VERSION "$Format:%h$"

NS_ :

BS_:

BU_: APB APP APS BCCEN BDY DAS DBG EAS EPAS EPAS2 EPAS3S EPB EPBM ESP GTW GTWU IBST IC MCU OCS PARK PARK3 RADAR RCM RT3000 SCCM SDM SEC TAS TAS2 TAS2DBG TOOL TPMS VCSEATD VCSEATP

BO_ 841 DAS_warningMatrix3: 8 DAS
 SG_ DAS_w193_camWindshieldUnclean : 0|1@1+ (1,0) [0|0] "" GTW,MCU
 SG_ DAS_w194_accDriverResumeRqrd : 1|1@1+ (1,0) [0|0] "" GTW,MCU
 SG_ DAS_w195_scwUnavailable : 2|1@1+ (1,0) [0|0] "" GTW,MCU
 SG_ DAS_w196_stopSignWarning : 3|1@1+ (1,0) [0|0] "" GTW,MCU
 SG_ DAS_w197_redLightWarning : 4|1@1+ (1,0) [0|0] "" GTW,MCU
 SG_ DAS_w198_tsrUnavailable : 5|1@1+ (1,0) [0|0] "" GTW,MCU
 SG_ DAS_w199_apcAbort : 6|1@1+ (1,0) [0|0] "" GTW,MCU
 SG_ DAS_w200_lcSlowdown : 7|1@1+ (1,0) [0|0] "" GTW,MCU
 SG_ DAS_w201_lcAborting : 8|1@1+ (1,0) [0|0] "" GTW,MCU
 SG_ DAS_w202_scwNoisyEnvironment : 9|1@1+ (1,0) [0|0] "" GTW,MCU
 SG_ DAS_w203_apcActivation : 10|1@1+ (1,0) [0|0] "" GTW,MCU
 SG_ DAS_w204_apcFinalFront : 11|1@1+ (1,0) [0|0] "" GTW,MCU
 SG_ DAS_w205_apcFinalRear : 12|1@1+ (1,0) [0|0] "" GTW,MCU
 SG_ DAS_w206_autosteerNotEnabled : 13|1@1+ (1,0) [0|0] "" GTW,MCU
 SG_ DAS_w207_autosteerUnavailable : 14|1@1+ (1,0) [0|0] "" GTW,MCU
 SG_ DAS_w208_rackDetected : 15|1@1+ (1,0) [0|0] "" GTW,MCU
 SG_ DAS_w209_autoSummonRequest : 16|1@1+ (1,0) [0|0] "" GTW,MCU
 SG_ DAS_w210_camObstrcted : 17|1@1+ (1,0) [0|0] "" GTW,MCU
 SG_ DAS_w211_accNoSeatBelt : 18|1@1+ (1,0) [0|0] "" GTW,MCU
 SG_ DAS_w212_lcUnavailableStrikeOut : 19|1@1+ (1,0) [0|0] "" GTW,MCU
 SG_ DAS_w213_autosteerStruckOut : 20|1@1+ (1,0) [0|0] "" GTW,MCU
 SG_ DAS_w214_driverNotIntracting : 21|1@1+ (1,0) [0|0] "" GTW,MCU
 SG_ DAS_w215_contDriverNotIntracting : 22|1@1+ (1,0) [0|0] "" GTW,MCU
 SG_ DAS_w216_driverOverriding : 23|1@1+ (1,0) [0|0] "" GTW,MCU
 SG_ DAS_w217_lcUnavailableSpeeding : 24|1@1+ (1,0) [0|0] "" GTW,MCU
 SG_ DAS_w218_lcSpeedExceededLimit : 25|1@1+ (1,0) [0|0] "" GTW,MCU
 SG_ DAS_w219_lcTempUnavailableSpeed : 26|1@1+ (1,0) [0|0] "" GTW,MCU
 SG_ DAS_w220_lcTempUnavailableRoad : 27|1@1+ (1,0) [0|0] "" GTW,MCU
 SG_ DAS_w221_accRadarBlind : 28|1@1+ (1,0) [0|0] "" GTW,MCU
 SG_ DAS_w222_accCameraBlind : 29|1@1+ (1,0) [0|0] "" GTW,MCU
 SG_ DAS_w223_accObjectInPath : 30|1@1+ (1,0) [0|0] "" GTW,MCU
 SG_ DAS_w224_accCameraCalibration : 31|1@1+ (1,0) [0|0] "" GTW,MCU
 SG_ DAS_w225_lcDegradedVisSpeedLmt : 32|1@1+ (1,0) [0|0] "" GTW,MCU
 SG_ DAS_w226_lcCamCalNeededSpeedLmt : 33|1@1+ (1,0) [0|0] "" GTW,MCU
 SG_ DAS_w227_virtualWallBlocked : 34|1@1+ (1,0) [0|0] "" GTW,MCU
 SG_ DAS_w228_DEPRECATED : 35|1@1+ (1,0) [0|0] "" GTW,MCU
 SG_ DAS_w229_alcUltrasoundDamaged : 36|1@1+ (1,0) [0|1] "" GTW,MCU
 SG_ DAS_w230_alcUltrasoundBlocked : 37|1@1+ (1,0) [0|1] "" GTW,MCU
 SG_ DAS_w231_idfEvent : 38|1@1+ (1,0) [0|1] "" GTW,MCU
 SG_ DAS_w232_laneChangeRequested : 39|1@1+ (1,0) [0|1] "" GTW,MCU
 SG_ DAS_w233_laneChangeCancelled : 40|1@1+ (1,0) [0|1] "" GTW,MCU

BO_ 1797 DBG_CH_Test_ID: 1 TOOL
 SG_ DBG_CH_Test_ID : 0|8@1+ (1,0) [0|0] "" Vector__XXX

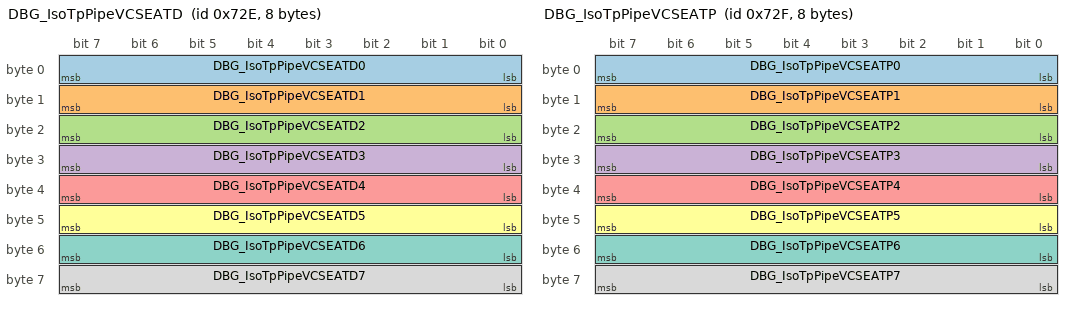
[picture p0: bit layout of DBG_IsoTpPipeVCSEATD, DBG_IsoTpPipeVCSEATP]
BO_ 1838 DBG_IsoTpPipeVCSEATD: 8 DBG
 SG_ DBG_IsoTpPipeVCSEATD0 : 0|8@1+ (1,0) [0|255] "" VCSEATD
 SG_ DBG_IsoTpPipeVCSEATD1 : 8|8@1+ (1,0) [0|255] "" VCSEATD
 SG_ DBG_IsoTpPipeVCSEATD2 : 16|8@1+ (1,0) [0|255] "" VCSEATD
 SG_ DBG_IsoTpPipeVCSEATD3 : 24|8@1+ (1,0) [0|255] "" VCSEATD
 SG_ DBG_IsoTpPipeVCSEATD4 : 32|8@1+ (1,0) [0|255] "" VCSEATD
 SG_ DBG_IsoTpPipeVCSEATD5 : 40|8@1+ (1,0) [0|255] "" VCSEATD
 SG_ DBG_IsoTpPipeVCSEATD6 : 48|8@1+ (1,0) [0|255] "" VCSEATD
 SG_ DBG_IsoTpPipeVCSEATD7 : 56|8@1+ (1,0) [0|255] "" VCSEATD

BO_ 1839 DBG_IsoTpPipeVCSEATP: 8 DBG
 SG_ DBG_IsoTpPipeVCSEATP0 : 0|8@1+ (1,0) [0|255] "" VCSEATP
 SG_ DBG_IsoTpPipeVCSEATP1 : 8|8@1+ (1,0) [0|255] "" VCSEATP
 SG_ DBG_IsoTpPipeVCSEATP2 : 16|8@1+ (1,0) [0|255] "" VCSEATP
 SG_ DBG_IsoTpPipeVCSEATP3 : 24|8@1+ (1,0) [0|255] "" VCSEATP
 SG_ DBG_IsoTpPipeVCSEATP4 : 32|8@1+ (1,0) [0|255] "" VCSEATP
 SG_ DBG_IsoTpPipeVCSEATP5 : 40|8@1+ (1,0) [0|255] "" VCSEATP
 SG_ DBG_IsoTpPipeVCSEATP6 : 48|8@1+ (1,0) [0|255] "" VCSEATP
 SG_ DBG_IsoTpPipeVCSEATP7 : 56|8@1+ (1,0) [0|255] "" VCSEATP

BO_ 1801 DBG_IsotermAP: 8 DBG
 SG_ DBG_IsotermAP : 0|64@1+ (1,0) [0|0] "" DAS

BO_ 1833 DBG_IsotermSMS: 8 DBG
 SG_ DBG_IsotermSMS : 0|64@1+ (1,0) [0|0] "" DAS

BO_ 1089 DG_RQ_GLOBAL_UDS: 8 GTW
 SG_ DG_RQ_GLOBAL_UDS : 7|64@0+ (1,0) [0|0] "" SCCM

BO_ 1803 DIAG_01: 8 GTW
 SG_ D_RQ_LC : 0|64@1+ (1,0) [0|0] "" EAS

BO_ 1820 DIAG_02: 8 GTW
 SG_ D_RQ_SPC : 0|64@1+ (1,0) [0|0] "" EAS

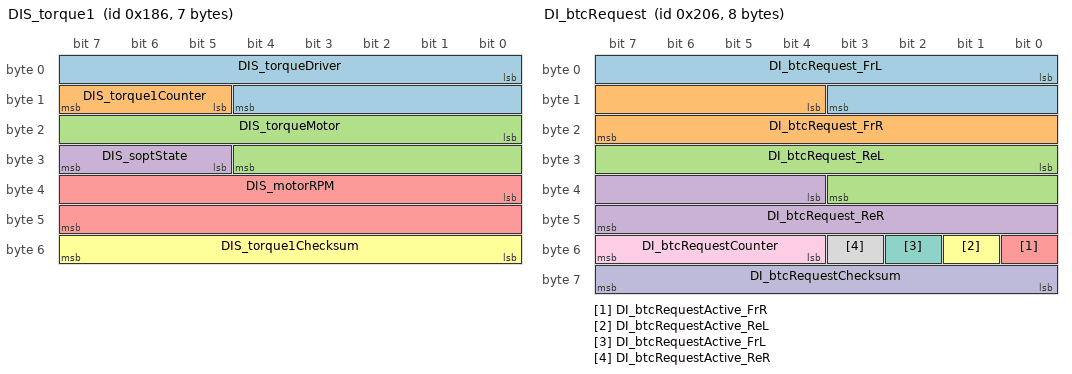
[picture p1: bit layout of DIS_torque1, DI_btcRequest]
BO_ 390 DIS_torque1: 7 GTW
 SG_ DIS_torqueDriver : 0|13@1- (0.25,0) [-750|750] "Nm" ESP
 SG_ DIS_torque1Counter : 13|3@1+ (1,0) [0|0] "" ESP,TAS2
 SG_ DIS_torqueMotor : 16|13@1- (0.25,0) [-750|750] "Nm" ESP,TAS2
 SG_ DIS_soptState : 29|3@1+ (1,0) [0|0] "" DBG
 SG_ DIS_motorRPM : 32|16@1- (1,0) [-17000|17000] "RPM" ESP,TAS2
 SG_ DIS_torque1Checksum : 48|8@1+ (1,0) [0|0] "" ESP,TAS2

BO_ 518 DI_btcRequest: 8 GTW
 SG_ DI_btcRequest_FrL : 0|12@1+ (2,0) [0|8190] "Nm" ESP
 SG_ DI_btcRequest_FrR : 12|12@1+ (2,0) [0|8190] "Nm" ESP
 SG_ DI_btcRequest_ReL : 24|12@1+ (2,0) [0|8190] "Nm" ESP
 SG_ DI_btcRequest_ReR : 36|12@1+ (2,0) [0|8190] "Nm" ESP
 SG_ DI_btcRequestActive_FrR : 48|1@1+ (1,0) [0|1] "" ESP
 SG_ DI_btcRequestActive_ReL : 49|1@1+ (1,0) [0|1] "" ESP
 SG_ DI_btcRequestActive_FrL : 50|1@1+ (1,0) [0|1] "" ESP
 SG_ DI_btcRequestActive_ReR : 51|1@1+ (1,0) [0|1] "" ESP
 SG_ DI_btcRequestCounter : 52|4@1+ (1,0) [0|0] "" ESP
 SG_ DI_btcRequestChecksum : 56|8@1+ (1,0) [0|0] "" ESP

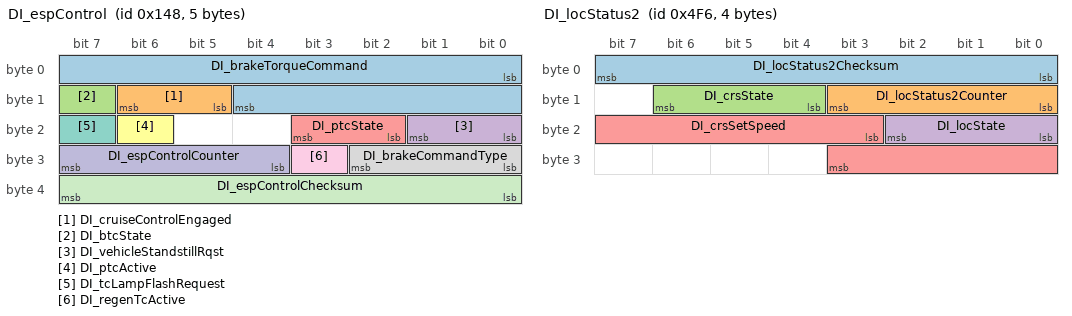
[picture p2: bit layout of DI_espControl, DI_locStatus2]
BO_ 328 DI_espControl: 5 GTW
 SG_ DI_brakeTorqueCommand : 0|13@1+ (2,0) [0|16382] "Nm" ESP,TAS2
 SG_ DI_cruiseControlEngaged : 13|2@1+ (1,0) [0|0] "" Vector__XXX
 SG_ DI_btcState : 15|1@1+ (1,0) [0|0] "" Vector__XXX
 SG_ DI_vehicleStandstillRqst : 16|2@1+ (1,0) [0|0] "" ESP
 SG_ DI_ptcState : 18|2@1+ (1,0) [0|0] "" ESP,TAS2
 SG_ DI_ptcActive : 22|1@1+ (1,0) [0|0] "" ESP,DAS,RADAR,TAS2
 SG_ DI_tcLampFlashRequest : 23|1@1+ (1,0) [0|0] "" ESP
 SG_ DI_brakeCommandType : 24|3@1+ (1,0) [0|0] "" ESP
 SG_ DI_regenTcActive : 27|1@1+ (1,0) [0|0] "" RADAR
 SG_ DI_espControlCounter : 28|4@1+ (1,0) [0|0] "" ESP,TAS2
 SG_ DI_espControlChecksum : 32|8@1+ (1,0) [0|0] "" ESP,TAS2

BO_ 1270 DI_locStatus2: 4 GTW
 SG_ DI_locStatus2Checksum : 0|8@1+ (1,0) [0|255] "" Vector__XXX
 SG_ DI_locStatus2Counter : 8|4@1+ (1,0) [0|15] "" Vector__XXX
 SG_ DI_crsState : 12|3@1+ (1,0) [0|7] "" Vector__XXX
 SG_ DI_locState : 16|3@1+ (1,0) [0|7] "" Vector__XXX
 SG_ DI_crsSetSpeed : 19|9@1+ (0.5,0) [0|255.5] "kph" Vector__XXX

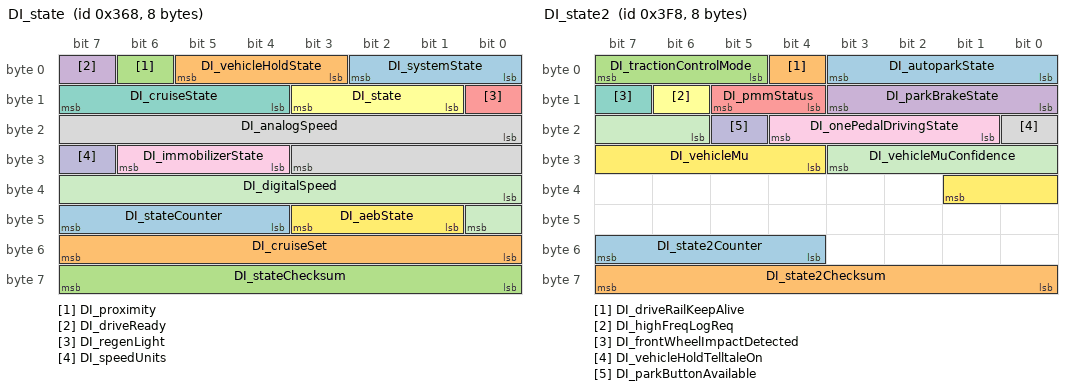
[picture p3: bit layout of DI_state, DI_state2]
BO_ 872 DI_state: 8 GTW
 SG_ DI_systemState : 0|3@1+ (1,0) [0|0] "" RCM
 SG_ DI_vehicleHoldState : 3|3@1+ (1,0) [0|0] "" Vector__XXX
 SG_ DI_proximity : 6|1@1+ (1,0) [0|0] "" Vector__XXX
 SG_ DI_driveReady : 7|1@1+ (1,0) [0|0] "" Vector__XXX
 SG_ DI_regenLight : 8|1@1+ (1,0) [0|0] "" BDY,BCCEN,DAS
 SG_ DI_state : 9|3@1+ (1,0) [0|0] "" RCM
 SG_ DI_cruiseState : 12|4@1+ (1,0) [0|0] "" DAS,EPB,EPBM
 SG_ DI_analogSpeed : 16|12@1+ (0.1,0) [0|409.4] "speed" Vector__XXX
 SG_ DI_immobilizerState : 28|3@1+ (1,0) [0|0] "" Vector__XXX
 SG_ DI_speedUnits : 31|1@1+ (1,0) [0|1] "" DAS,TAS
 SG_ DI_digitalSpeed : 32|9@1+ (1,0) [0|280] "" DAS,RCM,TAS
 SG_ DI_aebState : 41|3@1+ (1,0) [0|0] "" DAS
 SG_ DI_stateCounter : 44|4@1+ (1,0) [0|0] "" RCM,TAS
 SG_ DI_cruiseSet : 48|8@1+ (1,0) [0|250] "speed" DAS
 SG_ DI_stateChecksum : 56|8@1+ (1,0) [0|0] "" RCM,TAS

BO_ 1016 DI_state2: 8 GTW
 SG_ DI_autoparkState : 0|4@1+ (1,0) [0|15] "" DAS,EPB,EPBM
 SG_ DI_driveRailKeepAlive : 4|1@1+ (1,0) [0|1] "" Vector__XXX
 SG_ DI_tractionControlMode : 5|3@1+ (1,0) [0|0] "" APP,RCM,TAS2
 SG_ DI_parkBrakeState : 8|4@1+ (1,0) [0|15] "" DAS
 SG_ DI_pmmStatus : 12|2@1+ (1,0) [0|3] "" DAS
 SG_ DI_highFreqLogReq : 14|1@1+ (1,0) [0|1] "" DAS
 SG_ DI_frontWheelImpactDetected : 15|1@1+ (1,0) [0|1] "" DAS
 SG_ DI_vehicleHoldTelltaleOn : 16|1@1+ (1,0) [0|1] "" Vector__XXX
 SG_ DI_onePedalDrivingState : 17|4@1+ (1,0) [0|8] "" Vector__XXX
 SG_ DI_parkButtonAvailable : 21|1@1+ (1,0) [0|1] "" Vector__XXX
 SG_ DI_vehicleMuConfidence : 22|6@1+ (0.02,0) [0|1.26] "-" APP
 SG_ DI_vehicleMu : 28|6@1+ (0.024,0) [0|1.512] "-" APP
 SG_ DI_state2Counter : 52|4@1+ (1,0) [0|15] "" TAS2
 SG_ DI_state2Checksum : 56|8@1+ (1,0) [0|255] "" TAS2

BO_ 808 DI_statePartial: 1 GTW
 SG_ DI_regenLightCopy : 0|1@1+ (1,0) [0|0] "" Vector__XXX
 SG_ DI_driveReadyCopy : 1|1@1+ (1,0) [0|0] "" EAS

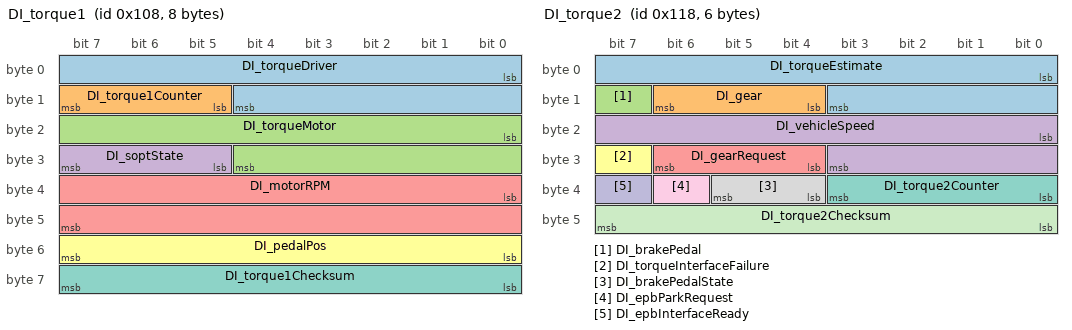
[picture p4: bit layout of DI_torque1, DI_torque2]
BO_ 264 DI_torque1: 8 GTW
 SG_ DI_torqueDriver : 0|13@1- (0.25,0) [-750|750] "Nm" DAS,ESP
 SG_ DI_torque1Counter : 13|3@1+ (1,0) [0|0] "" IBST,SDM,ESP,EPAS,EPAS2,EPAS3S,RCM,TAS2
 SG_ DI_torqueMotor : 16|13@1- (0.25,0) [-750|750] "Nm" APP,APS,ESP,TAS2
 SG_ DI_soptState : 29|3@1+ (1,0) [0|0] "" DBG
 SG_ DI_motorRPM : 32|16@1- (1,0) [-17000|17000] "RPM" IBST,SDM,RCM,ESP,EPAS,EPAS2,EPAS3S,EPB,EPBM,TAS2
 SG_ DI_pedalPos : 48|8@1+ (0.4,0) [0|100] "%" DAS,SDM,ESP,RCM,TAS2
 SG_ DI_torque1Checksum : 56|8@1+ (1,0) [0|0] "" IBST,SDM,ESP,EPAS,EPAS2,EPAS3S,RCM,TAS2

BO_ 280 DI_torque2: 6 GTW
 SG_ DI_torqueEstimate : 0|12@1- (0.5,0) [-750|750] "Nm" APP
 SG_ DI_gear : 12|3@1+ (1,0) [0|0] "" DAS,PARK,SEC,BDY,BCCEN,ESP,EPB,EPBM,TAS,RCM
 SG_ DI_brakePedal : 15|1@1+ (1,0) [0|0] "" DAS,BDY,BCCEN,SDM
 SG_ DI_vehicleSpeed : 16|12@1+ (0.05,-25) [-25|179.75] "MPH" DAS,EPB,EPBM,RCM,TAS
 SG_ DI_gearRequest : 28|3@1+ (1,0) [0|0] "" ESP
 SG_ DI_torqueInterfaceFailure : 31|1@1+ (1,0) [0|0] "" ESP
 SG_ DI_torque2Counter : 32|4@1+ (1,0) [0|0] "" PARK,SDM,RCM,ESP,EPB,EPBM,TAS
 SG_ DI_brakePedalState : 36|2@1+ (1,0) [0|0] "" DAS,SDM,ESP,BCCEN,RCM
 SG_ DI_epbParkRequest : 38|1@1+ (1,0) [0|0] "" EPB,EPBM
 SG_ DI_epbInterfaceReady : 39|1@1+ (1,0) [0|0] "" EPB,EPBM
 SG_ DI_torque2Checksum : 40|8@1+ (1,0) [0|0] "" PARK,SDM,RCM,ESP,EPB,EPBM,TAS

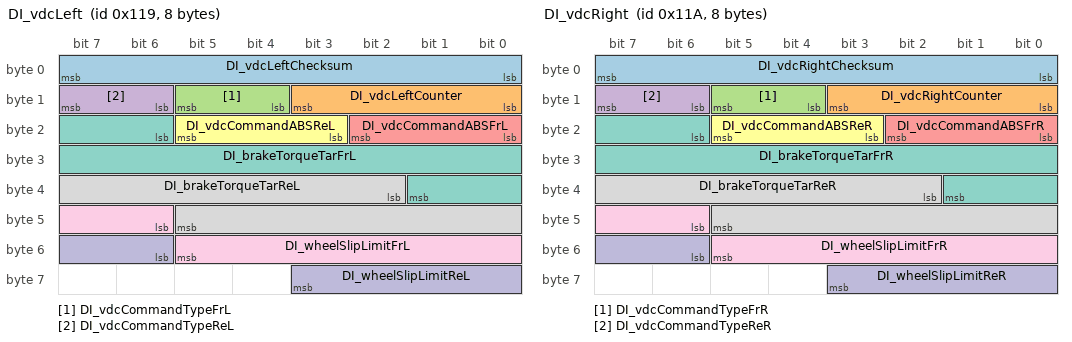
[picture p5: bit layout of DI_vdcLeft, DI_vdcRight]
BO_ 281 DI_vdcLeft: 8 GTW
 SG_ DI_vdcLeftChecksum : 0|8@1+ (1,0) [0|0] "" ESP
 SG_ DI_vdcLeftCounter : 8|4@1+ (1,0) [0|0] "" ESP
 SG_ DI_vdcCommandTypeFrL : 12|2@1+ (1,0) [0|3] "" ESP
 SG_ DI_vdcCommandTypeReL : 14|2@1+ (1,0) [0|3] "" ESP
 SG_ DI_vdcCommandABSFrL : 16|3@1+ (1,0) [0|7] "" ESP
 SG_ DI_vdcCommandABSReL : 19|3@1+ (1,0) [0|7] "" ESP
 SG_ DI_brakeTorqueTarFrL : 22|12@1+ (2,-2) [-2|8188] "Nm" ESP
 SG_ DI_brakeTorqueTarReL : 34|12@1+ (2,-2) [-2|8188] "Nm" ESP
 SG_ DI_wheelSlipLimitFrL : 46|8@1+ (0.004,-0.004) [-0.004|1] "1" ESP
 SG_ DI_wheelSlipLimitReL : 54|6@1+ (0.004,-0.004) [-0.004|0.25] "1" ESP

BO_ 282 DI_vdcRight: 8 GTW
 SG_ DI_vdcRightChecksum : 0|8@1+ (1,0) [0|0] "" ESP
 SG_ DI_vdcRightCounter : 8|4@1+ (1,0) [0|0] "" ESP
 SG_ DI_vdcCommandTypeFrR : 12|2@1+ (1,0) [0|3] "" ESP
 SG_ DI_vdcCommandTypeReR : 14|2@1+ (1,0) [0|3] "" ESP
 SG_ DI_vdcCommandABSFrR : 16|3@1+ (1,0) [0|7] "" ESP
 SG_ DI_vdcCommandABSReR : 19|3@1+ (1,0) [0|7] "" ESP
 SG_ DI_brakeTorqueTarFrR : 22|12@1+ (2,-2) [-2|8188] "Nm" ESP
 SG_ DI_brakeTorqueTarReR : 34|12@1+ (2,-2) [-2|8188] "Nm" ESP
 SG_ DI_wheelSlipLimitFrR : 46|8@1+ (0.004,-0.004) [-0.004|1] "1" ESP
 SG_ DI_wheelSlipLimitReR : 54|6@1+ (0.004,-0.004) [-0.004|0.25] "1" ESP

BO_ 512 DPM_STAT: 1 GTW
 SG_ DPM_MdLmt_Rq : 0|2@1+ (1,0) [0|0] "" SCCM
 SG_ DPM_ExtMd_Enbl_Rq : 2|2@1+ (1,0) [0|0] "" SCCM

BO_ 1570 D_RQ_SCCM: 8 GTW
 SG_ D_RQ_SCCM : 7|64@0+ (1,0) [0|0] "" SCCM

BO_ 1156 D_RS_SCCM: 8 SCCM
 SG_ D_RS_SCCM : 7|64@0+ (1,0) [0|0] "" GTW

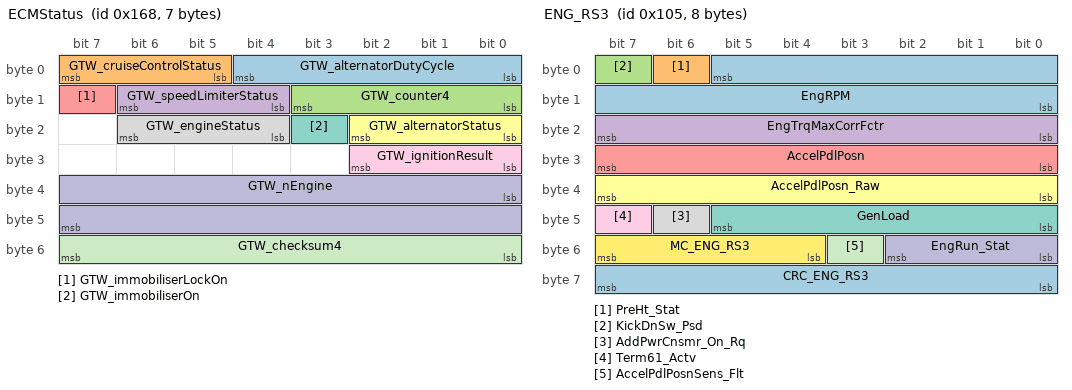
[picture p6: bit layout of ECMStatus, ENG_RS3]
BO_ 360 ECMStatus: 7 GTW
 SG_ GTW_alternatorDutyCycle : 0|5@1+ (3.125,0) [0|96.875] "%" Vector__XXX
 SG_ GTW_cruiseControlStatus : 5|3@1+ (1,0) [0|7] "" Vector__XXX
 SG_ GTW_counter4 : 8|4@1+ (1,0) [0|15] "" BDY,SEC,BCCEN
 SG_ GTW_speedLimiterStatus : 12|3@1+ (1,0) [0|7] "" Vector__XXX
 SG_ GTW_immobiliserLockOn : 15|1@1+ (1,0) [0|1] "" Vector__XXX
 SG_ GTW_alternatorStatus : 16|3@1+ (1,0) [0|7] "" Vector__XXX
 SG_ GTW_immobiliserOn : 19|1@1+ (1,0) [0|1] "" Vector__XXX
 SG_ GTW_engineStatus : 20|3@1+ (1,0) [0|7] "" Vector__XXX
 SG_ GTW_ignitionResult : 24|3@1+ (1,0) [0|7] "" Vector__XXX
 SG_ GTW_nEngine : 32|16@1+ (0.25,0) [0|16383.75] "rpm" BDY,SEC,BCCEN
 SG_ GTW_checksum4 : 48|8@1+ (1,0) [0|255] "" BDY,SEC,BCCEN

BO_ 527 EFUSE_status: 8 GTW
 SG_ EFUSE_state_DCDC : 0|1@1+ (1,0) [0|1] "" Vector__XXX
 SG_ EFUSE_state_iBooster : 1|1@1+ (1,0) [0|1] "" Vector__XXX
 SG_ EFUSE_state_EPAS1 : 2|1@1+ (1,0) [0|1] "" Vector__XXX
 SG_ EFUSE_state_cabinBEC : 3|1@1+ (1,0) [0|1] "" Vector__XXX
 SG_ EFUSE_state_vbatFused : 4|1@1+ (1,0) [0|1] "" Vector__XXX
 SG_ EFUSE_state_HCU_ESP_ABS : 5|1@1+ (1,0) [0|1] "" Vector__XXX
 SG_ EFUSE_state_frunkBEC : 6|1@1+ (1,0) [0|1] "" Vector__XXX
 SG_ EFUSE_state_EPAS2 : 7|1@1+ (1,0) [0|1] "" Vector__XXX
 SG_ EFUSE_state_revBatt : 8|1@1+ (1,0) [0|1] "" Vector__XXX
 SG_ EFUSE_fault_iBooster : 9|1@1+ (1,0) [0|1] "" Vector__XXX
 SG_ EFUSE_fault_EPAS1 : 10|1@1+ (1,0) [0|1] "" Vector__XXX
 SG_ EFUSE_fault_cabinBEC : 11|1@1+ (1,0) [0|1] "" Vector__XXX
 SG_ EFUSE_fault_vbatFused : 12|1@1+ (1,0) [0|1] "" Vector__XXX
 SG_ EFUSE_fault_HCU_ESP_ABS : 13|1@1+ (1,0) [0|1] "" Vector__XXX
 SG_ EFUSE_fault_EPAS2 : 14|1@1+ (1,0) [0|1] "" Vector__XXX
 SG_ EFUSE_fault_frunkBEC : 15|1@1+ (1,0) [0|1] "" Vector__XXX
 SG_ EFUSE_fault_DCDC : 16|1@1+ (1,0) [0|1] "" Vector__XXX
 SG_ EFUSE_fault_revBatt : 17|1@1+ (1,0) [0|1] "" Vector__XXX
 SG_ EFUSE_fault_condenserFan : 18|1@1+ (1,0) [0|1] "" Vector__XXX
 SG_ EFUSE_state_condenserFan : 19|1@1+ (1,0) [0|1] "" Vector__XXX
 SG_ EFUSE_efuseFaulted : 20|1@1+ (1,0) [0|1] "" Vector__XXX
 SG_ EFUSE_airCompressorStatus : 38|3@1+ (1,0) [0|7] "" TAS
 SG_ EFUSE_5VARailStable : 41|1@1+ (1,0) [0|1] "" Vector__XXX
 SG_ EFUSE_5VBRailStable : 42|1@1+ (1,0) [0|1] "" Vector__XXX
 SG_ EFUSE_12VARailStable : 43|1@1+ (1,0) [0|1] "" Vector__XXX
 SG_ EFUSE_12VBRailStable : 44|1@1+ (1,0) [0|1] "" Vector__XXX
 SG_ EFUSE_ChargePumpVoltageStable : 45|1@1+ (1,0) [0|1] "" Vector__XXX
 SG_ EFUSE_loadshedStatus : 46|2@1+ (1,0) [0|3] "" Vector__XXX
 SG_ EFUSE_lockout : 48|1@1+ (1,0) [0|1] "" Vector__XXX
 SG_ EFUSE_toDCDCEnable : 49|1@1+ (1,0) [0|1] "" Vector__XXX
 SG_ EFUSE_statusCounter : 52|4@1+ (1,0) [0|15] "" TAS
 SG_ EFUSE_statusChecksum : 56|8@1+ (1,0) [0|255] "" TAS

BO_ 1 EIS_A1: 8 GTW
 SG_ ISw_Stat : 0|3@1+ (1,0) [0|0] "" SCCM
 SG_ Ign_On_StProc_Inact : 3|1@1+ (1,0) [0|0] "" Vector__XXX
 SG_ TxPkPosn_Rq : 4|1@1+ (1,0) [0|0] "" Vector__XXX
 SG_ TxPkPosn_Emg_Rq : 5|1@1+ (1,0) [0|0] "" Vector__XXX
 SG_ TxPkPosnAuto_Enbl : 6|1@1+ (1,0) [0|0] "" Vector__XXX
 SG_ TxPkPosn_Rq_SBC_Enbl : 7|1@1+ (1,0) [0|0] "" Vector__XXX
 SG_ KG_IgnCtrl_Actv : 8|1@1+ (1,0) [0|0] "" Vector__XXX
 SG_ EngSt_Enbl_Rq_KG : 9|1@1+ (1,0) [0|0] "" Vector__XXX
 SG_ KG_StSw_Psd : 10|1@1+ (1,0) [0|0] "" Vector__XXX
 SG_ AutoDrLk_Rq_Src : 14|2@1+ (1,0) [0|0] "" Vector__XXX
 SG_ AutoDrLk_Stat : 20|2@1+ (1,0) [0|0] "" Vector__XXX
 SG_ SPCR_Conf_EIS : 24|2@1+ (1,0) [0|0] "" Vector__XXX
 SG_ CLkS_DL_Stat : 28|2@1+ (1,0) [0|0] "" Vector__XXX
 SG_ CLkS_Gas_Dr_Stat : 30|2@1+ (1,0) [0|0] "" Vector__XXX
 SG_ CLkS_Dr_FL_Stat : 32|2@1+ (1,0) [0|0] "" Vector__XXX
 SG_ CLkS_Dr_FR_Stat : 34|2@1+ (1,0) [0|0] "" Vector__XXX
 SG_ CLkS_Dr_RL_Stat : 36|2@1+ (1,0) [0|0] "" Vector__XXX
 SG_ CLkS_Dr_RR_Stat : 38|2@1+ (1,0) [0|0] "" Vector__XXX
 SG_ KeyLine1_Appr : 40|1@1+ (1,0) [0|0] "" Vector__XXX
 SG_ KeyLine2_Appr : 41|1@1+ (1,0) [0|0] "" Vector__XXX
 SG_ KeyLine3_Appr : 42|1@1+ (1,0) [0|0] "" Vector__XXX
 SG_ KeyLine4_Appr : 43|1@1+ (1,0) [0|0] "" Vector__XXX
 SG_ KeyLine5_Appr : 44|1@1+ (1,0) [0|0] "" Vector__XXX
 SG_ KeyLine6_Appr : 45|1@1+ (1,0) [0|0] "" Vector__XXX
 SG_ KeyLine7_Appr : 46|1@1+ (1,0) [0|0] "" Vector__XXX
 SG_ KeyLine8_Appr : 47|1@1+ (1,0) [0|0] "" Vector__XXX
 SG_ CLkS_Lk_Stat3 : 48|3@1+ (1,0) [0|0] "" Vector__XXX
 SG_ SPCR_AcustWarn_Rq_EIS : 51|1@1+ (1,0) [0|0] "" Vector__XXX
 SG_ MC_EIS_A1 : 52|4@1+ (1,0) [0|15] "" Vector__XXX
 SG_ CRC_EIS_A1 : 56|8@1+ (1,0) [0|0] "" Vector__XXX

BO_ 261 ENG_RS3: 8 GTW
 SG_ EngRPM : 5|14@0+ (1,0) [0|16382] "rpm" Vector__XXX
 SG_ PreHt_Stat : 6|1@0+ (1,0) [0|0] "" Vector__XXX
 SG_ KickDnSw_Psd : 7|1@0+ (1,0) [0|0] "" Vector__XXX
 SG_ EngTrqMaxCorrFctr : 23|8@0+ (0.0078,0) [0|1.98] "" Vector__XXX
 SG_ AccelPdlPosn : 31|8@0+ (0.4,0) [0|100] "%" Vector__XXX
 SG_ AccelPdlPosn_Raw : 39|8@0+ (0.4,0) [0|100] "%" Vector__XXX
 SG_ GenLoad : 45|6@0+ (3.22581,0) [0|100] "%" Vector__XXX
 SG_ AddPwrCnsmr_On_Rq : 46|1@0+ (1,0) [0|0] "" Vector__XXX
 SG_ Term61_Actv : 47|1@0+ (1,0) [0|0] "" Vector__XXX
 SG_ EngRun_Stat : 50|3@0+ (1,0) [0|0] "" SCCM
 SG_ AccelPdlPosnSens_Flt : 51|1@0+ (1,0) [0|0] "" Vector__XXX
 SG_ MC_ENG_RS3 : 55|4@0+ (1,0) [0|15] "" Vector__XXX
 SG_ CRC_ENG_RS3 : 63|8@0+ (1,0) [0|0] "" Vector__XXX

BO_ 1472 EPAS2_alertLog: 8 EPAS2
 SG_ EPAS2_alertID M : 0|15@1+ (1,0) [0|0] "" GTW
 SG_ EPAS2_alertType : 15|1@1+ (1,0) [0|0] "" GTW
 SG_ EPAS2_d074_eacCancelMtrq m16458 : 16|10@1+ (0.01,0) [0|10.23] "Nm" GTW
 SG_ EPAS2_d074_eacCancelTtrq m16458 : 26|10@1+ (0.05,-25) [-25|26.15] "Nm" GTW
 SG_ EPAS2_d074_eacCancelAngleGrad m16458 : 36|12@1+ (1,-2048) [-2048|2047] "deg/s" GTW
 SG_ EPAS2_d074_eacCancelAngle m16458 : 48|12@1+ (1,-2048) [-2048|2047] "deg" GTW
 SG_ EPAS2_d074_eacCancelCode m16458 : 60|4@1+ (1,0) [0|0] "" GTW

BO_ 912 EPAS2_dtcMatrix: 8 EPAS2
 SG_ EPAS2_matrixIndex M : 0|8@1+ (1,0) [0|255] "" GTW
 SG_ EPAS2_d001_csuFail m0 : 8|2@1+ (1,0) [0|0] "" GTW
 SG_ EPAS2_d002_csvFail m0 : 10|2@1+ (1,0) [0|0] "" GTW
 SG_ EPAS2_d003_runningReset m0 : 12|2@1+ (1,0) [0|0] "" GTW
 SG_ EPAS2_d004_gateDriverEn m0 : 14|2@1+ (1,0) [0|0] "" GTW
 SG_ EPAS2_d005_subTx m0 : 16|2@1+ (1,0) [0|0] "" GTW
 SG_ EPAS2_d006_rlyOpen m0 : 18|2@1+ (1,0) [0|0] "" GTW
 SG_ EPAS2_d007_rlyShort m0 : 20|2@1+ (1,0) [0|0] "" GTW
 SG_ EPAS2_d008_programFlow m0 : 22|2@1+ (1,0) [0|0] "" GTW
 SG_ EPAS2_d009_sentCrcError2 m0 : 24|2@1+ (1,0) [0|0] "" GTW
 SG_ EPAS2_d010_sentCrcError1 m0 : 26|2@1+ (1,0) [0|0] "" GTW
 SG_ EPAS2_d011_sentTimeOut2 m0 : 28|2@1+ (1,0) [0|0] "" GTW
 SG_ EPAS2_d012_sentTimeOut1 m0 : 30|2@1+ (1,0) [0|0] "" GTW
 SG_ EPAS2_d013_sentDiff m0 : 32|2@1+ (1,0) [0|0] "" GTW
 SG_ EPAS2_d014_sent2 m0 : 34|2@1+ (1,0) [0|0] "" GTW
 SG_ EPAS2_d015_sent1 m0 : 36|2@1+ (1,0) [0|0] "" GTW
 SG_ EPAS2_d016_sentSyncTime2 m0 : 38|2@1+ (1,0) [0|0] "" GTW
 SG_ EPAS2_d017_sentSyncTime1 m0 : 40|2@1+ (1,0) [0|0] "" GTW
 SG_ EPAS2_d018_compatibleId m0 : 42|2@1+ (1,0) [0|0] "" GTW
 SG_ EPAS2_d019_mainInterlock m0 : 44|2@1+ (1,0) [0|0] "" GTW
 SG_ EPAS2_d020_posAbs m0 : 46|2@1+ (1,0) [0|0] "" GTW
 SG_ EPAS2_d021_strokeOv m0 : 48|2@1+ (1,0) [0|0] "" GTW
 SG_ EPAS2_d022_motIdiff m0 : 50|2@1+ (1,0) [0|0] "" GTW
 SG_ EPAS2_d023_motOvc m0 : 52|2@1+ (1,0) [0|0] "" GTW
 SG_ EPAS2_d024_gndFault m0 : 54|2@1+ (1,0) [0|0] "" GTW
 SG_ EPAS2_d025_motShort m0 : 56|2@1+ (1,0) [0|0] "" GTW
 SG_ EPAS2_d026_motOpen m0 : 58|2@1+ (1,0) [0|0] "" GTW
 SG_ EPAS2_d027_svcc5 m0 : 60|2@1+ (1,0) [0|0] "" GTW
 SG_ EPAS2_d028_svcc52 m0 : 62|2@1+ (1,0) [0|0] "" GTW
 SG_ EPAS2_d029_variantCheck m1 : 8|2@1+ (1,0) [0|0] "" GTW
 SG_ EPAS2_d030_batSigOpen m1 : 10|2@1+ (1,0) [0|0] "" GTW
 SG_ EPAS2_d031_offsetOver m1 : 12|2@1+ (1,0) [0|0] "" GTW
 SG_ EPAS2_d032_subSpiTime m1 : 14|2@1+ (1,0) [0|0] "" GTW
 SG_ EPAS2_d033_subWatchdog m1 : 16|2@1+ (1,0) [0|0] "" GTW
 SG_ EPAS2_d034_batUv m1 : 18|2@1+ (1,0) [0|0] "" GTW
 SG_ EPAS2_d035_batOv m1 : 20|2@1+ (1,0) [0|0] "" GTW
 SG_ EPAS2_d036_posInc m1 : 22|2@1+ (1,0) [0|0] "" GTW
 SG_ EPAS2_d037_precharge m1 : 24|2@1+ (1,0) [0|0] "" GTW
 SG_ EPAS2_d038_ceOpen m1 : 26|2@1+ (1,0) [0|0] "" GTW
 SG_ EPAS2_d039_prechargeWl m1 : 28|2@1+ (1,0) [0|0] "" GTW
 SG_ EPAS2_d040_offsetDiff m1 : 30|2@1+ (1,0) [0|0] "" GTW
 SG_ EPAS2_d041_tempSensError m1 : 32|2@1+ (1,0) [0|0] "" GTW
 SG_ EPAS2_d042_overHeatProtect m1 : 34|2@1+ (1,0) [0|0] "" GTW
 SG_ EPAS2_d043_eepromError m1 : 36|2@1+ (1,0) [0|0] "" GTW
 SG_ EPAS2_d044_trqSensCal m1 : 38|2@1+ (1,0) [0|0] "" GTW
 SG_ EPAS2_d045_currentSensCal m1 : 40|2@1+ (1,0) [0|0] "" GTW
 SG_ EPAS2_d046_canBusOff m1 : 42|2@1+ (1,0) [0|0] "" GTW
 SG_ EPAS2_d047_dasMia m1 : 44|2@1+ (1,0) [0|0] "" GTW
 SG_ EPAS2_d048_dasCntError m1 : 46|2@1+ (1,0) [0|0] "" GTW
 SG_ EPAS2_d049_dasCsError m1 : 48|2@1+ (1,0) [0|0] "" GTW
 SG_ EPAS2_d050_espWsMia m1 : 50|2@1+ (1,0) [0|0] "" GTW
 SG_ EPAS2_d051_espWsCntError m1 : 52|2@1+ (1,0) [0|0] "" GTW
 SG_ EPAS2_d052_espWsCsError m1 : 54|2@1+ (1,0) [0|0] "" GTW
 SG_ EPAS2_d053_espbMia m1 : 56|2@1+ (1,0) [0|0] "" GTW
 SG_ EPAS2_d054_espbCntError m1 : 58|2@1+ (1,0) [0|0] "" GTW
 SG_ EPAS2_d055_espbCsError m1 : 60|2@1+ (1,0) [0|0] "" GTW
 SG_ EPAS2_d056_espbQf m1 : 62|2@1+ (1,0) [0|0] "" GTW
 SG_ EPAS2_d057_espcMia m2 : 8|2@1+ (1,0) [0|0] "" GTW
 SG_ EPAS2_d058_espcCntError m2 : 10|2@1+ (1,0) [0|0] "" GTW
 SG_ EPAS2_d059_espcCsError m2 : 12|2@1+ (1,0) [0|0] "" GTW
 SG_ EPAS2_d060_espcQf m2 : 14|2@1+ (1,0) [0|0] "" GTW
 SG_ EPAS2_d061_gtwMia m2 : 16|2@1+ (1,0) [0|0] "" GTW
 SG_ EPAS2_d062_gtwCntError m2 : 18|2@1+ (1,0) [0|0] "" GTW
 SG_ EPAS2_d063_gtwCsError m2 : 20|2@1+ (1,0) [0|0] "" GTW
 SG_ EPAS2_d064_epbMia m2 : 22|2@1+ (1,0) [0|0] "" GTW
 SG_ EPAS2_d065_epbCntError m2 : 24|2@1+ (1,0) [0|0] "" GTW
 SG_ EPAS2_d066_epbCsError m2 : 26|2@1+ (1,0) [0|0] "" GTW
 SG_ EPAS2_d067_diMia m2 : 28|2@1+ (1,0) [0|0] "" GTW
 SG_ EPAS2_d068_diCntError m2 : 30|2@1+ (1,0) [0|0] "" GTW
 SG_ EPAS2_d069_diCsError m2 : 32|2@1+ (1,0) [0|0] "" GTW
 SG_ EPAS2_d070_sasMia m2 : 34|2@1+ (1,0) [0|0] "" GTW
 SG_ EPAS2_d071_sasCntError m2 : 36|2@1+ (1,0) [0|0] "" GTW
 SG_ EPAS2_d072_sasCsError m2 : 38|2@1+ (1,0) [0|0] "" GTW
 SG_ EPAS2_d073_sasStat m2 : 40|2@1+ (1,0) [0|0] "" GTW
 SG_ EPAS2_d074_eacCancelled m2 : 42|2@1+ (1,0) [0|0] "" GTW
 SG_ EPAS2_d075_espWsQf m2 : 44|2@1+ (1,0) [0|0] "" GTW
 SG_ EPAS2_d076_gtwOdoMia m2 : 46|2@1+ (1,0) [0|0] "" GTW
 SG_ EPAS2_d077_pinionVelDiff m2 : 48|2@1+ (1,0) [0|0] "" GTW
 SG_ EPAS2_d078_can2BusOff m2 : 50|2@1+ (1,0) [0|0] "" GTW
 SG_ EPAS2_d079_espPrivate1Mia m2 : 52|2@1+ (1,0) [0|0] "" GTW
 SG_ EPAS2_d080_abnormalShutdown m2 : 54|2@1+ (1,0) [0|0] "" GTW

BO_ 1426 EPAS3P_alertLog: 8 APS
 SG_ EPAS3P_alertID M : 0|15@1+ (1,0) [0|0] "" GTW
 SG_ EPAS3P_alertType : 15|1@1+ (1,0) [0|0] "" GTW
 SG_ EPAS3P_d081_eacCancelMtrq m16468 : 16|10@1+ (0.01,0) [0|10.23] "Nm" GTW
 SG_ EPAS3P_d081_eacCancelTtrq m16468 : 26|10@1+ (0.05,-25) [-25|26.15] "Nm" GTW
 SG_ EPAS3P_d081_eacCancelAngleGrad m16468 : 36|12@1+ (1,-2048) [-2048|2047] "deg/s" GTW
 SG_ EPAS3P_d081_eacCancelAngle m16468 : 48|12@1+ (1,-2048) [-2048|2047] "deg" GTW
 SG_ EPAS3P_d081_eacCancelCode m16468 : 60|4@1+ (1,0) [0|0] "" GTW

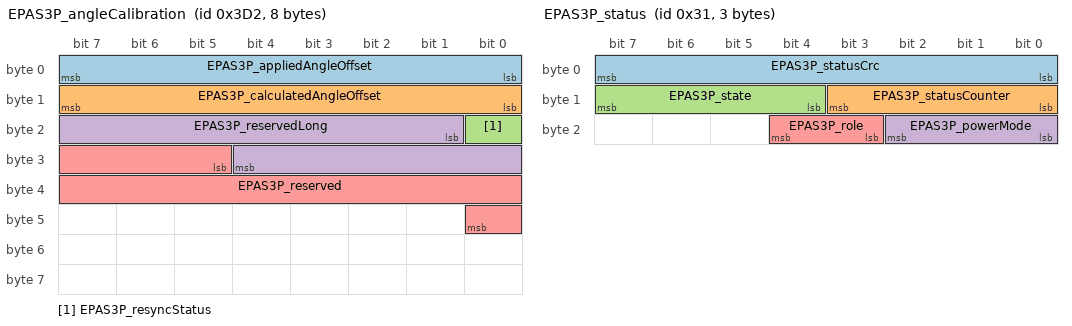
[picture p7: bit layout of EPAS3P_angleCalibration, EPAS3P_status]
BO_ 978 EPAS3P_angleCalibration: 8 APS
 SG_ EPAS3P_appliedAngleOffset : 0|8@1+ (0.1,-12.8) [-12.8|12.7] "deg" GTW
 SG_ EPAS3P_calculatedAngleOffset : 8|8@1+ (0.1,-12.8) [-12.8|12.7] "deg" GTW
 SG_ EPAS3P_resyncStatus : 16|1@1+ (1,0) [0|1] "" GTW
 SG_ EPAS3P_reservedLong : 17|12@1+ (0.01,-10) [-10|10] "Nm" GTW
 SG_ EPAS3P_reserved : 29|12@1+ (0.01,-10) [-10|10] "Nm" GTW

BO_ 914 EPAS3P_dtcMatrix: 8 APS
 SG_ EPAS3P_matrixIndex M : 0|8@1+ (1,0) [0|255] "" GTW
 SG_ EPAS3P_d001_sent1Mia m0 : 8|2@1+ (1,0) [0|0] "" GTW
 SG_ EPAS3P_d002_sent1Error m0 : 10|2@1+ (1,0) [0|0] "" GTW
 SG_ EPAS3P_d003_trqSens1Supply m0 : 12|2@1+ (1,0) [0|0] "" GTW
 SG_ EPAS3P_d004_trqSens1Eeprom m0 : 14|2@1+ (1,0) [0|0] "" GTW
 SG_ EPAS3P_d005_sent2Mia m0 : 16|2@1+ (1,0) [0|0] "" GTW
 SG_ EPAS3P_d006_sent2Error m0 : 18|2@1+ (1,0) [0|0] "" GTW
 SG_ EPAS3P_d007_trqSens2Supply m0 : 20|2@1+ (1,0) [0|0] "" GTW
 SG_ EPAS3P_d008_trqSens2Eeprom m0 : 22|2@1+ (1,0) [0|0] "" GTW
 SG_ EPAS3P_d009_sentDiff m0 : 24|2@1+ (1,0) [0|0] "" GTW
 SG_ EPAS3P_d010_trqSensCalError m0 : 26|2@1+ (1,0) [0|0] "" GTW
 SG_ EPAS3P_d011_currentSensError m0 : 28|2@1+ (1,0) [0|0] "" GTW
 SG_ EPAS3P_d012_currentSensCalError m0 : 30|2@1+ (1,0) [0|0] "" GTW
 SG_ EPAS3P_d013_gateDriveError m0 : 32|2@1+ (1,0) [0|0] "" GTW
 SG_ EPAS3P_d014_gateDriveTxError m0 : 34|2@1+ (1,0) [0|0] "" GTW
 SG_ EPAS3P_d015_gateDriveEeprom m0 : 36|2@1+ (1,0) [0|0] "" GTW
 SG_ EPAS3P_d016_phaseUhighUv m0 : 38|2@1+ (1,0) [0|0] "" GTW
 SG_ EPAS3P_d017_phaseUlowUv m0 : 40|2@1+ (1,0) [0|0] "" GTW
 SG_ EPAS3P_d018_phaseVhighUv m0 : 42|2@1+ (1,0) [0|0] "" GTW
 SG_ EPAS3P_d019_phaseVlowUv m0 : 44|2@1+ (1,0) [0|0] "" GTW
 SG_ EPAS3P_d020_phaseWhighUv m0 : 46|2@1+ (1,0) [0|0] "" GTW
 SG_ EPAS3P_d021_phaseWlowUv m0 : 48|2@1+ (1,0) [0|0] "" GTW
 SG_ EPAS3P_d022_phaseUhighOv m0 : 50|2@1+ (1,0) [0|0] "" GTW
 SG_ EPAS3P_d023_phaseUlowOv m0 : 52|2@1+ (1,0) [0|0] "" GTW
 SG_ EPAS3P_d024_phaseVhighOv m0 : 54|2@1+ (1,0) [0|0] "" GTW
 SG_ EPAS3P_d025_phaseVlowOv m0 : 56|2@1+ (1,0) [0|0] "" GTW
 SG_ EPAS3P_d026_phaseWhighOv m0 : 58|2@1+ (1,0) [0|0] "" GTW
 SG_ EPAS3P_d027_phaseWlowOv m0 : 60|2@1+ (1,0) [0|0] "" GTW
 SG_ EPAS3P_d028_phaseUbootUv m0 : 62|2@1+ (1,0) [0|0] "" GTW
 SG_ EPAS3P_d029_phaseVbootUv m1 : 8|2@1+ (1,0) [0|0] "" GTW
 SG_ EPAS3P_d030_phaseWbootUv m1 : 10|2@1+ (1,0) [0|0] "" GTW
 SG_ EPAS3P_d031_abnormalShutdown m1 : 12|2@1+ (1,0) [0|0] "" GTW
 SG_ EPAS3P_d032_vRegOutputUv m1 : 14|2@1+ (1,0) [0|0] "" GTW
 SG_ EPAS3P_d033_vRegOutputOv m1 : 16|2@1+ (1,0) [0|0] "" GTW
 SG_ EPAS3P_d034_vRegError m1 : 18|2@1+ (1,0) [0|0] "" GTW
 SG_ EPAS3P_d035_vbbSupplyUv m1 : 20|2@1+ (1,0) [0|0] "" GTW
 SG_ EPAS3P_d036_vbbSupplyOv m1 : 22|2@1+ (1,0) [0|0] "" GTW
 SG_ EPAS3P_d037_motPos1ParityError m1 : 24|2@1+ (1,0) [0|0] "" GTW
 SG_ EPAS3P_d038_motPos1Uv m1 : 26|2@1+ (1,0) [0|0] "" GTW
 SG_ EPAS3P_d039_motPos1MagnetMia m1 : 28|2@1+ (1,0) [0|0] "" GTW
 SG_ EPAS3P_d040_motPos1LogicError m1 : 30|2@1+ (1,0) [0|0] "" GTW
 SG_ EPAS3P_d041_motPos1tempError m1 : 32|2@1+ (1,0) [0|0] "" GTW
 SG_ EPAS3P_d042_motPos2ParityError m1 : 34|2@1+ (1,0) [0|0] "" GTW
 SG_ EPAS3P_d043_motPos2Uv m1 : 36|2@1+ (1,0) [0|0] "" GTW
 SG_ EPAS3P_d044_motPos2MagnetMia m1 : 38|2@1+ (1,0) [0|0] "" GTW
 SG_ EPAS3P_d045_motPos2LogicError m1 : 40|2@1+ (1,0) [0|0] "" GTW
 SG_ EPAS3P_d046_motPos2tempError m1 : 42|2@1+ (1,0) [0|0] "" GTW
 SG_ EPAS3P_d047_motPosCorrError m1 : 44|2@1+ (1,0) [0|0] "" GTW
 SG_ EPAS3P_d048_motPosCalError m1 : 46|2@1+ (1,0) [0|0] "" GTW
 SG_ EPAS3P_d049_piCtrlError m1 : 48|2@1+ (1,0) [0|0] "" GTW
 SG_ EPAS3P_d050_mcuSmuError m1 : 50|2@1+ (1,0) [0|0] "" GTW
 SG_ EPAS3P_d051_mcuSupError m1 : 52|2@1+ (1,0) [0|0] "" GTW
 SG_ EPAS3P_d052_intWatchdogError m1 : 54|2@1+ (1,0) [0|0] "" GTW
 SG_ EPAS3P_d053_extWatchdogError m1 : 56|2@1+ (1,0) [0|0] "" GTW
 SG_ EPAS3P_d054_memoryProtectError m1 : 58|2@1+ (1,0) [0|0] "" GTW
 SG_ EPAS3P_d055_floatPointError m1 : 60|2@1+ (1,0) [0|0] "" GTW
 SG_ EPAS3P_d056_battUv m1 : 62|2@1+ (1,0) [0|0] "" GTW
 SG_ EPAS3P_d057_battUvReduced m2 : 8|2@1+ (1,0) [0|0] "" GTW
 SG_ EPAS3P_d058_battOv m2 : 10|2@1+ (1,0) [0|0] "" GTW
 SG_ EPAS3P_d059_battOvReduced m2 : 12|2@1+ (1,0) [0|0] "" GTW
 SG_ EPAS3P_d060_battBridgeDiff m2 : 14|2@1+ (1,0) [0|0] "" GTW
 SG_ EPAS3P_d061_bridgeUv m2 : 16|2@1+ (1,0) [0|0] "" GTW
 SG_ EPAS3P_d062_assistCorrError m2 : 18|2@1+ (1,0) [0|0] "" GTW
 SG_ EPAS3P_d063_dampCorrError m2 : 20|2@1+ (1,0) [0|0] "" GTW
 SG_ EPAS3P_d064_phaseCompCorrError m2 : 22|2@1+ (1,0) [0|0] "" GTW
 SG_ EPAS3P_d065_trqTarCorrError m2 : 24|2@1+ (1,0) [0|0] "" GTW
 SG_ EPAS3P_d066_returnCorrError m2 : 26|2@1+ (1,0) [0|0] "" GTW
 SG_ EPAS3P_d067_yawDampCorrError m2 : 28|2@1+ (1,0) [0|0] "" GTW
 SG_ EPAS3P_d068_hystCorrError m2 : 30|2@1+ (1,0) [0|0] "" GTW
 SG_ EPAS3P_d069_eacCorrError m2 : 32|2@1+ (1,0) [0|0] "" GTW
 SG_ EPAS3P_d070_hodCorrError m2 : 34|2@1+ (1,0) [0|0] "" GTW
 SG_ EPAS3P_d071_vehSpdCorrError m2 : 36|2@1+ (1,0) [0|0] "" GTW
 SG_ EPAS3P_d072_motFeedFwdError m2 : 38|2@1+ (1,0) [0|0] "" GTW
 SG_ EPAS3P_d073_motParEstError m2 : 40|2@1+ (1,0) [0|0] "" GTW
 SG_ EPAS3P_d074_overHeatProtect m2 : 42|2@1+ (1,0) [0|0] "" GTW
 SG_ EPAS3P_d075_fspPwrCut m2 : 44|2@1+ (1,0) [0|0] "" GTW
 SG_ EPAS3P_d076_tempSensOutofRange m2 : 46|2@1+ (1,0) [0|0] "" GTW
 SG_ EPAS3P_d077_highSideFetError m2 : 48|2@1+ (1,0) [0|0] "" GTW
 SG_ EPAS3P_d078_phaseDisconnectError m2 : 50|2@1+ (1,0) [0|0] "" GTW
 SG_ EPAS3P_d079_backupCurrentPlaus m2 : 52|2@1+ (1,0) [0|0] "" GTW
 SG_ EPAS3P_d080_ecuInitArbError m2 : 54|2@1+ (1,0) [0|0] "" GTW
 SG_ EPAS3P_d081_coggCompError m2 : 56|2@1+ (1,0) [0|0] "" GTW
 SG_ EPAS3P_d082_polarityCalError m2 : 58|2@1+ (1,0) [0|0] "" GTW
 SG_ EPAS3P_d083_crcMismatch m2 : 60|2@1+ (1,0) [0|0] "" GTW
 SG_ EPAS3P_d084_eacCancelled m2 : 62|2@1+ (1,0) [0|0] "" GTW
 SG_ EPAS3P_d085_canBusOff m3 : 8|2@1+ (1,0) [0|0] "" GTW
 SG_ EPAS3P_d086_dasMia m3 : 10|2@1+ (1,0) [0|0] "" GTW
 SG_ EPAS3P_d087_dasCntError m3 : 12|2@1+ (1,0) [0|0] "" GTW
 SG_ EPAS3P_d088_dasCsError m3 : 14|2@1+ (1,0) [0|0] "" GTW
 SG_ EPAS3P_d089_espWsMia m3 : 16|2@1+ (1,0) [0|0] "" GTW
 SG_ EPAS3P_d090_espWsCntError m3 : 18|2@1+ (1,0) [0|0] "" GTW
 SG_ EPAS3P_d091_espWsCsError m3 : 20|2@1+ (1,0) [0|0] "" GTW
 SG_ EPAS3P_d092_espbMia m3 : 22|2@1+ (1,0) [0|0] "" GTW
 SG_ EPAS3P_d093_espbCntError m3 : 24|2@1+ (1,0) [0|0] "" GTW
 SG_ EPAS3P_d094_espbCsError m3 : 26|2@1+ (1,0) [0|0] "" GTW
 SG_ EPAS3P_d095_espbQf m3 : 28|2@1+ (1,0) [0|0] "" GTW
 SG_ EPAS3P_d096_espcMia m3 : 30|2@1+ (1,0) [0|0] "" GTW
 SG_ EPAS3P_d097_espcCntError m3 : 32|2@1+ (1,0) [0|0] "" GTW
 SG_ EPAS3P_d098_espcCsError m3 : 34|2@1+ (1,0) [0|0] "" GTW
 SG_ EPAS3P_d099_espcQf m3 : 36|2@1+ (1,0) [0|0] "" GTW
 SG_ EPAS3P_d100_gtwMia m3 : 38|2@1+ (1,0) [0|0] "" GTW
 SG_ EPAS3P_d101_gtwCntError m3 : 40|2@1+ (1,0) [0|0] "" GTW
 SG_ EPAS3P_d102_gtwCsError m3 : 42|2@1+ (1,0) [0|0] "" GTW
 SG_ EPAS3P_d103_apsMia m3 : 44|2@1+ (1,0) [0|0] "" GTW
 SG_ EPAS3P_d104_apsCntError m3 : 46|2@1+ (1,0) [0|0] "" GTW
 SG_ EPAS3P_d105_apsCsError m3 : 48|2@1+ (1,0) [0|0] "" GTW
 SG_ EPAS3P_d106_diMia m3 : 50|2@1+ (1,0) [0|0] "" GTW
 SG_ EPAS3P_d107_diCntError m3 : 52|2@1+ (1,0) [0|0] "" GTW
 SG_ EPAS3P_d108_diCsError m3 : 54|2@1+ (1,0) [0|0] "" GTW
 SG_ EPAS3P_d109_sasMia m3 : 56|2@1+ (1,0) [0|0] "" GTW
 SG_ EPAS3P_d110_sasCntError m3 : 58|2@1+ (1,0) [0|0] "" GTW
 SG_ EPAS3P_d111_sasCsError m3 : 60|2@1+ (1,0) [0|0] "" GTW
 SG_ EPAS3P_d112_sasStatError m3 : 62|2@1+ (1,0) [0|0] "" GTW
 SG_ EPAS3P_d113_espWsQf m4 : 8|2@1+ (1,0) [0|0] "" GTW
 SG_ EPAS3P_d114_gtwOdoMia m4 : 10|2@1+ (1,0) [0|0] "" GTW
 SG_ EPAS3P_d115_ecuStatMia m4 : 12|2@1+ (1,0) [0|0] "" GTW
 SG_ EPAS3P_d116_ecuStatCntError m4 : 14|2@1+ (1,0) [0|0] "" GTW
 SG_ EPAS3P_d117_ecuStatCrcError m4 : 16|2@1+ (1,0) [0|0] "" GTW
 SG_ EPAS3P_d118_espPriv1Mia m4 : 18|2@1+ (1,0) [0|0] "" GTW
 SG_ EPAS3P_d119_espPriv1CntError m4 : 20|2@1+ (1,0) [0|0] "" GTW
 SG_ EPAS3P_d120_espPriv1CsError m4 : 22|2@1+ (1,0) [0|0] "" GTW
 SG_ EPAS3P_d121_espPriv1Qf m4 : 24|2@1+ (1,0) [0|0] "" GTW
 SG_ EPAS3P_d122_privateBusOff m4 : 26|2@1+ (1,0) [0|0] "" GTW
 SG_ EPAS3P_d123_pvtEcuStatMia m4 : 28|2@1+ (1,0) [0|0] "" GTW
 SG_ EPAS3P_d124_pvtEcuStatCntError m4 : 30|2@1+ (1,0) [0|0] "" GTW
 SG_ EPAS3P_d125_pvtEcuStatCrcError m4 : 32|2@1+ (1,0) [0|0] "" GTW
 SG_ EPAS3P_d126_olpActive m4 : 34|2@1+ (1,0) [0|0] "" GTW
 SG_ EPAS3P_d127_combEcu2StatFail m4 : 36|2@1+ (1,0) [0|0] "" GTW
 SG_ EPAS3P_d128_tempSensStuckInRange m4 : 38|2@1+ (1,0) [0|0] "" GTW
 SG_ EPAS3P_d129_trqSensTrimOutRange m4 : 40|2@1+ (1,0) [0|0] "" GTW
 SG_ EPAS3P_d130_combEcu1StatFail m4 : 42|2@1+ (1,0) [0|0] "" GTW
 SG_ EPAS3P_d131_sasOffsetNotCal m4 : 44|2@1+ (1,0) [0|0] "" GTW
 SG_ EPAS3P_d132_phaseFeedbackError m4 : 46|2@1+ (1,0) [0|0] "" GTW

BO_ 817 EPAS3P_info: 8 APS
 SG_ EPAS3P_infoIndex M : 0|8@1+ (1,0) [0|0] "" GTW
 SG_ EPAS3P_infoBuildType m10 : 8|8@1+ (1,0) [0|0] "" GTW
 SG_ EPAS3P_infoComponentID m10 : 48|16@1+ (1,0) [0|0] "" GTW
 SG_ EPAS3P_infoPcbaID m11 : 16|8@1+ (1,0) [0|0] "" GTW
 SG_ EPAS3P_infoAssemblyID m11 : 24|8@1+ (1,0) [0|255] "" GTW
 SG_ EPAS3P_infoUsageID m11 : 32|16@1+ (1,0) [0|65535] "" GTW
 SG_ EPAS3P_infoApplicationCRC m13 : 32|32@1+ (1,0) [0|0] "" GTW
 SG_ EPAS3P_infoBootUdsProtoVersion m20 : 8|8@1+ (1,0) [0|0] "" GTW
 SG_ EPAS3P_infoBootloaderCRC m20 : 32|32@1+ (1,0) [0|0] "" GTW

BO_ 49 EPAS3P_status: 3 APS
 SG_ EPAS3P_statusCrc : 0|8@1+ (1,0) [0|255] "" EPAS3S
 SG_ EPAS3P_statusCounter : 8|4@1+ (1,0) [0|15] "" EPAS3S
 SG_ EPAS3P_state : 12|4@1+ (1,0) [0|15] "" EPAS3S,GTW
 SG_ EPAS3P_powerMode : 16|3@1+ (1,0) [0|7] "" EPAS3S,GTW
 SG_ EPAS3P_role : 19|2@1+ (1,0) [0|2] "" EPAS3S,GTW

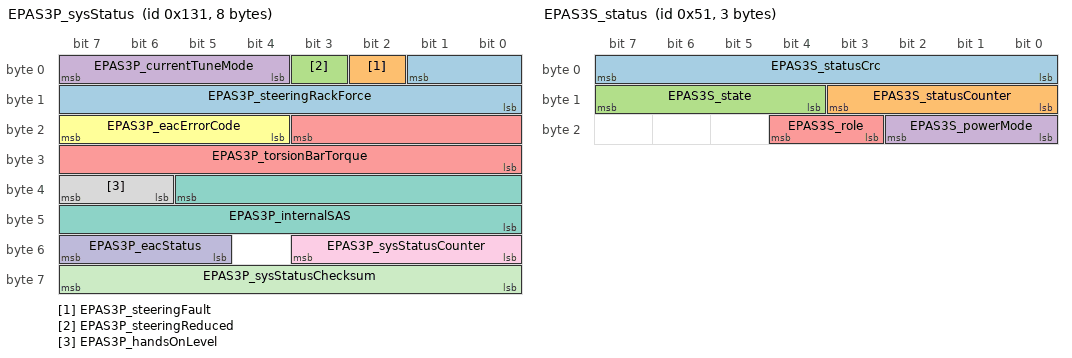
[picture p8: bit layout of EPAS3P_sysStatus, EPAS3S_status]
BO_ 305 EPAS3P_sysStatus: 8 APS
 SG_ EPAS3P_steeringRackForce : 1|10@0+ (50,-25575) [-25575|25575] "N" GTW
 SG_ EPAS3P_steeringFault : 2|1@0+ (1,0) [0|1] "" GTW
 SG_ EPAS3P_steeringReduced : 3|1@0+ (1,0) [0|1] "" GTW
 SG_ EPAS3P_currentTuneMode : 7|4@0+ (1,0) [0|0] "" GTW
 SG_ EPAS3P_torsionBarTorque : 19|12@0+ (0.01,-20.5) [-20.5|20.45] "Nm" GTW
 SG_ EPAS3P_eacErrorCode : 23|4@0+ (1,0) [0|15] "" GTW
 SG_ EPAS3P_internalSAS : 37|14@0+ (0.1,-819.2) [-819.2|819] "deg" GTW
 SG_ EPAS3P_handsOnLevel : 39|2@0+ (1,0) [0|3] "" GTW
 SG_ EPAS3P_sysStatusCounter : 51|4@0+ (1,0) [0|15] "" GTW
 SG_ EPAS3P_eacStatus : 55|3@0+ (1,0) [0|7] "" GTW
 SG_ EPAS3P_sysStatusChecksum : 63|8@0+ (1,0) [0|255] "" GTW

BO_ 1592 EPAS3P_udsResponseCH: 8 DAS
 SG_ EPAS3P_udsResponseDataCH : 7|64@0+ (1,0) [0|1.84467440737095E+19] "" GTW

BO_ 1425 EPAS3S_alertLog: 8 EPAS3S
 SG_ EPAS3S_alertID M : 0|15@1+ (1,0) [0|0] "" GTW
 SG_ EPAS3S_alertType : 15|1@1+ (1,0) [0|0] "" GTW
 SG_ EPAS3S_d081_eacCancelMtrq m16468 : 16|10@1+ (0.01,0) [0|10.23] "Nm" GTW
 SG_ EPAS3S_d081_eacCancelTtrq m16468 : 26|10@1+ (0.05,-25) [-25|26.15] "Nm" GTW
 SG_ EPAS3S_d081_eacCancelAngleGrad m16468 : 36|12@1+ (1,-2048) [-2048|2047] "deg/s" GTW
 SG_ EPAS3S_d081_eacCancelAngle m16468 : 48|12@1+ (1,-2048) [-2048|2047] "deg" GTW
 SG_ EPAS3S_d081_eacCancelCode m16468 : 60|4@1+ (1,0) [0|0] "" GTW

BO_ 1361 EPAS3S_bootID: 8 EPAS3S
 SG_ EPAS3S_bootIdData00 : 0|32@1+ (1,0) [0|4294967295] "" GTW
 SG_ EPAS3S_bootIdData01 : 32|32@1+ (1,0) [0|4294967295] "" GTW

BO_ 913 EPAS3S_dtcMatrix: 8 EPAS3S
 SG_ EPAS3S_matrixIndex M : 0|8@1+ (1,0) [0|255] "" GTW
 SG_ EPAS3S_d001_sent1Mia m0 : 8|2@1+ (1,0) [0|0] "" GTW
 SG_ EPAS3S_d002_sent1Error m0 : 10|2@1+ (1,0) [0|0] "" GTW
 SG_ EPAS3S_d003_trqSens1Supply m0 : 12|2@1+ (1,0) [0|0] "" GTW
 SG_ EPAS3S_d004_trqSens1Eeprom m0 : 14|2@1+ (1,0) [0|0] "" GTW
 SG_ EPAS3S_d005_sent2Mia m0 : 16|2@1+ (1,0) [0|0] "" GTW
 SG_ EPAS3S_d006_sent2Error m0 : 18|2@1+ (1,0) [0|0] "" GTW
 SG_ EPAS3S_d007_trqSens2Supply m0 : 20|2@1+ (1,0) [0|0] "" GTW
 SG_ EPAS3S_d008_trqSens2Eeprom m0 : 22|2@1+ (1,0) [0|0] "" GTW
 SG_ EPAS3S_d009_sentDiff m0 : 24|2@1+ (1,0) [0|0] "" GTW
 SG_ EPAS3S_d010_trqSensCalError m0 : 26|2@1+ (1,0) [0|0] "" GTW
 SG_ EPAS3S_d011_currentSensError m0 : 28|2@1+ (1,0) [0|0] "" GTW
 SG_ EPAS3S_d012_currentSensCalError m0 : 30|2@1+ (1,0) [0|0] "" GTW
 SG_ EPAS3S_d013_gateDriveError m0 : 32|2@1+ (1,0) [0|0] "" GTW
 SG_ EPAS3S_d014_gateDriveTxError m0 : 34|2@1+ (1,0) [0|0] "" GTW
 SG_ EPAS3S_d015_gateDriveEeprom m0 : 36|2@1+ (1,0) [0|0] "" GTW
 SG_ EPAS3S_d016_phaseUhighUv m0 : 38|2@1+ (1,0) [0|0] "" GTW
 SG_ EPAS3S_d017_phaseUlowUv m0 : 40|2@1+ (1,0) [0|0] "" GTW
 SG_ EPAS3S_d018_phaseVhighUv m0 : 42|2@1+ (1,0) [0|0] "" GTW
 SG_ EPAS3S_d019_phaseVlowUv m0 : 44|2@1+ (1,0) [0|0] "" GTW
 SG_ EPAS3S_d020_phaseWhighUv m0 : 46|2@1+ (1,0) [0|0] "" GTW
 SG_ EPAS3S_d021_phaseWlowUv m0 : 48|2@1+ (1,0) [0|0] "" GTW
 SG_ EPAS3S_d022_phaseUhighOv m0 : 50|2@1+ (1,0) [0|0] "" GTW
 SG_ EPAS3S_d023_phaseUlowOv m0 : 52|2@1+ (1,0) [0|0] "" GTW
 SG_ EPAS3S_d024_phaseVhighOv m0 : 54|2@1+ (1,0) [0|0] "" GTW
 SG_ EPAS3S_d025_phaseVlowOv m0 : 56|2@1+ (1,0) [0|0] "" GTW
 SG_ EPAS3S_d026_phaseWhighOv m0 : 58|2@1+ (1,0) [0|0] "" GTW
 SG_ EPAS3S_d027_phaseWlowOv m0 : 60|2@1+ (1,0) [0|0] "" GTW
 SG_ EPAS3S_d028_phaseUbootUv m0 : 62|2@1+ (1,0) [0|0] "" GTW
 SG_ EPAS3S_d029_phaseVbootUv m1 : 8|2@1+ (1,0) [0|0] "" GTW
 SG_ EPAS3S_d030_phaseWbootUv m1 : 10|2@1+ (1,0) [0|0] "" GTW
 SG_ EPAS3S_d031_abnormalShutdown m1 : 12|2@1+ (1,0) [0|0] "" GTW
 SG_ EPAS3S_d032_vRegOutputUv m1 : 14|2@1+ (1,0) [0|0] "" GTW
 SG_ EPAS3S_d033_vRegOutputOv m1 : 16|2@1+ (1,0) [0|0] "" GTW
 SG_ EPAS3S_d034_vRegError m1 : 18|2@1+ (1,0) [0|0] "" GTW
 SG_ EPAS3S_d035_vbbSupplyUv m1 : 20|2@1+ (1,0) [0|0] "" GTW
 SG_ EPAS3S_d036_vbbSupplyOv m1 : 22|2@1+ (1,0) [0|0] "" GTW
 SG_ EPAS3S_d037_motPos1ParityError m1 : 24|2@1+ (1,0) [0|0] "" GTW
 SG_ EPAS3S_d038_motPos1Uv m1 : 26|2@1+ (1,0) [0|0] "" GTW
 SG_ EPAS3S_d039_motPos1MagnetMia m1 : 28|2@1+ (1,0) [0|0] "" GTW
 SG_ EPAS3S_d040_motPos1LogicError m1 : 30|2@1+ (1,0) [0|0] "" GTW
 SG_ EPAS3S_d041_motPos1tempError m1 : 32|2@1+ (1,0) [0|0] "" GTW
 SG_ EPAS3S_d042_motPos2ParityError m1 : 34|2@1+ (1,0) [0|0] "" GTW
 SG_ EPAS3S_d043_motPos2Uv m1 : 36|2@1+ (1,0) [0|0] "" GTW
 SG_ EPAS3S_d044_motPos2MagnetMia m1 : 38|2@1+ (1,0) [0|0] "" GTW
 SG_ EPAS3S_d045_motPos2LogicError m1 : 40|2@1+ (1,0) [0|0] "" GTW
 SG_ EPAS3S_d046_motPos2tempError m1 : 42|2@1+ (1,0) [0|0] "" GTW
 SG_ EPAS3S_d047_motPosCorrError m1 : 44|2@1+ (1,0) [0|0] "" GTW
 SG_ EPAS3S_d048_motPosCalError m1 : 46|2@1+ (1,0) [0|0] "" GTW
 SG_ EPAS3S_d049_piCtrlError m1 : 48|2@1+ (1,0) [0|0] "" GTW
 SG_ EPAS3S_d050_mcuSmuError m1 : 50|2@1+ (1,0) [0|0] "" GTW
 SG_ EPAS3S_d051_mcuSupError m1 : 52|2@1+ (1,0) [0|0] "" GTW
 SG_ EPAS3S_d052_intWatchdogError m1 : 54|2@1+ (1,0) [0|0] "" GTW
 SG_ EPAS3S_d053_extWatchdogError m1 : 56|2@1+ (1,0) [0|0] "" GTW
 SG_ EPAS3S_d054_memoryProtectError m1 : 58|2@1+ (1,0) [0|0] "" GTW
 SG_ EPAS3S_d055_floatPointError m1 : 60|2@1+ (1,0) [0|0] "" GTW
 SG_ EPAS3S_d056_battUv m1 : 62|2@1+ (1,0) [0|0] "" GTW
 SG_ EPAS3S_d057_battUvReduced m2 : 8|2@1+ (1,0) [0|0] "" GTW
 SG_ EPAS3S_d058_battOv m2 : 10|2@1+ (1,0) [0|0] "" GTW
 SG_ EPAS3S_d059_battOvReduced m2 : 12|2@1+ (1,0) [0|0] "" GTW
 SG_ EPAS3S_d060_battBridgeDiff m2 : 14|2@1+ (1,0) [0|0] "" GTW
 SG_ EPAS3S_d061_bridgeUv m2 : 16|2@1+ (1,0) [0|0] "" GTW
 SG_ EPAS3S_d062_assistCorrError m2 : 18|2@1+ (1,0) [0|0] "" GTW
 SG_ EPAS3S_d063_dampCorrError m2 : 20|2@1+ (1,0) [0|0] "" GTW
 SG_ EPAS3S_d064_phaseCompCorrError m2 : 22|2@1+ (1,0) [0|0] "" GTW
 SG_ EPAS3S_d065_trqTarCorrError m2 : 24|2@1+ (1,0) [0|0] "" GTW
 SG_ EPAS3S_d066_returnCorrError m2 : 26|2@1+ (1,0) [0|0] "" GTW
 SG_ EPAS3S_d067_yawDampCorrError m2 : 28|2@1+ (1,0) [0|0] "" GTW
 SG_ EPAS3S_d068_hystCorrError m2 : 30|2@1+ (1,0) [0|0] "" GTW
 SG_ EPAS3S_d069_eacCorrError m2 : 32|2@1+ (1,0) [0|0] "" GTW
 SG_ EPAS3S_d070_hodCorrError m2 : 34|2@1+ (1,0) [0|0] "" GTW
 SG_ EPAS3S_d071_vehSpdCorrError m2 : 36|2@1+ (1,0) [0|0] "" GTW
 SG_ EPAS3S_d072_motFeedFwdError m2 : 38|2@1+ (1,0) [0|0] "" GTW
 SG_ EPAS3S_d073_motParEstError m2 : 40|2@1+ (1,0) [0|0] "" GTW
 SG_ EPAS3S_d074_overHeatProtect m2 : 42|2@1+ (1,0) [0|0] "" GTW
 SG_ EPAS3S_d075_fspPwrCut m2 : 44|2@1+ (1,0) [0|0] "" GTW
 SG_ EPAS3S_d076_tempSensOutofRange m2 : 46|2@1+ (1,0) [0|0] "" GTW
 SG_ EPAS3S_d077_highSideFetError m2 : 48|2@1+ (1,0) [0|0] "" GTW
 SG_ EPAS3S_d078_phaseDisconnectError m2 : 50|2@1+ (1,0) [0|0] "" GTW
 SG_ EPAS3S_d079_backupCurrentPlaus m2 : 52|2@1+ (1,0) [0|0] "" GTW
 SG_ EPAS3S_d080_ecuInitArbError m2 : 54|2@1+ (1,0) [0|0] "" GTW
 SG_ EPAS3S_d081_coggCompError m2 : 56|2@1+ (1,0) [0|0] "" GTW
 SG_ EPAS3S_d082_polarityCalError m2 : 58|2@1+ (1,0) [0|0] "" GTW
 SG_ EPAS3S_d083_crcMismatch m2 : 60|2@1+ (1,0) [0|0] "" GTW
 SG_ EPAS3S_d084_eacCancelled m2 : 62|2@1+ (1,0) [0|0] "" GTW
 SG_ EPAS3S_d085_canBusOff m3 : 8|2@1+ (1,0) [0|0] "" GTW
 SG_ EPAS3S_d086_dasMia m3 : 10|2@1+ (1,0) [0|0] "" GTW
 SG_ EPAS3S_d087_dasCntError m3 : 12|2@1+ (1,0) [0|0] "" GTW
 SG_ EPAS3S_d088_dasCsError m3 : 14|2@1+ (1,0) [0|0] "" GTW
 SG_ EPAS3S_d089_espWsMia m3 : 16|2@1+ (1,0) [0|0] "" GTW
 SG_ EPAS3S_d090_espWsCntError m3 : 18|2@1+ (1,0) [0|0] "" GTW
 SG_ EPAS3S_d091_espWsCsError m3 : 20|2@1+ (1,0) [0|0] "" GTW
 SG_ EPAS3S_d092_espbMia m3 : 22|2@1+ (1,0) [0|0] "" GTW
 SG_ EPAS3S_d093_espbCntError m3 : 24|2@1+ (1,0) [0|0] "" GTW
 SG_ EPAS3S_d094_espbCsError m3 : 26|2@1+ (1,0) [0|0] "" GTW
 SG_ EPAS3S_d095_espbQf m3 : 28|2@1+ (1,0) [0|0] "" GTW
 SG_ EPAS3S_d096_espcMia m3 : 30|2@1+ (1,0) [0|0] "" GTW
 SG_ EPAS3S_d097_espcCntError m3 : 32|2@1+ (1,0) [0|0] "" GTW
 SG_ EPAS3S_d098_espcCsError m3 : 34|2@1+ (1,0) [0|0] "" GTW
 SG_ EPAS3S_d099_espcQf m3 : 36|2@1+ (1,0) [0|0] "" GTW
 SG_ EPAS3S_d100_gtwMia m3 : 38|2@1+ (1,0) [0|0] "" GTW
 SG_ EPAS3S_d101_gtwCntError m3 : 40|2@1+ (1,0) [0|0] "" GTW
 SG_ EPAS3S_d102_gtwCsError m3 : 42|2@1+ (1,0) [0|0] "" GTW
 SG_ EPAS3S_d103_apsMia m3 : 44|2@1+ (1,0) [0|0] "" GTW
 SG_ EPAS3S_d104_apsCntError m3 : 46|2@1+ (1,0) [0|0] "" GTW
 SG_ EPAS3S_d105_apsCsError m3 : 48|2@1+ (1,0) [0|0] "" GTW
 SG_ EPAS3S_d106_diMia m3 : 50|2@1+ (1,0) [0|0] "" GTW
 SG_ EPAS3S_d107_diCntError m3 : 52|2@1+ (1,0) [0|0] "" GTW
 SG_ EPAS3S_d108_diCsError m3 : 54|2@1+ (1,0) [0|0] "" GTW
 SG_ EPAS3S_d109_sasMia m3 : 56|2@1+ (1,0) [0|0] "" GTW
 SG_ EPAS3S_d110_sasCntError m3 : 58|2@1+ (1,0) [0|0] "" GTW
 SG_ EPAS3S_d111_sasCsError m3 : 60|2@1+ (1,0) [0|0] "" GTW
 SG_ EPAS3S_d112_sasStatError m3 : 62|2@1+ (1,0) [0|0] "" GTW
 SG_ EPAS3S_d113_espWsQf m4 : 8|2@1+ (1,0) [0|0] "" GTW
 SG_ EPAS3S_d114_gtwOdoMia m4 : 10|2@1+ (1,0) [0|0] "" GTW
 SG_ EPAS3S_d115_ecuStatMia m4 : 12|2@1+ (1,0) [0|0] "" GTW
 SG_ EPAS3S_d116_ecuStatCntError m4 : 14|2@1+ (1,0) [0|0] "" GTW
 SG_ EPAS3S_d117_ecuStatCrcError m4 : 16|2@1+ (1,0) [0|0] "" GTW
 SG_ EPAS3S_d118_espPriv1Mia m4 : 18|2@1+ (1,0) [0|0] "" GTW
 SG_ EPAS3S_d119_espPriv1CntError m4 : 20|2@1+ (1,0) [0|0] "" GTW
 SG_ EPAS3S_d120_espPriv1CsError m4 : 22|2@1+ (1,0) [0|0] "" GTW
 SG_ EPAS3S_d121_espPriv1Qf m4 : 24|2@1+ (1,0) [0|0] "" GTW
 SG_ EPAS3S_d122_privateBusOff m4 : 26|2@1+ (1,0) [0|0] "" GTW
 SG_ EPAS3S_d123_pvtEcuStatMia m4 : 28|2@1+ (1,0) [0|0] "" GTW
 SG_ EPAS3S_d124_pvtEcuStatCntError m4 : 30|2@1+ (1,0) [0|0] "" GTW
 SG_ EPAS3S_d125_pvtEcuStatCrcError m4 : 32|2@1+ (1,0) [0|0] "" GTW
 SG_ EPAS3S_d126_olpActive m4 : 34|2@1+ (1,0) [0|0] "" GTW
 SG_ EPAS3S_d127_combEcu2StatFail m4 : 36|2@1+ (1,0) [0|0] "" GTW
 SG_ EPAS3S_d128_tempSensStuckInRange m4 : 38|2@1+ (1,0) [0|0] "" GTW
 SG_ EPAS3S_d129_trqSensTrimOutRange m4 : 40|2@1+ (1,0) [0|0] "" GTW
 SG_ EPAS3S_d130_combEcu1StatFail m4 : 42|2@1+ (1,0) [0|0] "" GTW
 SG_ EPAS3S_d131_sasOffsetNotCal m4 : 44|2@1+ (1,0) [0|0] "" GTW
 SG_ EPAS3S_d132_phaseFeedbackError m4 : 46|2@1+ (1,0) [0|0] "" GTW

BO_ 81 EPAS3S_status: 3 EPAS3S
 SG_ EPAS3S_statusCrc : 0|8@1+ (1,0) [0|255] "" APS,APP
 SG_ EPAS3S_statusCounter : 8|4@1+ (1,0) [0|15] "" APS,APP
 SG_ EPAS3S_state : 12|4@1+ (1,0) [0|15] "" APS,APP
 SG_ EPAS3S_powerMode : 16|3@1+ (1,0) [0|7] "" APS,APP
 SG_ EPAS3S_role : 19|2@1+ (1,0) [0|2] "" APS,APP

BO_ 1456 EPAS_alertLog: 8 EPAS
 SG_ EPAS_alertID M : 0|15@1+ (1,0) [0|0] "" GTW
 SG_ EPAS_alertType : 15|1@1+ (1,0) [0|0] "" GTW
 SG_ EPAS_d049_ESRACancelMTorque m16433 : 16|10@1+ (0.01,-5.11) [-5.11|5.12] "Nm" GTW
 SG_ EPAS_d049_ESRACancelTTorque m16433 : 26|10@1+ (0.05,-25) [-25|26.15] "Nm" GTW
 SG_ EPAS_d049_ESRACancelSASGrad m16433 : 36|12@1+ (1,-2048) [-2048|2047] "deg/s" GTW
 SG_ EPAS_d049_ESRACancelSAS m16433 : 48|12@1+ (1,-2048) [-2048|2047] "deg" GTW
 SG_ EPAS_d049_ESRACancelCode m16433 : 60|4@1+ (1,0) [0|0] "" GTW

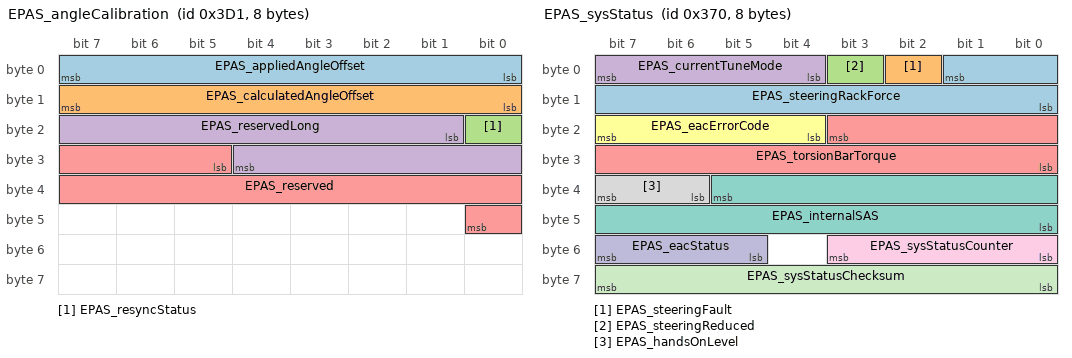
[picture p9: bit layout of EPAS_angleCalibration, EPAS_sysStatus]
BO_ 977 EPAS_angleCalibration: 8 EPAS
 SG_ EPAS_appliedAngleOffset : 0|8@1+ (0.1,-12.8) [-12.8|12.7] "deg" GTW
 SG_ EPAS_calculatedAngleOffset : 8|8@1+ (0.1,-12.8) [-12.8|12.7] "deg" GTW
 SG_ EPAS_resyncStatus : 16|1@1+ (1,0) [0|1] "" GTW
 SG_ EPAS_reservedLong : 17|12@1+ (0.01,-10) [-10|10] "Nm" GTW
 SG_ EPAS_reserved : 29|12@1+ (0.01,-10) [-10|10] "Nm" GTW

BO_ 896 EPAS_dtcMatrix: 8 EPAS
 SG_ EPAS_matrixIndex M : 0|8@1+ (1,0) [0|255] "" GTW
 SG_ EPAS_d001_KFC_STORQUE_0 m0 : 8|2@1+ (1,0) [0|0] "" GTW
 SG_ EPAS_d002_KFC_NVRAM_MNG_READ m0 : 10|2@1+ (1,0) [0|0] "" GTW
 SG_ EPAS_d003_KFC_NVRAM_MNG_WRITE m0 : 12|2@1+ (1,0) [0|0] "" GTW
 SG_ EPAS_d004_KFC_NVRAM_MNG_VERIFY m0 : 14|2@1+ (1,0) [0|0] "" GTW
 SG_ EPAS_d005_KFC_ASIC m0 : 16|2@1+ (1,0) [0|0] "" GTW
 SG_ EPAS_d006_KFC_CLOCKMON m0 : 18|2@1+ (1,0) [0|0] "" GTW
 SG_ EPAS_d007_KFC_OUTPUT_STAGE_DRV m0 : 20|2@1+ (1,0) [0|0] "" GTW
 SG_ EPAS_d008_KFC_SHUT_DOWN m0 : 22|2@1+ (1,0) [0|0] "" GTW
 SG_ EPAS_d009_KFC_WD_CHECK m0 : 24|2@1+ (1,0) [0|0] "" GTW
 SG_ EPAS_d010_KFC_COMP_L1 m0 : 26|2@1+ (1,0) [0|0] "" GTW
 SG_ EPAS_d011_KFC_COMP_L2 m0 : 28|2@1+ (1,0) [0|0] "" GTW
 SG_ EPAS_d012_KFC_ADC m0 : 30|2@1+ (1,0) [0|0] "" GTW
 SG_ EPAS_d013_KFC_UKL30_2H m0 : 32|2@1+ (1,0) [0|0] "" GTW
 SG_ EPAS_d014_KFC_UKL30_2L m0 : 34|2@1+ (1,0) [0|0] "" GTW
 SG_ EPAS_d015_KFC_UCU_RED m0 : 36|2@1+ (1,0) [0|0] "" GTW
 SG_ EPAS_d016_KFC_CCU_RED m0 : 38|2@1+ (1,0) [0|0] "" GTW
 SG_ EPAS_d017_KFC_UUT_RED m0 : 40|2@1+ (1,0) [0|0] "" GTW
 SG_ EPAS_d018_KFC_UKL30_2H_OFF m0 : 42|2@1+ (1,0) [0|0] "" GTW
 SG_ EPAS_d019_KFC_UKL30_2L_OFF m0 : 44|2@1+ (1,0) [0|0] "" GTW
 SG_ EPAS_d020_KFC_RAM m0 : 46|2@1+ (1,0) [0|0] "" GTW
 SG_ EPAS_d021_KFC_SPI_COM_TIMO m0 : 48|2@1+ (1,0) [0|0] "" GTW
 SG_ EPAS_d022_KFC_SPI_SYNC_REG m0 : 50|2@1+ (1,0) [0|0] "" GTW
 SG_ EPAS_d023_KFC_PWD m0 : 52|2@1+ (1,0) [0|0] "" GTW
 SG_ EPAS_d024_KFC_PROGFLOW m0 : 54|2@1+ (1,0) [0|0] "" GTW
 SG_ EPAS_d025_KFC_STORQUE_OC m0 : 56|2@1+ (1,0) [0|0] "" GTW
 SG_ EPAS_d026_KFC_STORQUE_RAD m0 : 58|2@1+ (1,0) [0|0] "" GTW
 SG_ EPAS_d027_KFC_FOR_TIMO m0 : 60|2@1+ (1,0) [0|0] "" GTW
 SG_ EPAS_d028_KFC_PROG_WD m0 : 62|2@1+ (1,0) [0|0] "" GTW
 SG_ EPAS_d029_KFC_CST m1 : 8|2@1+ (1,0) [0|0] "" GTW
 SG_ EPAS_d030_KFC_REG_CHECK m1 : 10|2@1+ (1,0) [0|0] "" GTW
 SG_ EPAS_d031_KFC_CR_RED m1 : 12|2@1+ (1,0) [0|0] "" GTW
 SG_ EPAS_d032_KFC_ROM m1 : 14|2@1+ (1,0) [0|0] "" GTW
 SG_ EPAS_d033_KFC_SWGEN m1 : 16|2@1+ (1,0) [0|0] "" GTW
 SG_ EPAS_d034_KFC_FOR_OC m1 : 18|2@1+ (1,0) [0|0] "" GTW
 SG_ EPAS_d035_KFC_FOR_WREL m1 : 20|2@1+ (1,0) [0|0] "" GTW
 SG_ EPAS_d036_KFC_FOR_ANGLE m1 : 22|2@1+ (1,0) [0|0] "" GTW
 SG_ EPAS_d037_KFC_FOR_LENGTH m1 : 24|2@1+ (1,0) [0|0] "" GTW
 SG_ EPAS_d038_KFC_BUS_OFF m1 : 26|2@1+ (1,0) [0|0] "" GTW
 SG_ EPAS_d039_KFC_RESET m1 : 28|2@1+ (1,0) [0|0] "" GTW
 SG_ EPAS_d040_KFC_RSRADIUS m1 : 30|2@1+ (1,0) [0|0] "" GTW
 SG_ EPAS_d041_KFC_U_REDUNDANT m1 : 32|2@1+ (1,0) [0|0] "" GTW
 SG_ EPAS_d042_KFC_RSDIFF m1 : 34|2@1+ (1,0) [0|0] "" GTW
 SG_ EPAS_d043_KFC_ESP_TIMO m1 : 36|2@1+ (1,0) [0|0] "" GTW
 SG_ EPAS_d044_KFC_GTW_TIMO m1 : 38|2@1+ (1,0) [0|0] "" GTW
 SG_ EPAS_d045_KFC_DI_Torque1_TIMO m1 : 40|2@1+ (1,0) [0|0] "" GTW
 SG_ EPAS_d046_KFC_SAS_TIMO m1 : 42|2@1+ (1,0) [0|0] "" GTW
 SG_ EPAS_d047_KFC_EACALLOW m1 : 44|2@1+ (1,0) [0|0] "" GTW
 SG_ EPAS_d048_KFC_EPB_TIMO m1 : 46|2@1+ (1,0) [0|0] "" GTW
 SG_ EPAS_d049_KFC_ESRA_CANCELLED m1 : 48|2@1+ (1,0) [0|0] "" GTW
 SG_ EPAS_d050_KFC_STEERING_ANGLE m1 : 50|2@1+ (1,0) [0|0] "" GTW
 SG_ EPAS_d051_KFC_VEHICLE_SPEED m1 : 52|2@1+ (1,0) [0|0] "" GTW
 SG_ EPAS_d052_KFC_UNUSED_52 m1 : 54|2@1+ (1,0) [0|0] "" GTW
 SG_ EPAS_d053_KFC_UNUSED_53 m1 : 56|2@1+ (1,0) [0|0] "" GTW
 SG_ EPAS_d054_KFC_CCF_NOT_CONFIGURED m1 : 58|2@1+ (1,0) [0|0] "" GTW
 SG_ EPAS_d055_KFC_CCF_INVALID m1 : 60|2@1+ (1,0) [0|0] "" GTW
 SG_ EPAS_d056_KFC_UNUSED_56 m1 : 62|2@1+ (1,0) [0|0] "" GTW
 SG_ EPAS_d057_KFC_FRICTION m2 : 8|2@1+ (1,0) [0|0] "" GTW
 SG_ EPAS_d058_KFC_EXPULSION_MODE m2 : 10|2@1+ (1,0) [0|0] "" GTW
 SG_ EPAS_d059_KFC_TEMP_DIAG_DEV m2 : 12|2@1+ (1,0) [0|0] "" GTW
 SG_ EPAS_d060_KFC_POWER_MODE m2 : 14|2@1+ (1,0) [0|0] "" GTW
 SG_ EPAS_d061_KFC_UNUSED_61 m2 : 16|2@1+ (1,0) [0|0] "" GTW
 SG_ EPAS_d062_KFC_WHEEL_SPEEDS m2 : 18|2@1+ (1,0) [0|0] "" GTW
 SG_ EPAS_d063_KFC_UNUSED_63 m2 : 20|2@1+ (1,0) [0|0] "" GTW
 SG_ EPAS_d064_KFC_DI_MOTORRPM m2 : 22|2@1+ (1,0) [0|0] "" GTW
 SG_ EPAS_d065_KFC_YAW_RATE m2 : 24|2@1+ (1,0) [0|0] "" GTW
 SG_ EPAS_d066_KFC_UCU_RED_INFO m2 : 26|2@1+ (1,0) [0|0] "" GTW
 SG_ EPAS_d067_KFC_CCU_RED_INFO m2 : 28|2@1+ (1,0) [0|0] "" GTW
 SG_ EPAS_d068_KFC_UCO_RED_INFO m2 : 30|2@1+ (1,0) [0|0] "" GTW
 SG_ EPAS_d069_KFC_CR_RED_INFO m2 : 32|2@1+ (1,0) [0|0] "" GTW
 SG_ EPAS_d070_KFC_ROTANG m2 : 34|2@1+ (1,0) [0|0] "" GTW
 SG_ EPAS_d071_KFC_PD_RED m2 : 36|2@1+ (1,0) [0|0] "" GTW
 SG_ EPAS_d072_KFC_OS_MON m2 : 38|2@1+ (1,0) [0|0] "" GTW
 SG_ EPAS_d073_KFC_UCO_RED m2 : 40|2@1+ (1,0) [0|0] "" GTW
 SG_ EPAS_d074_KFC_SSW m2 : 42|2@1+ (1,0) [0|0] "" GTW
 SG_ EPAS_d075_KFC_BLOCKED_STEERING m2 : 44|2@1+ (1,0) [0|0] "" GTW
 SG_ EPAS_d076_KFC_DAS_TIMO m2 : 46|2@1+ (1,0) [0|0] "" GTW
 SG_ EPAS_d077_KFC_STEERING_CONTROL m2 : 48|2@1+ (1,0) [0|0] "" GTW

BO_ 1328 EPAS_info: 8 EPAS
 SG_ EPAS_infoIndex M : 0|8@1+ (1,0) [0|0] "" GTW,GTWU
 SG_ EPAS_infoBuildType m10 : 8|8@1+ (1,0) [0|0] "" GTW
 SG_ EPAS_infoComponentID m10 : 48|16@1+ (1,0) [0|0] "" GTW
 SG_ EPAS_infoPcbaID m11 : 16|8@1+ (1,0) [0|0] "" GTW,GTWU
 SG_ EPAS_infoAssemblyID m11 : 24|8@1+ (1,0) [0|255] "" GTW,GTWU
 SG_ EPAS_infoUsageID m11 : 32|16@1+ (1,0) [0|65535] "" GTW,GTWU
 SG_ EPAS_infoApplicationCRC m13 : 32|32@1+ (1,0) [0|0] "" GTW,GTWU
 SG_ EPAS_infoBootUdsProtoVersion m20 : 8|8@1+ (1,0) [0|0] "" GTW,GTWU
 SG_ EPAS_infoBootloaderCRC m20 : 32|32@1+ (1,0) [0|0] "" GTW

BO_ 1792 EPAS_reservedRx700: 8 DBG

BO_ 1793 EPAS_reservedRx701: 8 DBG

BO_ 1794 EPAS_reservedRx702: 8 DBG

BO_ 1795 EPAS_reservedRx703: 8 DBG

BO_ 1796 EPAS_reservedRx704: 8 DBG

BO_ 1634 EPAS_reservedRxAZG: 8 DBG

BO_ 1636 EPAS_reservedRxCANTERM: 8 DBG

BO_ 1856 EPAS_reservedRxCANape: 8 DBG

BO_ 1632 EPAS_reservedRxCCP: 8 DBG

BO_ 1857 EPAS_reservedRxTuning: 8 DBG

BO_ 1807 EPAS_reservedTx70F: 8 EPAS

BO_ 1808 EPAS_reservedTx710: 8 EPAS

BO_ 1809 EPAS_reservedTx711: 8 EPAS

BO_ 1810 EPAS_reservedTx712: 8 EPAS

BO_ 1811 EPAS_reservedTx713: 8 EPAS

BO_ 1635 EPAS_reservedTxAZG: 8 EPAS

BO_ 1637 EPAS_reservedTxCANTERM: 8 EPAS

BO_ 1858 EPAS_reservedTxCANape: 8 EPAS

BO_ 1633 EPAS_reservedTxCCP: 8 EPAS

BO_ 1638 EPAS_reservedTxSVM1: 8 EPAS

BO_ 1639 EPAS_reservedTxSVM2: 8 EPAS

BO_ 1859 EPAS_reservedTxTuning: 8 EPAS

BO_ 880 EPAS_sysStatus: 8 EPAS
 SG_ EPAS_steeringRackForce : 1|10@0+ (50,-25575) [-25575|25575] "N" PARK,GTW
 SG_ EPAS_steeringFault : 2|1@0+ (1,0) [0|1] "" PARK,GTW,DAS
 SG_ EPAS_steeringReduced : 3|1@0+ (1,0) [0|1] "" PARK,GTW,DAS
 SG_ EPAS_currentTuneMode : 7|4@0+ (1,0) [0|0] "" PARK,GTW,DAS
 SG_ EPAS_torsionBarTorque : 19|12@0+ (0.01,-20.5) [-20.5|20.45] "Nm" PARK,GTW,DAS
 SG_ EPAS_eacErrorCode : 23|4@0+ (1,0) [0|15] "" PARK,GTW,DAS
 SG_ EPAS_internalSAS : 37|14@0+ (0.1,-819.2) [-819.2|819] "deg" PARK,GTW,DAS
 SG_ EPAS_handsOnLevel : 39|2@0+ (1,0) [0|3] "" PARK,GTW,DAS
 SG_ EPAS_sysStatusCounter : 51|4@0+ (1,0) [0|15] "" PARK,GTW
 SG_ EPAS_eacStatus : 55|3@0+ (1,0) [0|7] "" PARK,GTW,DAS,EPB
 SG_ EPAS_sysStatusChecksum : 63|8@0+ (1,0) [0|255] "" PARK,GTW

BO_ 1848 EPAS_udsResponse: 8 EPAS
 SG_ EPAS_udsResponseData : 7|64@0+ (1,0) [0|0] "" GTW,GTWU

CM_ BO_ 1838 "ISOTP debug serial port for VCSEATD";
CM_ BO_ 1839 "ISOTP debug serial port for VCSEATP";
CM_ BO_ 518 "DI-requested brake torque per corner.";
CM_ BO_ 1270 "Reports the status of different drive inverter longitudinal control indicators";
CM_ BO_ 872 "Drive Inverter status through GTW from the PT bus. Message is cyclic on the CH bus triggered by GTW receiving a cyclic message from the Drive Inverter.";
CM_ BO_ 1016 "Drive Inverter state indicators 2.";
CM_ BO_ 280 "This message is temporarily sent by the gateway with special code";
CM_ BO_ 281 "VDC commands for left wheels.";
CM_ BO_ 282 "VDC commands for right wheels.";
CM_ BO_ 527 "General Status Message";
CM_ SG_ 1089 DG_RQ_GLOBAL_UDS "Functional Diagnostic Request (UDS)";
CM_ SG_ 1803 D_RQ_LC "UDS Diagnostic-Request";
CM_ SG_ 390 DIS_torqueDriver "Driver requested torque command.";
CM_ SG_ 390 DIS_torque1Counter "Message counter for DIS_torque1 message: increments in each message.";
CM_ SG_ 390 DIS_torqueMotor "Applied motor torque command.";
CM_ SG_ 390 DIS_motorRPM "Drive Inverter measured motor shaft speed. SNA is 0x8000";
CM_ SG_ 390 DIS_torque1Checksum "Message checksum for DIS_torque1 message: sum of all bytes in message + 0x16.";
CM_ SG_ 518 DI_btcRequest_FrL "DI-requested front left brake torque";
CM_ SG_ 518 DI_btcRequest_FrR "DI-requested front right brake torque";
CM_ SG_ 518 DI_btcRequest_ReL "DI-requested rear left brake torque";
CM_ SG_ 518 DI_btcRequest_ReR "DI-requested rear right brake torque";
CM_ SG_ 518 DI_btcRequestActive_FrR "Flag indicating DI request for BTC in front right";
CM_ SG_ 518 DI_btcRequestActive_ReL "Flag indicating DI request for BTC in rear left";
CM_ SG_ 518 DI_btcRequestActive_FrL "Flag indicating DI request for BTC in front left";
CM_ SG_ 518 DI_btcRequestActive_ReR "Flag indicating DI request for BTC in rear right";
CM_ SG_ 518 DI_btcRequestCounter "Message counter for DI_btcRequest message: increments in each message.";
CM_ SG_ 518 DI_btcRequestChecksum "Message checksum for DI_btcRequest message: sum of all bytes in message + 0x08).";
CM_ SG_ 328 DI_brakeTorqueCommand "Brake torque command to ESP";
CM_ SG_ 328 DI_cruiseControlEngaged "Indicates if cruise is engaged. (normal or ACC)";
CM_ SG_ 328 DI_btcState "Indicates state of Tesla brake traction control system";
CM_ SG_ 328 DI_vehicleStandstillRqst "EBR standstill request.";
CM_ SG_ 328 DI_ptcState "Indicates state of Tesla traction control system";
CM_ SG_ 328 DI_ptcActive "TRUE when Tesla traction control is active";
CM_ SG_ 328 DI_tcLampFlashRequest "Tesla Traction control request to flash the traction control lamp.";
CM_ SG_ 328 DI_brakeCommandType "Brake request type to ESP";
CM_ SG_ 328 DI_regenTcActive "TRUE when Tesla regen traction control is active.";
CM_ SG_ 328 DI_espControlCounter "Message counter for DI_espContol message, increments in each message.";
CM_ SG_ 328 DI_espControlChecksum "Message checksum for DI_espControl: sum of all bytes in message + 0x38.";
CM_ SG_ 1270 DI_crsState "Cruise control state";
CM_ SG_ 1270 DI_locState "Longitudinal control state";
CM_ SG_ 1270 DI_crsSetSpeed "Cruise control set point";
CM_ SG_ 872 DI_systemState "DI system state machine state.";
CM_ SG_ 872 DI_proximity "TRUE if the proximity hardware input signal is active.";
CM_ SG_ 872 DI_driveReady "TRUE when Drive Inverter is ready to drive";
CM_ SG_ 872 DI_regenLight "TRUE to request lighting regen brake lights.";
CM_ SG_ 872 DI_state "Inverter state machine state.";
CM_ SG_ 872 DI_cruiseState "Cruise control state.";
CM_ SG_ 872 DI_cruiseSet "Cruise control set point.";
CM_ SG_ 1016 DI_autoparkState "Autopark control state.";
CM_ SG_ 1016 DI_parkBrakeState "DI Park Brake control and EPB interface state.";
CM_ SG_ 1016 DI_vehicleHoldTelltaleOn "Request to turn telltale ON in UI when Vehicle Hold is engaged";
CM_ SG_ 1016 DI_onePedalDrivingState "One Pedal Driving state machine state";
CM_ SG_ 264 DI_torqueDriver "Driver requested torque command. SNA is 0xF000";
CM_ SG_ 264 DI_torque1Counter "Message counter for DI_torque1 message: increments in each message.";
CM_ SG_ 264 DI_torqueMotor "Applied motor torque command. SNA is 0xF000";
CM_ SG_ 264 DI_motorRPM "Drive Inverter measured motor shaft speed. SNA is 0x8000";
CM_ SG_ 264 DI_pedalPos "Drive Inverter measured pedal position.";
CM_ SG_ 264 DI_torque1Checksum "Message checksum for DI_torque1 message: sum of all bytes in message + 0x07";
CM_ SG_ 280 DI_torqueEstimate "Motor torque estimate calculated by the Drive Inverter.";
CM_ SG_ 280 DI_gear "Current operating gear.";
CM_ SG_ 280 DI_brakePedal "TRUE if brake pedal input signal is active.";
CM_ SG_ 280 DI_gearRequest "Drive Inverter gear request.";
CM_ SG_ 280 DI_torque2Counter "Message counter for DI_torque2 message: increments in each message.";
CM_ SG_ 280 DI_epbParkRequest "TRUE if DI requests Park from ACC standstill.";
CM_ SG_ 280 DI_torque2Checksum "Message checksum for DI_torque2 message: sum of all bytes in message + 0x17";
CM_ SG_ 281 DI_vdcLeftChecksum "Message checksum for DI_vdcLeft message: sum of all bytes in message + 1A).";
CM_ SG_ 281 DI_vdcLeftCounter "Message counter for DI_vdcLeft message: increments in each message.";
CM_ SG_ 281 DI_vdcCommandTypeFrL "DI-requested VDC command type for front left wheel";
CM_ SG_ 281 DI_vdcCommandTypeReL "DI-requested VDC command type for rear left wheel";
CM_ SG_ 281 DI_vdcCommandABSFrL "DI-requested ABS arbitration mode for front left wheel";
CM_ SG_ 281 DI_vdcCommandABSReL "DI-requested ABS arbitration mode for rear left wheel";
CM_ SG_ 281 DI_brakeTorqueTarFrL "DI-requested front left brake torque";
CM_ SG_ 281 DI_brakeTorqueTarReL "DI-requested rear left brake torque";
CM_ SG_ 281 DI_wheelSlipLimitFrL "DI-requested slip limit and target for front left wheel, arbitrated by DI_vdcCommandTypeFrL";
CM_ SG_ 281 DI_wheelSlipLimitReL "DI-requested slip limit and target for rear left wheel, arbitrated by DI_vdcCommandTypeReL";
CM_ SG_ 282 DI_vdcRightChecksum "Message checksum for DI_vdcRight message: sum of all bytes in message + 0x1B).";
CM_ SG_ 282 DI_vdcRightCounter "Message counter for DI_vdcRight message: increments in each message.";
CM_ SG_ 282 DI_vdcCommandTypeFrR "DI-requested VDC command type for front right wheel";
CM_ SG_ 282 DI_vdcCommandTypeReR "DI-requested VDC command type for rear right wheel";
CM_ SG_ 282 DI_vdcCommandABSFrR "DI-requested ABS arbitration mode for front right wheel";
CM_ SG_ 282 DI_vdcCommandABSReR "DI-requested ABS arbitration mode for rear right wheel";
CM_ SG_ 282 DI_brakeTorqueTarFrR "DI-requested front right brake torque";
CM_ SG_ 282 DI_brakeTorqueTarReR "DI-requested rear right brake torque";
CM_ SG_ 282 DI_wheelSlipLimitFrR "DI-requested slip limit and target for front right wheel, arbitrated by DI_vdcCommandTypeFrR";
CM_ SG_ 282 DI_wheelSlipLimitReR "DI-requested slip limit and target for rear right wheel, arbitrated by DI_vdcCommandTypeReR";
CM_ SG_ 512 DPM_MdLmt_Rq "Decentral power management mode limit request";
CM_ SG_ 512 DPM_ExtMd_Enbl_Rq "Decentral power management external mode enable request";
CM_ SG_ 1570 D_RQ_SCCM "Diagnostic Request";
CM_ SG_ 1156 D_RS_SCCM "Diagnostic Response";
CM_ SG_ 360 GTW_alternatorDutyCycle "Alternator : Excitation Duty Cycle";
CM_ SG_ 360 GTW_cruiseControlStatus "Cruise control status";
CM_ SG_ 360 GTW_counter4 "message counter";
CM_ SG_ 360 GTW_speedLimiterStatus "Speed limiter status";
CM_ SG_ 360 GTW_immobiliserLockOn "IM_AUTEHN: ECM  immobilizer (1 indicates cannot be mobilised that key cycle)";
CM_ SG_ 360 GTW_alternatorStatus "Alternator status from ECM to IBS. Bit 0 = high temp, bit 1 = mechanical fault, bit 2 = electrical fault";
CM_ SG_ 360 GTW_immobiliserOn "IM_STAT ECM immobilizer status";
CM_ SG_ 360 GTW_engineStatus "Engine status";
CM_ SG_ 360 GTW_ignitionResult "Security - TBD";
CM_ SG_ 360 GTW_nEngine "N _ENG Engine speed";
CM_ SG_ 360 GTW_checksum4 "Message Checksum according to SAE J1850";
CM_ SG_ 1 ISw_Stat "Ignition switch state";
CM_ SG_ 1 Ign_On_StProc_Inact "Ignition is on and starting procedure is inactive (15x)";
CM_ SG_ 1 TxPkPosn_Rq "Transmission parking position request";
CM_ SG_ 1 TxPkPosn_Emg_Rq "Transmission parking position emergency request";
CM_ SG_ 1 TxPkPosnAuto_Enbl "Transmission parking position auto enable";
CM_ SG_ 1 TxPkPosn_Rq_SBC_Enbl "Transmission parking position request enable";
CM_ SG_ 1 KG_IgnCtrl_Actv "Keyless Go ignition control active";
CM_ SG_ 1 EngSt_Enbl_Rq_KG "Enable engine start request";
CM_ SG_ 1 KG_StSw_Psd "Keyless Go start switch pressed";
CM_ SG_ 1 AutoDrLk_Rq_Src "Automatic door lock request source";
CM_ SG_ 1 AutoDrLk_Stat "Automatic door lock state";
CM_ SG_ 1 SPCR_Conf_EIS "Stop coordinator configuration";
CM_ SG_ 1 CLkS_DL_Stat "Central locking system deck lid state";
CM_ SG_ 1 CLkS_Gas_Dr_Stat "Central locking system gas door state";
CM_ SG_ 1 CLkS_Dr_FL_Stat "Central locking system door front left state";
CM_ SG_ 1 CLkS_Dr_FR_Stat "Central locking system door front right state";
CM_ SG_ 1 CLkS_Dr_RL_Stat "Central locking system door rear left state";
CM_ SG_ 1 CLkS_Dr_RR_Stat "Central locking system door rear right state";
CM_ SG_ 1 KeyLine1_Appr "Keyline 1 approved for Keyless Go";
CM_ SG_ 1 KeyLine2_Appr "Keyline 2 approved for Keyless Go";
CM_ SG_ 1 KeyLine3_Appr "Keyline 3 approved for Keyless Go";
CM_ SG_ 1 KeyLine4_Appr "Keyline 4 approved for Keyless Go";
CM_ SG_ 1 KeyLine5_Appr "Keyline 5 approved for Keyless Go";
CM_ SG_ 1 KeyLine6_Appr "Keyline 6 approved for Keyless Go";
CM_ SG_ 1 KeyLine7_Appr "Keyline 7 approved for Keyless Go";
CM_ SG_ 1 KeyLine8_Appr "Keyline 8 approved for Keyless Go";
CM_ SG_ 1 CLkS_Lk_Stat3 "Central locking system lock state";
CM_ SG_ 1 SPCR_AcustWarn_Rq_EIS "SPCR acoustical warning request";
CM_ SG_ 1 MC_EIS_A1 "Message counter";
CM_ SG_ 1 CRC_EIS_A1 "CRC-checksum byte 1 to 7 according to SAE J1850";
CM_ SG_ 261 EngRPM "Actual engine rpm";
CM_ SG_ 261 PreHt_Stat "Preheating state";
CM_ SG_ 261 KickDnSw_Psd "Kickdown switch pressed";
CM_ SG_ 261 EngTrqMaxCorrFctr "Correction factor of maximum engine torque depending on falling atmospheric pressure";
CM_ SG_ 261 AccelPdlPosn "Accelerator pedal position";
CM_ SG_ 261 AccelPdlPosn_Raw "Accelerator pedal position raw value";
CM_ SG_ 261 GenLoad "Actual generator load";
CM_ SG_ 261 AddPwrCnsmr_On_Rq "Additional power consumers on request";
CM_ SG_ 261 Term61_Actv "Terminal 61 active";
CM_ SG_ 261 EngRun_Stat "Engine running state";
CM_ SG_ 261 AccelPdlPosnSens_Flt "Accelerator pedal position sensor fault";
CM_ SG_ 261 MC_ENG_RS3 "Message counter";
CM_ SG_ 261 CRC_ENG_RS3 "CRC-checksum byte 1 to 7 according to SAE J1850";
CM_ SG_ 977 EPAS_appliedAngleOffset "Steering angle offset currently applied to EPAS_internalSAS";
CM_ SG_ 977 EPAS_calculatedAngleOffset "Real-time calculated steering angle offset which is stored in EEPROM during power-off and applied in following drive cycle";
CM_ SG_ 977 EPAS_resyncStatus "Status of EPAS_internalSAS resynchronization to SCCM steering angle sensor during power-up";
CM_ SG_ 880 EPAS_steeringRackForce "Realtime estimated force on steering rack";
CM_ SG_ 880 EPAS_steeringFault "Power steering is not-available";
CM_ SG_ 880 EPAS_steeringReduced "Power steering is functional, but reduced";
CM_ SG_ 880 EPAS_currentTuneMode "Feedback of selected tuning mode";
CM_ SG_ 880 EPAS_torsionBarTorque "Measured steering wheel torque, Clockwise Positive";
CM_ SG_ 880 EPAS_internalSAS "Steering wheel angle measured by EPAS, Clockwise Positive";
CM_ SG_ 880 EPAS_handsOnLevel "Hands on detection level defined by configurable thresholds";
CM_ SG_ 880 EPAS_sysStatusCounter "Counter, 0->0xF to prevent stale data";
CM_ SG_ 880 EPAS_eacStatus "Status of the EAC system, to indicate what mode is active";
CM_ SG_ 880 EPAS_sysStatusChecksum "Checksum for the EPAS_sysStatus message. Sum of all data bytes + originating ID (0x03 + 0x70)";
BA_DEF_ BO_ "AlertLogSubSystemId" INT 0 0;
BA_DEF_ BO_ "AlertType" INT 0 4;
BA_DEF_ BO_ "AppBotschaft" ENUM "nein","ja";
BA_DEF_ BO_ "DiagRequest" ENUM "No","Yes";
BA_DEF_ BO_ "DiagResponse" ENUM "No","Yes";
BA_DEF_ BO_ "ETHGatewayMessageSendType" ENUM "UseGenMsgSendType","onWrite","noAutoCode";
BA_DEF_ BO_ "ETHId" STRING ;
BA_DEF_ BO_ "GatewayHandlerEnum" ENUM "noHandler","uds","alertLog","messageLogOnReception","udsClient";
BA_DEF_ BO_ "GatewayMessageAtomic" ENUM "No","Yes";
BA_DEF_ BO_ "GatewayMessageSendType" ENUM "UseGenMsgSendType","onWrite","noAutoCode";
BA_DEF_ BO_ "GenMsgCycleTime" INT 0 0;
BA_DEF_ BO_ "GenMsgCycleTimeFast" INT 0 0;
BA_DEF_ BO_ "GenMsgDelayTime" INT 0 0;
BA_DEF_ BO_ "GenMsgForceMiaCheck" ENUM "No","Yes";
BA_DEF_ BO_ "GenMsgGatewayNotification" STRING ;
BA_DEF_ BO_ "GenMsgILSupport" ENUM "No","Yes";
BA_DEF_ BO_ "GenMsgSaltingFunction" ENUM "No","Yes";
BA_DEF_ BO_ "GenMsgSendType" ENUM "Cyclic","NotUsed","NotUsed","NotUsed","NotUsed","NotUsed","NotUsed","IfActive","NoMsgSendType","Sporadic";
BA_DEF_ BO_ "GenMsgStartValue" STRING ;
BA_DEF_ BO_ "GenMsgTimeOut" INT 0 0;
BA_DEF_ BO_ "MessageIdType" ENUM "normal","udsRequest","udsResponse","udsReserved","udsFunctionalRequest","networkManagement","bootloader","xcp","dtc","diagnostic","vendorExempt";
BA_DEF_ BO_ "NWMBotschaft" ENUM "nein","ja";
BA_DEF_ BO_ "NmMessage" ENUM "No","Yes";
BA_DEF_ BO_ "SubSystemId" INT 0 256;
BA_DEF_ BO_ "UsesChecksum" ENUM "No","Yes";
BA_DEF_ SG_ "FieldType" STRING ;
BA_DEF_ SG_ "FlexKomComment" STRING ;
BA_DEF_ SG_ "FlexKomIsMotorola" ENUM "nein","ja";
BA_DEF_ SG_ "FlexKomSID" INT 0 2147483647;
BA_DEF_ SG_ "FlexKomSigLaenge" INT 0 64;
BA_DEF_ SG_ "FlexKomSigName" STRING ;
BA_DEF_ SG_ "FlexKomSigStartPos" INT 0 63;
BA_DEF_ SG_ "FlexKomSigStartValue" STRING ;
BA_DEF_ SG_ "Gatewaysignal" INT 0 1;
BA_DEF_ SG_ "GenSigCycleTime" INT 0 0;
BA_DEF_ SG_ "GenSigCycleTimeActive" INT 0 0;
BA_DEF_ SG_ "GenSigPersistent" ENUM "No","Yes";
BA_DEF_ SG_ "GenSigSNA" STRING ;
BA_DEF_ SG_ "GenSigSendType" ENUM "Cyclic","OnWrite","OnWriteWithRepetition","OnChange","OnChangeWithRepetition","IfActive","IfActiveWithRepetition","NoSigSendType","NotUsed","NotUsed","NotUsed","NotUsed","NotUsed";
BA_DEF_ SG_ "GenSigStartValue" INT 0 0;
BA_DEF_ SG_ "GenSigTimeout_CGW" INT 0 65535;
BA_DEF_ SG_ "GenSigTimeout_DRVU" INT 0 65535;
BA_DEF_ SG_ "GenSigTimeout_ECM" INT 0 65535;
BA_DEF_ SG_ "GenSigTimeout_EIS" INT 0 65535;
BA_DEF_ SG_ "GenSigTimeout_EPS" INT 0 65535;
BA_DEF_ SG_ "GenSigTimeout_ESP_ABR" INT 0 65535;
BA_DEF_ SG_ "GenSigTimeout_IC" INT 0 65535;
BA_DEF_ SG_ "GenSigTimeout_MPC" INT 0 65535;
BA_DEF_ SG_ "GenSigTimeout_NV" INT 0 65535;
BA_DEF_ SG_ "GenSigTimeout_ORC" INT 0 65535;
BA_DEF_ SG_ "GenSigTimeout_PTS" INT 0 65535;
BA_DEF_ SG_ "GenSigTimeout_RBTM_FL" INT 0 65535;
BA_DEF_ SG_ "GenSigTimeout_RBTM_FR" INT 0 65535;
BA_DEF_ SG_ "GenSigTimeout_RDU" INT 0 65535;
BA_DEF_ SG_ "GenSigTimeout_SCCM" INT 0 65535;
BA_DEF_ SG_ "GenSigTimeout_SPC" INT 0 65535;
BA_DEF_ SG_ "GenSigTimeout_TPM" INT 0 65535;
BA_DEF_ SG_ "LogSignal" STRING ;
BA_DEF_ SG_ "PektronUpdateBitType" ENUM "Not used","Has update bit","Is update bit";
BA_DEF_REL_ BU_SG_REL_ "GenSigTimeoutTime" INT 0 0;

BA_DEF_DEF_ "AlertLogSubSystemId" 0;
BA_DEF_DEF_ "AlertType" 4;
BA_DEF_DEF_ "AppBotschaft" "nein";
BA_DEF_DEF_ "DiagRequest" "No";
BA_DEF_DEF_ "DiagResponse" "No";
BA_DEF_DEF_ "ETHGatewayMessageSendType" "UseGenMsgSendType";
BA_DEF_DEF_ "ETHId" "";
BA_DEF_DEF_ "FieldType" "";
BA_DEF_DEF_ "FlexKomComment" "";
BA_DEF_DEF_ "FlexKomIsMotorola" "";
BA_DEF_DEF_ "FlexKomSID" 0;
BA_DEF_DEF_ "FlexKomSigLaenge" 0;
BA_DEF_DEF_ "FlexKomSigName" "";
BA_DEF_DEF_ "FlexKomSigStartPos" 0;
BA_DEF_DEF_ "FlexKomSigStartValue" "";
BA_DEF_DEF_ "GatewayHandlerEnum" "noHandler";
BA_DEF_DEF_ "GatewayMessageAtomic" "No";
BA_DEF_DEF_ "GatewayMessageSendType" "UseGenMsgSendType";
BA_DEF_DEF_ "Gatewaysignal" 0;
BA_DEF_DEF_ "GenMsgCycleTime" 0;
BA_DEF_DEF_ "GenMsgCycleTimeFast" 0;
BA_DEF_DEF_ "GenMsgDelayTime" 0;
BA_DEF_DEF_ "GenMsgForceMiaCheck" "No";
BA_DEF_DEF_ "GenMsgGatewayNotification" "";
BA_DEF_DEF_ "GenMsgILSupport" "Yes";
BA_DEF_DEF_ "GenMsgSaltingFunction" "No";
BA_DEF_DEF_ "GenMsgSendType" "Cyclic";
BA_DEF_DEF_ "GenMsgStartValue" "";
BA_DEF_DEF_ "GenMsgTimeOut" 0;
BA_DEF_DEF_ "GenSigCycleTime" 0;
BA_DEF_DEF_ "GenSigCycleTimeActive" 0;
BA_DEF_DEF_ "GenSigPersistent" "No";
BA_DEF_DEF_ "GenSigSNA" "";
BA_DEF_DEF_ "GenSigSendType" "Cyclic";
BA_DEF_DEF_ "GenSigStartValue" 0;
BA_DEF_DEF_ "GenSigTimeout_CGW" 0;
BA_DEF_DEF_ "GenSigTimeout_DRVU" 0;
BA_DEF_DEF_ "GenSigTimeout_ECM" 0;
BA_DEF_DEF_ "GenSigTimeout_EIS" 0;
BA_DEF_DEF_ "GenSigTimeout_EPS" 0;
BA_DEF_DEF_ "GenSigTimeout_ESP_ABR" 0;
BA_DEF_DEF_ "GenSigTimeout_IC" 0;
BA_DEF_DEF_ "GenSigTimeout_MPC" 0;
BA_DEF_DEF_ "GenSigTimeout_NV" 0;
BA_DEF_DEF_ "GenSigTimeout_ORC" 0;
BA_DEF_DEF_ "GenSigTimeout_PTS" 0;
BA_DEF_DEF_ "GenSigTimeout_RBTM_FL" 0;
BA_DEF_DEF_ "GenSigTimeout_RBTM_FR" 0;
BA_DEF_DEF_ "GenSigTimeout_RDU" 0;
BA_DEF_DEF_ "GenSigTimeout_SCCM" 0;
BA_DEF_DEF_ "GenSigTimeout_SPC" 0;
BA_DEF_DEF_ "GenSigTimeout_TPM" 0;
BA_DEF_DEF_ "LogSignal" "";
BA_DEF_DEF_ "MessageIdType" "normal";
BA_DEF_DEF_ "NWMBotschaft" "nein";
BA_DEF_DEF_ "NmMessage" "No";
BA_DEF_DEF_ "PektronUpdateBitType" "Not used";
BA_DEF_DEF_ "SubSystemId" 0;
BA_DEF_DEF_ "UsesChecksum" "No";
BA_DEF_DEF_REL_ "GenSigTimeoutTime" 0;
BA_ "AlertType" BO_ 841 1;
BA_ "ETHId" BO_ 841 "RETAIN_ID";
BA_ "GatewayMessageSendType" BO_ 841 1;
BA_ "GenMsgCycleTime" BO_ 841 1000;
BA_ "GenMsgSendType" BO_ 1838 7;
BA_ "GenMsgSendType" BO_ 1839 7;
BA_ "GenMsgSendType" BO_ 1801 8;
BA_ "MessageIdType" BO_ 1801 9;
BA_ "GenMsgSendType" BO_ 1833 8;
BA_ "MessageIdType" BO_ 1833 9;
BA_ "GenMsgSendType" BO_ 1089 8;
BA_ "GenMsgStartValue" BO_ 1089 "0000000000000000h";
BA_ "MessageIdType" BO_ 1089 4;
BA_ "GenMsgCycleTime" BO_ 1803 100;
BA_ "GenMsgSendType" BO_ 1803 8;
BA_ "GenMsgSendType" BO_ 1820 8;
BA_ "MessageIdType" BO_ 1820 10;
BA_ "GatewayMessageSendType" BO_ 390 2;
BA_ "GenMsgCycleTime" BO_ 390 10;
BA_ "GatewayMessageSendType" BO_ 518 2;
BA_ "GenMsgCycleTime" BO_ 518 20;
BA_ "GatewayMessageSendType" BO_ 328 2;
BA_ "GenMsgCycleTime" BO_ 328 20;
BA_ "GatewayMessageSendType" BO_ 1270 1;
BA_ "GenMsgCycleTime" BO_ 1270 100;
BA_ "GatewayMessageSendType" BO_ 872 1;
BA_ "GenMsgCycleTime" BO_ 872 100;
BA_ "GatewayMessageSendType" BO_ 1016 1;
BA_ "GenMsgCycleTime" BO_ 1016 100;
BA_ "GatewayMessageSendType" BO_ 808 1;
BA_ "GenMsgCycleTime" BO_ 808 100;
BA_ "GatewayMessageSendType" BO_ 264 2;
BA_ "GenMsgCycleTime" BO_ 264 10;
BA_ "GatewayMessageSendType" BO_ 280 2;
BA_ "GenMsgCycleTime" BO_ 280 10;
BA_ "GenMsgTimeOut" BO_ 280 500;
BA_ "GatewayMessageSendType" BO_ 281 1;
BA_ "GenMsgCycleTime" BO_ 281 20;
BA_ "GatewayMessageSendType" BO_ 282 1;
BA_ "GenMsgCycleTime" BO_ 282 20;
BA_ "GenMsgSendType" BO_ 512 8;
BA_ "GenMsgStartValue" BO_ 512 "0Ah";
BA_ "MessageIdType" BO_ 512 10;
BA_ "GenMsgSendType" BO_ 1570 8;
BA_ "GenMsgStartValue" BO_ 1570 "0000000000000000h";
BA_ "MessageIdType" BO_ 1570 1;
BA_ "GatewayHandlerEnum" BO_ 1156 4;
BA_ "GenMsgCycleTime" BO_ 1156 100;
BA_ "GenMsgSendType" BO_ 1156 7;
BA_ "GenMsgStartValue" BO_ 1156 "0000000000000000h";
BA_ "MessageIdType" BO_ 1156 2;
BA_ "GenMsgCycleTime" BO_ 360 100;
BA_ "GatewayMessageSendType" BO_ 527 1;
BA_ "GenMsgCycleTime" BO_ 527 100;
BA_ "GenMsgCycleTime" BO_ 1 100;
BA_ "GenMsgStartValue" BO_ 1 "07C0FFFCFF0007FFh";
BA_ "MessageIdType" BO_ 1 10;
BA_ "GenMsgSendType" BO_ 261 8;
BA_ "GenMsgStartValue" BO_ 261 "3FFFFFFFFF3F07FFh";
BA_ "MessageIdType" BO_ 261 10;
BA_ "AlertLogSubSystemId" BO_ 1472 232;
BA_ "GatewayHandlerEnum" BO_ 1472 2;
BA_ "AlertLogSubSystemId" BO_ 1426 265;
BA_ "GatewayHandlerEnum" BO_ 1426 2;
BA_ "GenMsgSendType" BO_ 1426 1;
BA_ "GenMsgCycleTime" BO_ 978 1000;
BA_ "GenMsgCycleTime" BO_ 914 1000;
BA_ "GenMsgCycleTime" BO_ 817 10000;
BA_ "GenMsgCycleTime" BO_ 49 10;
BA_ "GenMsgCycleTime" BO_ 305 10;
BA_ "DiagResponse" BO_ 1592 1;
BA_ "GatewayHandlerEnum" BO_ 1592 4;
BA_ "GenMsgSendType" BO_ 1592 1;
BA_ "MessageIdType" BO_ 1592 2;
BA_ "AlertLogSubSystemId" BO_ 1425 257;
BA_ "GatewayHandlerEnum" BO_ 1425 2;
BA_ "GenMsgCycleTime" BO_ 81 10;
BA_ "AlertLogSubSystemId" BO_ 1456 11;
BA_ "GatewayHandlerEnum" BO_ 1456 2;
BA_ "GenMsgCycleTime" BO_ 977 1000;
BA_ "GenMsgCycleTime" BO_ 896 1000;
BA_ "GenMsgCycleTime" BO_ 1328 10000;
BA_ "GenMsgTimeOut" BO_ 1328 1000;
BA_ "GenMsgSendType" BO_ 1792 8;
BA_ "GenMsgSendType" BO_ 1793 8;
BA_ "GenMsgSendType" BO_ 1794 8;
BA_ "GenMsgSendType" BO_ 1795 8;
BA_ "GenMsgSendType" BO_ 1796 8;
BA_ "GenMsgCycleTime" BO_ 1634 100;
BA_ "GenMsgSendType" BO_ 1634 8;
BA_ "MessageIdType" BO_ 1634 1;
BA_ "GenMsgCycleTime" BO_ 1636 100;
BA_ "GenMsgSendType" BO_ 1636 8;
BA_ "MessageIdType" BO_ 1636 1;
BA_ "GenMsgSendType" BO_ 1856 8;
BA_ "GenMsgCycleTime" BO_ 1632 100;
BA_ "GenMsgSendType" BO_ 1632 8;
BA_ "MessageIdType" BO_ 1632 1;
BA_ "GenMsgSendType" BO_ 1857 8;
BA_ "GenMsgSendType" BO_ 1807 8;
BA_ "MessageIdType" BO_ 1807 10;
BA_ "GenMsgSendType" BO_ 1808 8;
BA_ "MessageIdType" BO_ 1808 10;
BA_ "GenMsgSendType" BO_ 1809 8;
BA_ "MessageIdType" BO_ 1809 10;
BA_ "GenMsgSendType" BO_ 1810 8;
BA_ "MessageIdType" BO_ 1810 10;
BA_ "GenMsgSendType" BO_ 1811 8;
BA_ "MessageIdType" BO_ 1811 10;
BA_ "GenMsgSendType" BO_ 1635 8;
BA_ "MessageIdType" BO_ 1635 10;
BA_ "GenMsgSendType" BO_ 1637 8;
BA_ "MessageIdType" BO_ 1637 10;
BA_ "GenMsgSendType" BO_ 1858 8;
BA_ "MessageIdType" BO_ 1858 10;
BA_ "GenMsgSendType" BO_ 1633 8;
BA_ "MessageIdType" BO_ 1633 10;
BA_ "GenMsgSendType" BO_ 1638 8;
BA_ "MessageIdType" BO_ 1638 10;
BA_ "GenMsgSendType" BO_ 1639 8;
BA_ "MessageIdType" BO_ 1639 10;
BA_ "GenMsgSendType" BO_ 1859 8;
BA_ "GenMsgCycleTime" BO_ 880 40;
BA_ "DiagResponse" BO_ 1848 1;
BA_ "GatewayHandlerEnum" BO_ 1848 4;
BA_ "GenMsgSendType" BO_ 1848 8;
BA_ "MessageIdType" BO_ 1848 2;
BA_ "FlexKomComment" SG_ 1089 DG_RQ_GLOBAL_UDS "Functional Diagnostic Request (UDS)";
BA_ "FlexKomIsMotorola" SG_ 1089 DG_RQ_GLOBAL_UDS 1;
BA_ "FlexKomSID" SG_ 1089 DG_RQ_GLOBAL_UDS 117443135;
BA_ "FlexKomSigLaenge" SG_ 1089 DG_RQ_GLOBAL_UDS 64;
BA_ "FlexKomSigName" SG_ 1089 DG_RQ_GLOBAL_UDS "DG_RQ_GLOBAL_UDS";
BA_ "FlexKomSigStartPos" SG_ 1089 DG_RQ_GLOBAL_UDS 7;
BA_ "FlexKomSigStartValue" SG_ 1089 DG_RQ_GLOBAL_UDS "0000000000000000h";
BA_ "GenSigSendType" SG_ 1089 DG_RQ_GLOBAL_UDS 7;
BA_ "GenSigCycleTime" SG_ 1803 D_RQ_LC 100;
BA_ "GenSigCycleTimeActive" SG_ 1803 D_RQ_LC 100;
BA_ "GenSigSendType" SG_ 1803 D_RQ_LC 1;
BA_ "GenSigCycleTime" SG_ 1820 D_RQ_SPC 100;
BA_ "GenSigCycleTimeActive" SG_ 1820 D_RQ_SPC 100;
BA_ "GenSigSendType" SG_ 1820 D_RQ_SPC 1;
BA_ "GenSigCycleTime" SG_ 390 DIS_torqueDriver 10;
BA_ "GenSigSendType" SG_ 390 DIS_torqueDriver 7;
BA_ "GenSigCycleTime" SG_ 390 DIS_torque1Counter 10;
BA_ "GenSigSendType" SG_ 390 DIS_torque1Counter 7;
BA_ "GenSigCycleTime" SG_ 390 DIS_torqueMotor 10;
BA_ "GenSigSendType" SG_ 390 DIS_torqueMotor 7;
BA_ "GenSigSNA" SG_ 390 DIS_soptState "7";
BA_ "GenSigStartValue" SG_ 390 DIS_soptState 7;
BA_ "GenSigCycleTime" SG_ 390 DIS_motorRPM 10;
BA_ "GenSigSNA" SG_ 390 DIS_motorRPM "-32768";
BA_ "GenSigSendType" SG_ 390 DIS_motorRPM 7;
BA_ "GenSigStartValue" SG_ 390 DIS_motorRPM -32768;
BA_ "GenSigCycleTime" SG_ 390 DIS_torque1Checksum 10;
BA_ "GenSigSendType" SG_ 390 DIS_torque1Checksum 7;
BA_ "FlexKomComment" SG_ 518 DI_btcRequest_FrL "Momentenanforderung ESP";
BA_ "FlexKomIsMotorola" SG_ 518 DI_btcRequest_FrL 1;
BA_ "FlexKomSID" SG_ 518 DI_btcRequest_FrL 33554835;
BA_ "FlexKomSigLaenge" SG_ 518 DI_btcRequest_FrL 40;
BA_ "FlexKomSigStartPos" SG_ 518 DI_btcRequest_FrL 15;
BA_ "FlexKomSigStartValue" SG_ 518 DI_btcRequest_FrL "8000001FFFh";
BA_ "GenSigCycleTime" SG_ 518 DI_btcRequest_FrL 10;
BA_ "FlexKomComment" SG_ 518 DI_btcRequest_FrR "Momentenanforderung ESP";
BA_ "FlexKomIsMotorola" SG_ 518 DI_btcRequest_FrR 1;
BA_ "FlexKomSID" SG_ 518 DI_btcRequest_FrR 33554835;
BA_ "FlexKomSigLaenge" SG_ 518 DI_btcRequest_FrR 40;
BA_ "FlexKomSigStartPos" SG_ 518 DI_btcRequest_FrR 15;
BA_ "FlexKomSigStartValue" SG_ 518 DI_btcRequest_FrR "8000001FFFh";
BA_ "GenSigCycleTime" SG_ 518 DI_btcRequest_FrR 10;
BA_ "FlexKomComment" SG_ 518 DI_btcRequest_ReL "Momentenanforderung ESP";
BA_ "FlexKomIsMotorola" SG_ 518 DI_btcRequest_ReL 1;
BA_ "FlexKomSID" SG_ 518 DI_btcRequest_ReL 33554835;
BA_ "FlexKomSigLaenge" SG_ 518 DI_btcRequest_ReL 40;
BA_ "FlexKomSigStartPos" SG_ 518 DI_btcRequest_ReL 15;
BA_ "FlexKomSigStartValue" SG_ 518 DI_btcRequest_ReL "8000001FFFh";
BA_ "GenSigCycleTime" SG_ 518 DI_btcRequest_ReL 10;
BA_ "FlexKomComment" SG_ 518 DI_btcRequest_ReR "Momentenanforderung ESP";
BA_ "FlexKomIsMotorola" SG_ 518 DI_btcRequest_ReR 1;
BA_ "FlexKomSID" SG_ 518 DI_btcRequest_ReR 33554835;
BA_ "FlexKomSigLaenge" SG_ 518 DI_btcRequest_ReR 40;
BA_ "FlexKomSigStartPos" SG_ 518 DI_btcRequest_ReR 15;
BA_ "FlexKomSigStartValue" SG_ 518 DI_btcRequest_ReR "8000001FFFh";
BA_ "GenSigCycleTime" SG_ 518 DI_btcRequest_ReR 10;
BA_ "FlexKomComment" SG_ 518 DI_btcRequestActive_FrR "Momentenanforderung ESP";
BA_ "FlexKomIsMotorola" SG_ 518 DI_btcRequestActive_FrR 1;
BA_ "FlexKomSID" SG_ 518 DI_btcRequestActive_FrR 33554835;
BA_ "FlexKomSigLaenge" SG_ 518 DI_btcRequestActive_FrR 40;
BA_ "FlexKomSigStartPos" SG_ 518 DI_btcRequestActive_FrR 15;
BA_ "FlexKomSigStartValue" SG_ 518 DI_btcRequestActive_FrR "8000001FFFh";
BA_ "GenSigCycleTime" SG_ 518 DI_btcRequestActive_FrR 10;
BA_ "FlexKomComment" SG_ 518 DI_btcRequestActive_ReL "Momentenanforderung ESP";
BA_ "FlexKomIsMotorola" SG_ 518 DI_btcRequestActive_ReL 1;
BA_ "FlexKomSID" SG_ 518 DI_btcRequestActive_ReL 33554835;
BA_ "FlexKomSigLaenge" SG_ 518 DI_btcRequestActive_ReL 40;
BA_ "FlexKomSigStartPos" SG_ 518 DI_btcRequestActive_ReL 15;
BA_ "FlexKomSigStartValue" SG_ 518 DI_btcRequestActive_ReL "8000001FFFh";
BA_ "GenSigCycleTime" SG_ 518 DI_btcRequestActive_ReL 10;
BA_ "FlexKomComment" SG_ 518 DI_btcRequestActive_FrL "Momentenanforderung ESP";
BA_ "FlexKomIsMotorola" SG_ 518 DI_btcRequestActive_FrL 1;
BA_ "FlexKomSID" SG_ 518 DI_btcRequestActive_FrL 33554835;
BA_ "FlexKomSigLaenge" SG_ 518 DI_btcRequestActive_FrL 40;
BA_ "FlexKomSigStartPos" SG_ 518 DI_btcRequestActive_FrL 15;
BA_ "FlexKomSigStartValue" SG_ 518 DI_btcRequestActive_FrL "8000001FFFh";
BA_ "GenSigCycleTime" SG_ 518 DI_btcRequestActive_FrL 10;
BA_ "FlexKomComment" SG_ 518 DI_btcRequestActive_ReR "Momentenanforderung ESP";
BA_ "FlexKomIsMotorola" SG_ 518 DI_btcRequestActive_ReR 1;
BA_ "FlexKomSID" SG_ 518 DI_btcRequestActive_ReR 33554835;
BA_ "FlexKomSigLaenge" SG_ 518 DI_btcRequestActive_ReR 40;
BA_ "FlexKomSigStartPos" SG_ 518 DI_btcRequestActive_ReR 15;
BA_ "FlexKomSigStartValue" SG_ 518 DI_btcRequestActive_ReR "8000001FFFh";
BA_ "GenSigCycleTime" SG_ 518 DI_btcRequestActive_ReR 10;
BA_ "GenSigSNA" SG_ 328 DI_cruiseControlEngaged "3";
BA_ "GenSigSendType" SG_ 328 DI_btcState 1;
BA_ "GenSigSNA" SG_ 328 DI_vehicleStandstillRqst "3";
BA_ "GenSigSNA" SG_ 328 DI_ptcState "3";
BA_ "GenSigSendType" SG_ 328 DI_ptcState 1;
BA_ "GenSigSendType" SG_ 328 DI_ptcActive 1;
BA_ "GenSigSNA" SG_ 328 DI_brakeCommandType "7";
BA_ "GenSigSendType" SG_ 328 DI_regenTcActive 1;
BA_ "FieldType" SG_ 1270 DI_crsState "DI_crsState";
BA_ "FieldType" SG_ 1270 DI_locState "DI_locState";
BA_ "FieldType" SG_ 872 DI_systemState "DI_systemState";
BA_ "GenSigSendType" SG_ 872 DI_driveReady 1;
BA_ "GenSigSendType" SG_ 872 DI_regenLight 1;
BA_ "FieldType" SG_ 872 DI_state "DI_state";
BA_ "GenSigSNA" SG_ 872 DI_analogSpeed "4095";
BA_ "GenSigStartValue" SG_ 872 DI_analogSpeed 4095;
BA_ "FieldType" SG_ 872 DI_immobilizerState "DI_immobilizerState";
BA_ "GenSigSNA" SG_ 872 DI_immobilizerState "0";
BA_ "GenSigSNA" SG_ 872 DI_digitalSpeed "511";
BA_ "GenSigStartValue" SG_ 872 DI_digitalSpeed 511;
BA_ "FieldType" SG_ 872 DI_aebState "DI_aebState";
BA_ "GenSigSNA" SG_ 872 DI_aebState "7";
BA_ "GenSigSNA" SG_ 1016 DI_autoparkState "15";
BA_ "FieldType" SG_ 1016 DI_tractionControlMode "DI_tractionControlMode";
BA_ "FieldType" SG_ 1016 DI_parkBrakeState "DI_parkBrakeState";
BA_ "GenSigSNA" SG_ 1016 DI_parkBrakeState "15";
BA_ "FieldType" SG_ 1016 DI_pmmStatus "DI_pmmStatus";
BA_ "GenSigSNA" SG_ 1016 DI_pmmStatus "3";
BA_ "FieldType" SG_ 1016 DI_onePedalDrivingState "DI_onePedalDrivingState";
BA_ "GenSigCycleTime" SG_ 264 DI_torqueDriver 10;
BA_ "GenSigSNA" SG_ 264 DI_torqueDriver "-4096";
BA_ "GenSigSendType" SG_ 264 DI_torqueDriver 7;
BA_ "GenSigStartValue" SG_ 264 DI_torqueDriver -4096;
BA_ "GenSigCycleTime" SG_ 264 DI_torque1Counter 10;
BA_ "GenSigSendType" SG_ 264 DI_torque1Counter 7;
BA_ "GenSigCycleTime" SG_ 264 DI_torqueMotor 10;
BA_ "GenSigSNA" SG_ 264 DI_torqueMotor "-4096";
BA_ "GenSigSendType" SG_ 264 DI_torqueMotor 7;
BA_ "GenSigStartValue" SG_ 264 DI_torqueMotor -4096;
BA_ "GenSigSNA" SG_ 264 DI_soptState "7";
BA_ "GenSigSendType" SG_ 264 DI_soptState 7;
BA_ "GenSigStartValue" SG_ 264 DI_soptState 7;
BA_ "GenSigCycleTime" SG_ 264 DI_motorRPM 10;
BA_ "GenSigSNA" SG_ 264 DI_motorRPM "-32768";
BA_ "GenSigSendType" SG_ 264 DI_motorRPM 7;
BA_ "GenSigStartValue" SG_ 264 DI_motorRPM -32768;
BA_ "GenSigCycleTime" SG_ 264 DI_pedalPos 10;
BA_ "GenSigSNA" SG_ 264 DI_pedalPos "255";
BA_ "GenSigSendType" SG_ 264 DI_pedalPos 7;
BA_ "GenSigStartValue" SG_ 264 DI_pedalPos 255;
BA_ "GenSigCycleTime" SG_ 264 DI_torque1Checksum 10;
BA_ "GenSigSendType" SG_ 264 DI_torque1Checksum 7;
BA_ "GenSigSNA" SG_ 280 DI_torqueEstimate "-2048";
BA_ "GenSigSendType" SG_ 280 DI_torqueEstimate 7;
BA_ "GenSigCycleTime" SG_ 280 DI_gear 10;
BA_ "GenSigSNA" SG_ 280 DI_gear "7";
BA_ "GenSigSendType" SG_ 280 DI_gear 7;
BA_ "GenSigCycleTime" SG_ 280 DI_brakePedal 10;
BA_ "GenSigSendType" SG_ 280 DI_brakePedal 7;
BA_ "GenSigSNA" SG_ 280 DI_vehicleSpeed "4095";
BA_ "GenSigStartValue" SG_ 280 DI_vehicleSpeed 500;
BA_ "GenSigCycleTime" SG_ 280 DI_gearRequest 10;
BA_ "GenSigSNA" SG_ 280 DI_gearRequest "7";
BA_ "GenSigSendType" SG_ 280 DI_gearRequest 7;
BA_ "GenSigSendType" SG_ 280 DI_torqueInterfaceFailure 7;
BA_ "GenSigCycleTime" SG_ 280 DI_torque2Counter 10;
BA_ "GenSigSendType" SG_ 280 DI_torque2Counter 7;
BA_ "GenSigCycleTime" SG_ 280 DI_brakePedalState 10;
BA_ "GenSigSNA" SG_ 280 DI_brakePedalState "3";
BA_ "GenSigSendType" SG_ 280 DI_brakePedalState 7;
BA_ "GenSigCycleTime" SG_ 280 DI_epbParkRequest 10;
BA_ "GenSigSendType" SG_ 280 DI_epbParkRequest 7;
BA_ "GenSigCycleTime" SG_ 280 DI_torque2Checksum 10;
BA_ "GenSigSendType" SG_ 280 DI_torque2Checksum 7;
BA_ "FieldType" SG_ 281 DI_vdcCommandTypeFrL "DI_vdcCommandType";
BA_ "FieldType" SG_ 281 DI_vdcCommandTypeReL "DI_vdcCommandType";
BA_ "FieldType" SG_ 281 DI_vdcCommandABSFrL "DI_vdcCommandABS";
BA_ "FieldType" SG_ 281 DI_vdcCommandABSReL "DI_vdcCommandABS";
BA_ "GenSigSNA" SG_ 281 DI_brakeTorqueTarFrL "4095";
BA_ "GenSigSNA" SG_ 281 DI_brakeTorqueTarReL "4095";
BA_ "GenSigSNA" SG_ 281 DI_wheelSlipLimitFrL "255";
BA_ "GenSigSNA" SG_ 281 DI_wheelSlipLimitReL "63";
BA_ "FieldType" SG_ 282 DI_vdcCommandTypeFrR "DI_vdcCommandType";
BA_ "FieldType" SG_ 282 DI_vdcCommandTypeReR "DI_vdcCommandType";
BA_ "FieldType" SG_ 282 DI_vdcCommandABSFrR "DI_vdcCommandABS";
BA_ "FieldType" SG_ 282 DI_vdcCommandABSReR "DI_vdcCommandABS";
BA_ "GenSigSNA" SG_ 282 DI_brakeTorqueTarFrR "4095";
BA_ "GenSigSNA" SG_ 282 DI_brakeTorqueTarReR "4095";
BA_ "GenSigSNA" SG_ 282 DI_wheelSlipLimitFrR "255";
BA_ "GenSigSNA" SG_ 282 DI_wheelSlipLimitReR "63";
BA_ "FlexKomComment" SG_ 512 DPM_MdLmt_Rq "Decentral power management state";
BA_ "FlexKomIsMotorola" SG_ 512 DPM_MdLmt_Rq 1;
BA_ "FlexKomSID" SG_ 512 DPM_MdLmt_Rq 117443167;
BA_ "FlexKomSigLaenge" SG_ 512 DPM_MdLmt_Rq 8;
BA_ "FlexKomSigName" SG_ 512 DPM_MdLmt_Rq "DPM_Stat";
BA_ "FlexKomSigStartPos" SG_ 512 DPM_MdLmt_Rq 7;
BA_ "FlexKomSigStartValue" SG_ 512 DPM_MdLmt_Rq "0Ah";
BA_ "GenSigCycleTime" SG_ 512 DPM_MdLmt_Rq 1000;
BA_ "GenSigSNA" SG_ 512 DPM_MdLmt_Rq "3";
BA_ "GenSigSendType" SG_ 512 DPM_MdLmt_Rq 5;
BA_ "GenSigStartValue" SG_ 512 DPM_MdLmt_Rq 2;
BA_ "GenSigTimeout_DRVU" SG_ 512 DPM_MdLmt_Rq 10500;
BA_ "GenSigTimeout_ORC" SG_ 512 DPM_MdLmt_Rq 10500;
BA_ "GenSigTimeout_RBTM_FL" SG_ 512 DPM_MdLmt_Rq 10500;
BA_ "GenSigTimeout_RBTM_FR" SG_ 512 DPM_MdLmt_Rq 10500;
BA_ "GenSigTimeout_SCCM" SG_ 512 DPM_MdLmt_Rq 10500;
BA_ "FlexKomComment" SG_ 512 DPM_ExtMd_Enbl_Rq "Decentral power management state";
BA_ "FlexKomIsMotorola" SG_ 512 DPM_ExtMd_Enbl_Rq 1;
BA_ "FlexKomSID" SG_ 512 DPM_ExtMd_Enbl_Rq 117443167;
BA_ "FlexKomSigLaenge" SG_ 512 DPM_ExtMd_Enbl_Rq 8;
BA_ "FlexKomSigName" SG_ 512 DPM_ExtMd_Enbl_Rq "DPM_Stat";
BA_ "FlexKomSigStartPos" SG_ 512 DPM_ExtMd_Enbl_Rq 7;
BA_ "FlexKomSigStartValue" SG_ 512 DPM_ExtMd_Enbl_Rq "0Ah";
BA_ "GenSigCycleTime" SG_ 512 DPM_ExtMd_Enbl_Rq 1000;
BA_ "GenSigSNA" SG_ 512 DPM_ExtMd_Enbl_Rq "3";
BA_ "GenSigSendType" SG_ 512 DPM_ExtMd_Enbl_Rq 5;
BA_ "GenSigStartValue" SG_ 512 DPM_ExtMd_Enbl_Rq 2;
BA_ "GenSigTimeout_DRVU" SG_ 512 DPM_ExtMd_Enbl_Rq 10500;
BA_ "GenSigTimeout_ORC" SG_ 512 DPM_ExtMd_Enbl_Rq 10500;
BA_ "GenSigTimeout_RBTM_FL" SG_ 512 DPM_ExtMd_Enbl_Rq 10500;
BA_ "GenSigTimeout_RBTM_FR" SG_ 512 DPM_ExtMd_Enbl_Rq 10500;
BA_ "GenSigTimeout_SCCM" SG_ 512 DPM_ExtMd_Enbl_Rq 10500;
BA_ "FlexKomComment" SG_ 1570 D_RQ_SCCM "Diagnostic Request";
BA_ "FlexKomIsMotorola" SG_ 1570 D_RQ_SCCM 1;
BA_ "FlexKomSID" SG_ 1570 D_RQ_SCCM 117441851;
BA_ "FlexKomSigLaenge" SG_ 1570 D_RQ_SCCM 64;
BA_ "FlexKomSigName" SG_ 1570 D_RQ_SCCM "D_RQ_SCCM";
BA_ "FlexKomSigStartPos" SG_ 1570 D_RQ_SCCM 7;
BA_ "FlexKomSigStartValue" SG_ 1570 D_RQ_SCCM "0000000000000000h";
BA_ "GenSigSendType" SG_ 1570 D_RQ_SCCM 7;
BA_ "FlexKomComment" SG_ 1156 D_RS_SCCM "Diagnostic Response";
BA_ "FlexKomIsMotorola" SG_ 1156 D_RS_SCCM 1;
BA_ "FlexKomSID" SG_ 1156 D_RS_SCCM 117441586;
BA_ "FlexKomSigLaenge" SG_ 1156 D_RS_SCCM 64;
BA_ "FlexKomSigName" SG_ 1156 D_RS_SCCM "D_RS_SCCM";
BA_ "FlexKomSigStartPos" SG_ 1156 D_RS_SCCM 7;
BA_ "FlexKomSigStartValue" SG_ 1156 D_RS_SCCM "0000000000000000h";
BA_ "GenSigStartValue" SG_ 360 GTW_cruiseControlStatus 7;
BA_ "GenSigStartValue" SG_ 360 GTW_counter4 15;
BA_ "GenSigStartValue" SG_ 360 GTW_speedLimiterStatus 7;
BA_ "GenSigStartValue" SG_ 360 GTW_engineStatus 7;
BA_ "GenSigSendType" SG_ 360 GTW_ignitionResult 1;
BA_ "Gatewaysignal" SG_ 360 GTW_nEngine 1;
BA_ "GenSigStartValue" SG_ 360 GTW_nEngine 65535;
BA_ "GenSigStartValue" SG_ 360 GTW_checksum4 255;
BA_ "FieldType" SG_ 527 EFUSE_airCompressorStatus "EFUSE_airCompressorStatus";
BA_ "GenSigSNA" SG_ 527 EFUSE_airCompressorStatus "7";
BA_ "FieldType" SG_ 527 EFUSE_loadshedStatus "EFUSE_loadshedLevel";
BA_ "GenSigSNA" SG_ 527 EFUSE_loadshedStatus "0";
BA_ "FlexKomComment" SG_ 1 ISw_Stat "EIS state";
BA_ "FlexKomIsMotorola" SG_ 1 ISw_Stat 1;
BA_ "FlexKomSID" SG_ 1 ISw_Stat 117440590;
BA_ "FlexKomSigLaenge" SG_ 1 ISw_Stat 64;
BA_ "FlexKomSigName" SG_ 1 ISw_Stat "EIS_Stat";
BA_ "FlexKomSigStartPos" SG_ 1 ISw_Stat 7;
BA_ "FlexKomSigStartValue" SG_ 1 ISw_Stat "07C0FFFCFF0007FFh";
BA_ "GenSigCycleTime" SG_ 1 ISw_Stat 100;
BA_ "GenSigSNA" SG_ 1 ISw_Stat "7";
BA_ "GenSigSendType" SG_ 1 ISw_Stat 5;
BA_ "GenSigStartValue" SG_ 1 ISw_Stat 7;
BA_ "GenSigTimeout_DRVU" SG_ 1 ISw_Stat 1050;
BA_ "GenSigTimeout_ESP_ABR" SG_ 1 ISw_Stat 1550;
BA_ "GenSigTimeout_IC" SG_ 1 ISw_Stat 1050;
BA_ "GenSigTimeout_MPC" SG_ 1 ISw_Stat 1050;
BA_ "GenSigTimeout_ORC" SG_ 1 ISw_Stat 1050;
BA_ "GenSigTimeout_PTS" SG_ 1 ISw_Stat 1050;
BA_ "GenSigTimeout_RBTM_FL" SG_ 1 ISw_Stat 1050;
BA_ "GenSigTimeout_RBTM_FR" SG_ 1 ISw_Stat 1050;
BA_ "GenSigTimeout_SCCM" SG_ 1 ISw_Stat 1050;
BA_ "GenSigTimeout_SPC" SG_ 1 ISw_Stat 1050;
BA_ "GenSigTimeout_TPM" SG_ 1 ISw_Stat 1550;
BA_ "FlexKomComment" SG_ 1 Ign_On_StProc_Inact "EIS state";
BA_ "FlexKomIsMotorola" SG_ 1 Ign_On_StProc_Inact 1;
BA_ "FlexKomSID" SG_ 1 Ign_On_StProc_Inact 117440590;
BA_ "FlexKomSigLaenge" SG_ 1 Ign_On_StProc_Inact 64;
BA_ "FlexKomSigName" SG_ 1 Ign_On_StProc_Inact "EIS_Stat";
BA_ "FlexKomSigStartPos" SG_ 1 Ign_On_StProc_Inact 7;
BA_ "FlexKomSigStartValue" SG_ 1 Ign_On_StProc_Inact "07C0FFFCFF0007FFh";
BA_ "GenSigCycleTime" SG_ 1 Ign_On_StProc_Inact 100;
BA_ "GenSigSendType" SG_ 1 Ign_On_StProc_Inact 5;
BA_ "GenSigTimeout_ORC" SG_ 1 Ign_On_StProc_Inact 1050;
BA_ "GenSigTimeout_RBTM_FL" SG_ 1 Ign_On_StProc_Inact 1050;
BA_ "GenSigTimeout_RBTM_FR" SG_ 1 Ign_On_StProc_Inact 1050;
BA_ "GenSigTimeout_TPM" SG_ 1 Ign_On_StProc_Inact 1550;
BA_ "FlexKomComment" SG_ 1 TxPkPosn_Rq "EIS state";
BA_ "FlexKomIsMotorola" SG_ 1 TxPkPosn_Rq 1;
BA_ "FlexKomSID" SG_ 1 TxPkPosn_Rq 117440590;
BA_ "FlexKomSigLaenge" SG_ 1 TxPkPosn_Rq 64;
BA_ "FlexKomSigName" SG_ 1 TxPkPosn_Rq "EIS_Stat";
BA_ "FlexKomSigStartPos" SG_ 1 TxPkPosn_Rq 7;
BA_ "FlexKomSigStartValue" SG_ 1 TxPkPosn_Rq "07C0FFFCFF0007FFh";
BA_ "GenSigCycleTime" SG_ 1 TxPkPosn_Rq 100;
BA_ "GenSigSendType" SG_ 1 TxPkPosn_Rq 5;
BA_ "FlexKomComment" SG_ 1 TxPkPosn_Emg_Rq "EIS state";
BA_ "FlexKomIsMotorola" SG_ 1 TxPkPosn_Emg_Rq 1;
BA_ "FlexKomSID" SG_ 1 TxPkPosn_Emg_Rq 117440590;
BA_ "FlexKomSigLaenge" SG_ 1 TxPkPosn_Emg_Rq 64;
BA_ "FlexKomSigName" SG_ 1 TxPkPosn_Emg_Rq "EIS_Stat";
BA_ "FlexKomSigStartPos" SG_ 1 TxPkPosn_Emg_Rq 7;
BA_ "FlexKomSigStartValue" SG_ 1 TxPkPosn_Emg_Rq "07C0FFFCFF0007FFh";
BA_ "GenSigCycleTime" SG_ 1 TxPkPosn_Emg_Rq 100;
BA_ "GenSigSendType" SG_ 1 TxPkPosn_Emg_Rq 5;
BA_ "FlexKomComment" SG_ 1 TxPkPosnAuto_Enbl "EIS state";
BA_ "FlexKomIsMotorola" SG_ 1 TxPkPosnAuto_Enbl 1;
BA_ "FlexKomSID" SG_ 1 TxPkPosnAuto_Enbl 117440590;
BA_ "FlexKomSigLaenge" SG_ 1 TxPkPosnAuto_Enbl 64;
BA_ "FlexKomSigName" SG_ 1 TxPkPosnAuto_Enbl "EIS_Stat";
BA_ "FlexKomSigStartPos" SG_ 1 TxPkPosnAuto_Enbl 7;
BA_ "FlexKomSigStartValue" SG_ 1 TxPkPosnAuto_Enbl "07C0FFFCFF0007FFh";
BA_ "GenSigCycleTime" SG_ 1 TxPkPosnAuto_Enbl 100;
BA_ "GenSigSendType" SG_ 1 TxPkPosnAuto_Enbl 5;
BA_ "FlexKomComment" SG_ 1 TxPkPosn_Rq_SBC_Enbl "EIS state";
BA_ "FlexKomIsMotorola" SG_ 1 TxPkPosn_Rq_SBC_Enbl 1;
BA_ "FlexKomSID" SG_ 1 TxPkPosn_Rq_SBC_Enbl 117440590;
BA_ "FlexKomSigLaenge" SG_ 1 TxPkPosn_Rq_SBC_Enbl 64;
BA_ "FlexKomSigName" SG_ 1 TxPkPosn_Rq_SBC_Enbl "EIS_Stat";
BA_ "FlexKomSigStartPos" SG_ 1 TxPkPosn_Rq_SBC_Enbl 7;
BA_ "FlexKomSigStartValue" SG_ 1 TxPkPosn_Rq_SBC_Enbl "07C0FFFCFF0007FFh";
BA_ "GenSigCycleTime" SG_ 1 TxPkPosn_Rq_SBC_Enbl 100;
BA_ "GenSigSendType" SG_ 1 TxPkPosn_Rq_SBC_Enbl 5;
BA_ "GenSigTimeout_ESP_ABR" SG_ 1 TxPkPosn_Rq_SBC_Enbl 1550;
BA_ "FlexKomComment" SG_ 1 KG_IgnCtrl_Actv "EIS state";
BA_ "FlexKomIsMotorola" SG_ 1 KG_IgnCtrl_Actv 1;
BA_ "FlexKomSID" SG_ 1 KG_IgnCtrl_Actv 117440590;
BA_ "FlexKomSigLaenge" SG_ 1 KG_IgnCtrl_Actv 64;
BA_ "FlexKomSigName" SG_ 1 KG_IgnCtrl_Actv "EIS_Stat";
BA_ "FlexKomSigStartPos" SG_ 1 KG_IgnCtrl_Actv 7;
BA_ "FlexKomSigStartValue" SG_ 1 KG_IgnCtrl_Actv "07C0FFFCFF0007FFh";
BA_ "GenSigCycleTime" SG_ 1 KG_IgnCtrl_Actv 100;
BA_ "GenSigSendType" SG_ 1 KG_IgnCtrl_Actv 5;
BA_ "FlexKomComment" SG_ 1 EngSt_Enbl_Rq_KG "EIS state";
BA_ "FlexKomIsMotorola" SG_ 1 EngSt_Enbl_Rq_KG 1;
BA_ "FlexKomSID" SG_ 1 EngSt_Enbl_Rq_KG 117440590;
BA_ "FlexKomSigLaenge" SG_ 1 EngSt_Enbl_Rq_KG 64;
BA_ "FlexKomSigName" SG_ 1 EngSt_Enbl_Rq_KG "EIS_Stat";
BA_ "FlexKomSigStartPos" SG_ 1 EngSt_Enbl_Rq_KG 7;
BA_ "FlexKomSigStartValue" SG_ 1 EngSt_Enbl_Rq_KG "07C0FFFCFF0007FFh";
BA_ "GenSigCycleTime" SG_ 1 EngSt_Enbl_Rq_KG 100;
BA_ "GenSigSendType" SG_ 1 EngSt_Enbl_Rq_KG 5;
BA_ "FlexKomComment" SG_ 1 KG_StSw_Psd "EIS state";
BA_ "FlexKomIsMotorola" SG_ 1 KG_StSw_Psd 1;
BA_ "FlexKomSID" SG_ 1 KG_StSw_Psd 117440590;
BA_ "FlexKomSigLaenge" SG_ 1 KG_StSw_Psd 64;
BA_ "FlexKomSigName" SG_ 1 KG_StSw_Psd "EIS_Stat";
BA_ "FlexKomSigStartPos" SG_ 1 KG_StSw_Psd 7;
BA_ "FlexKomSigStartValue" SG_ 1 KG_StSw_Psd "07C0FFFCFF0007FFh";
BA_ "GenSigCycleTime" SG_ 1 KG_StSw_Psd 100;
BA_ "GenSigSendType" SG_ 1 KG_StSw_Psd 5;
BA_ "FlexKomComment" SG_ 1 AutoDrLk_Rq_Src "EIS state";
BA_ "FlexKomIsMotorola" SG_ 1 AutoDrLk_Rq_Src 1;
BA_ "FlexKomSID" SG_ 1 AutoDrLk_Rq_Src 117440590;
BA_ "FlexKomSigLaenge" SG_ 1 AutoDrLk_Rq_Src 64;
BA_ "FlexKomSigName" SG_ 1 AutoDrLk_Rq_Src "EIS_Stat";
BA_ "FlexKomSigStartPos" SG_ 1 AutoDrLk_Rq_Src 7;
BA_ "FlexKomSigStartValue" SG_ 1 AutoDrLk_Rq_Src "07C0FFFCFF0007FFh";
BA_ "GenSigCycleTime" SG_ 1 AutoDrLk_Rq_Src 100;
BA_ "GenSigSNA" SG_ 1 AutoDrLk_Rq_Src "3";
BA_ "GenSigSendType" SG_ 1 AutoDrLk_Rq_Src 5;
BA_ "GenSigStartValue" SG_ 1 AutoDrLk_Rq_Src 3;
BA_ "FlexKomComment" SG_ 1 AutoDrLk_Stat "EIS state";
BA_ "FlexKomIsMotorola" SG_ 1 AutoDrLk_Stat 1;
BA_ "FlexKomSID" SG_ 1 AutoDrLk_Stat 117440590;
BA_ "FlexKomSigLaenge" SG_ 1 AutoDrLk_Stat 64;
BA_ "FlexKomSigName" SG_ 1 AutoDrLk_Stat "EIS_Stat";
BA_ "FlexKomSigStartPos" SG_ 1 AutoDrLk_Stat 7;
BA_ "FlexKomSigStartValue" SG_ 1 AutoDrLk_Stat "07C0FFFCFF0007FFh";
BA_ "GenSigCycleTime" SG_ 1 AutoDrLk_Stat 100;
BA_ "GenSigSNA" SG_ 1 AutoDrLk_Stat "3";
BA_ "GenSigSendType" SG_ 1 AutoDrLk_Stat 5;
BA_ "GenSigStartValue" SG_ 1 AutoDrLk_Stat 3;
BA_ "GenSigTimeout_IC" SG_ 1 AutoDrLk_Stat 1050;
BA_ "FlexKomComment" SG_ 1 SPCR_Conf_EIS "EIS state";
BA_ "FlexKomIsMotorola" SG_ 1 SPCR_Conf_EIS 1;
BA_ "FlexKomSID" SG_ 1 SPCR_Conf_EIS 117440590;
BA_ "FlexKomSigLaenge" SG_ 1 SPCR_Conf_EIS 64;
BA_ "FlexKomSigName" SG_ 1 SPCR_Conf_EIS "EIS_Stat";
BA_ "FlexKomSigStartPos" SG_ 1 SPCR_Conf_EIS 7;
BA_ "FlexKomSigStartValue" SG_ 1 SPCR_Conf_EIS "07C0FFFCFF0007FFh";
BA_ "GenSigCycleTime" SG_ 1 SPCR_Conf_EIS 100;
BA_ "GenSigSNA" SG_ 1 SPCR_Conf_EIS "3";
BA_ "GenSigSendType" SG_ 1 SPCR_Conf_EIS 5;
BA_ "GenSigTimeout_ESP_ABR" SG_ 1 SPCR_Conf_EIS 1550;
BA_ "FlexKomComment" SG_ 1 CLkS_DL_Stat "EIS state";
BA_ "FlexKomIsMotorola" SG_ 1 CLkS_DL_Stat 1;
BA_ "FlexKomSID" SG_ 1 CLkS_DL_Stat 117440590;
BA_ "FlexKomSigLaenge" SG_ 1 CLkS_DL_Stat 64;
BA_ "FlexKomSigName" SG_ 1 CLkS_DL_Stat "EIS_Stat";
BA_ "FlexKomSigStartPos" SG_ 1 CLkS_DL_Stat 7;
BA_ "FlexKomSigStartValue" SG_ 1 CLkS_DL_Stat "07C0FFFCFF0007FFh";
BA_ "GenSigCycleTime" SG_ 1 CLkS_DL_Stat 100;
BA_ "GenSigSNA" SG_ 1 CLkS_DL_Stat "3";
BA_ "GenSigSendType" SG_ 1 CLkS_DL_Stat 5;
BA_ "GenSigStartValue" SG_ 1 CLkS_DL_Stat 3;
BA_ "FlexKomComment" SG_ 1 CLkS_Gas_Dr_Stat "EIS state";
BA_ "FlexKomIsMotorola" SG_ 1 CLkS_Gas_Dr_Stat 1;
BA_ "FlexKomSID" SG_ 1 CLkS_Gas_Dr_Stat 117440590;
BA_ "FlexKomSigLaenge" SG_ 1 CLkS_Gas_Dr_Stat 64;
BA_ "FlexKomSigName" SG_ 1 CLkS_Gas_Dr_Stat "EIS_Stat";
BA_ "FlexKomSigStartPos" SG_ 1 CLkS_Gas_Dr_Stat 7;
BA_ "FlexKomSigStartValue" SG_ 1 CLkS_Gas_Dr_Stat "07C0FFFCFF0007FFh";
BA_ "GenSigCycleTime" SG_ 1 CLkS_Gas_Dr_Stat 100;
BA_ "GenSigSNA" SG_ 1 CLkS_Gas_Dr_Stat "3";
BA_ "GenSigSendType" SG_ 1 CLkS_Gas_Dr_Stat 5;
BA_ "GenSigStartValue" SG_ 1 CLkS_Gas_Dr_Stat 3;
BA_ "FlexKomComment" SG_ 1 CLkS_Dr_FL_Stat "EIS state";
BA_ "FlexKomIsMotorola" SG_ 1 CLkS_Dr_FL_Stat 1;
BA_ "FlexKomSID" SG_ 1 CLkS_Dr_FL_Stat 117440590;
BA_ "FlexKomSigLaenge" SG_ 1 CLkS_Dr_FL_Stat 64;
BA_ "FlexKomSigName" SG_ 1 CLkS_Dr_FL_Stat "EIS_Stat";
BA_ "FlexKomSigStartPos" SG_ 1 CLkS_Dr_FL_Stat 7;
BA_ "FlexKomSigStartValue" SG_ 1 CLkS_Dr_FL_Stat "07C0FFFCFF0007FFh";
BA_ "GenSigCycleTime" SG_ 1 CLkS_Dr_FL_Stat 100;
BA_ "GenSigSNA" SG_ 1 CLkS_Dr_FL_Stat "3";
BA_ "GenSigSendType" SG_ 1 CLkS_Dr_FL_Stat 5;
BA_ "GenSigStartValue" SG_ 1 CLkS_Dr_FL_Stat 3;
BA_ "GenSigTimeout_ORC" SG_ 1 CLkS_Dr_FL_Stat 1050;
BA_ "FlexKomComment" SG_ 1 CLkS_Dr_FR_Stat "EIS state";
BA_ "FlexKomIsMotorola" SG_ 1 CLkS_Dr_FR_Stat 1;
BA_ "FlexKomSID" SG_ 1 CLkS_Dr_FR_Stat 117440590;
BA_ "FlexKomSigLaenge" SG_ 1 CLkS_Dr_FR_Stat 64;
BA_ "FlexKomSigName" SG_ 1 CLkS_Dr_FR_Stat "EIS_Stat";
BA_ "FlexKomSigStartPos" SG_ 1 CLkS_Dr_FR_Stat 7;
BA_ "FlexKomSigStartValue" SG_ 1 CLkS_Dr_FR_Stat "07C0FFFCFF0007FFh";
BA_ "GenSigCycleTime" SG_ 1 CLkS_Dr_FR_Stat 100;
BA_ "GenSigSNA" SG_ 1 CLkS_Dr_FR_Stat "3";
BA_ "GenSigSendType" SG_ 1 CLkS_Dr_FR_Stat 5;
BA_ "GenSigStartValue" SG_ 1 CLkS_Dr_FR_Stat 3;
BA_ "GenSigTimeout_ORC" SG_ 1 CLkS_Dr_FR_Stat 1050;
BA_ "FlexKomComment" SG_ 1 CLkS_Dr_RL_Stat "EIS state";
BA_ "FlexKomIsMotorola" SG_ 1 CLkS_Dr_RL_Stat 1;
BA_ "FlexKomSID" SG_ 1 CLkS_Dr_RL_Stat 117440590;
BA_ "FlexKomSigLaenge" SG_ 1 CLkS_Dr_RL_Stat 64;
BA_ "FlexKomSigName" SG_ 1 CLkS_Dr_RL_Stat "EIS_Stat";
BA_ "FlexKomSigStartPos" SG_ 1 CLkS_Dr_RL_Stat 7;
BA_ "FlexKomSigStartValue" SG_ 1 CLkS_Dr_RL_Stat "07C0FFFCFF0007FFh";
BA_ "GenSigCycleTime" SG_ 1 CLkS_Dr_RL_Stat 100;
BA_ "GenSigSNA" SG_ 1 CLkS_Dr_RL_Stat "3";
BA_ "GenSigSendType" SG_ 1 CLkS_Dr_RL_Stat 5;
BA_ "GenSigStartValue" SG_ 1 CLkS_Dr_RL_Stat 3;
BA_ "GenSigTimeout_ORC" SG_ 1 CLkS_Dr_RL_Stat 1050;
BA_ "FlexKomComment" SG_ 1 CLkS_Dr_RR_Stat "EIS state";
BA_ "FlexKomIsMotorola" SG_ 1 CLkS_Dr_RR_Stat 1;
BA_ "FlexKomSID" SG_ 1 CLkS_Dr_RR_Stat 117440590;
BA_ "FlexKomSigLaenge" SG_ 1 CLkS_Dr_RR_Stat 64;
BA_ "FlexKomSigName" SG_ 1 CLkS_Dr_RR_Stat "EIS_Stat";
BA_ "FlexKomSigStartPos" SG_ 1 CLkS_Dr_RR_Stat 7;
BA_ "FlexKomSigStartValue" SG_ 1 CLkS_Dr_RR_Stat "07C0FFFCFF0007FFh";
BA_ "GenSigCycleTime" SG_ 1 CLkS_Dr_RR_Stat 100;
BA_ "GenSigSNA" SG_ 1 CLkS_Dr_RR_Stat "3";
BA_ "GenSigSendType" SG_ 1 CLkS_Dr_RR_Stat 5;
BA_ "GenSigStartValue" SG_ 1 CLkS_Dr_RR_Stat 3;
BA_ "GenSigTimeout_ORC" SG_ 1 CLkS_Dr_RR_Stat 1050;
BA_ "FlexKomComment" SG_ 1 KeyLine1_Appr "EIS state";
BA_ "FlexKomIsMotorola" SG_ 1 KeyLine1_Appr 1;
BA_ "FlexKomSID" SG_ 1 KeyLine1_Appr 117440590;
BA_ "FlexKomSigLaenge" SG_ 1 KeyLine1_Appr 64;
BA_ "FlexKomSigName" SG_ 1 KeyLine1_Appr "EIS_Stat";
BA_ "FlexKomSigStartPos" SG_ 1 KeyLine1_Appr 7;
BA_ "FlexKomSigStartValue" SG_ 1 KeyLine1_Appr "07C0FFFCFF0007FFh";
BA_ "GenSigCycleTime" SG_ 1 KeyLine1_Appr 100;
BA_ "GenSigSendType" SG_ 1 KeyLine1_Appr 5;
BA_ "FlexKomComment" SG_ 1 KeyLine2_Appr "EIS state";
BA_ "FlexKomIsMotorola" SG_ 1 KeyLine2_Appr 1;
BA_ "FlexKomSID" SG_ 1 KeyLine2_Appr 117440590;
BA_ "FlexKomSigLaenge" SG_ 1 KeyLine2_Appr 64;
BA_ "FlexKomSigName" SG_ 1 KeyLine2_Appr "EIS_Stat";
BA_ "FlexKomSigStartPos" SG_ 1 KeyLine2_Appr 7;
BA_ "FlexKomSigStartValue" SG_ 1 KeyLine2_Appr "07C0FFFCFF0007FFh";
BA_ "GenSigCycleTime" SG_ 1 KeyLine2_Appr 100;
BA_ "GenSigSendType" SG_ 1 KeyLine2_Appr 5;
BA_ "FlexKomComment" SG_ 1 KeyLine3_Appr "EIS state";
BA_ "FlexKomIsMotorola" SG_ 1 KeyLine3_Appr 1;
BA_ "FlexKomSID" SG_ 1 KeyLine3_Appr 117440590;
BA_ "FlexKomSigLaenge" SG_ 1 KeyLine3_Appr 64;
BA_ "FlexKomSigName" SG_ 1 KeyLine3_Appr "EIS_Stat";
BA_ "FlexKomSigStartPos" SG_ 1 KeyLine3_Appr 7;
BA_ "FlexKomSigStartValue" SG_ 1 KeyLine3_Appr "07C0FFFCFF0007FFh";
BA_ "GenSigCycleTime" SG_ 1 KeyLine3_Appr 100;
BA_ "GenSigSendType" SG_ 1 KeyLine3_Appr 5;
BA_ "FlexKomComment" SG_ 1 KeyLine4_Appr "EIS state";
BA_ "FlexKomIsMotorola" SG_ 1 KeyLine4_Appr 1;
BA_ "FlexKomSID" SG_ 1 KeyLine4_Appr 117440590;
BA_ "FlexKomSigLaenge" SG_ 1 KeyLine4_Appr 64;
BA_ "FlexKomSigName" SG_ 1 KeyLine4_Appr "EIS_Stat";
BA_ "FlexKomSigStartPos" SG_ 1 KeyLine4_Appr 7;
BA_ "FlexKomSigStartValue" SG_ 1 KeyLine4_Appr "07C0FFFCFF0007FFh";
BA_ "GenSigCycleTime" SG_ 1 KeyLine4_Appr 100;
BA_ "GenSigSendType" SG_ 1 KeyLine4_Appr 5;
BA_ "FlexKomComment" SG_ 1 KeyLine5_Appr "EIS state";
BA_ "FlexKomIsMotorola" SG_ 1 KeyLine5_Appr 1;
BA_ "FlexKomSID" SG_ 1 KeyLine5_Appr 117440590;
BA_ "FlexKomSigLaenge" SG_ 1 KeyLine5_Appr 64;
BA_ "FlexKomSigName" SG_ 1 KeyLine5_Appr "EIS_Stat";
BA_ "FlexKomSigStartPos" SG_ 1 KeyLine5_Appr 7;
BA_ "FlexKomSigStartValue" SG_ 1 KeyLine5_Appr "07C0FFFCFF0007FFh";
BA_ "GenSigCycleTime" SG_ 1 KeyLine5_Appr 100;
BA_ "GenSigSendType" SG_ 1 KeyLine5_Appr 5;
BA_ "FlexKomComment" SG_ 1 KeyLine6_Appr "EIS state";
BA_ "FlexKomIsMotorola" SG_ 1 KeyLine6_Appr 1;
BA_ "FlexKomSID" SG_ 1 KeyLine6_Appr 117440590;
BA_ "FlexKomSigLaenge" SG_ 1 KeyLine6_Appr 64;
BA_ "FlexKomSigName" SG_ 1 KeyLine6_Appr "EIS_Stat";
BA_ "FlexKomSigStartPos" SG_ 1 KeyLine6_Appr 7;
BA_ "FlexKomSigStartValue" SG_ 1 KeyLine6_Appr "07C0FFFCFF0007FFh";
BA_ "GenSigCycleTime" SG_ 1 KeyLine6_Appr 100;
BA_ "GenSigSendType" SG_ 1 KeyLine6_Appr 5;
BA_ "FlexKomComment" SG_ 1 KeyLine7_Appr "EIS state";
BA_ "FlexKomIsMotorola" SG_ 1 KeyLine7_Appr 1;
BA_ "FlexKomSID" SG_ 1 KeyLine7_Appr 117440590;
BA_ "FlexKomSigLaenge" SG_ 1 KeyLine7_Appr 64;
BA_ "FlexKomSigName" SG_ 1 KeyLine7_Appr "EIS_Stat";
BA_ "FlexKomSigStartPos" SG_ 1 KeyLine7_Appr 7;
BA_ "FlexKomSigStartValue" SG_ 1 KeyLine7_Appr "07C0FFFCFF0007FFh";
BA_ "GenSigCycleTime" SG_ 1 KeyLine7_Appr 100;
BA_ "GenSigSendType" SG_ 1 KeyLine7_Appr 5;
BA_ "FlexKomComment" SG_ 1 KeyLine8_Appr "EIS state";
BA_ "FlexKomIsMotorola" SG_ 1 KeyLine8_Appr 1;
BA_ "FlexKomSID" SG_ 1 KeyLine8_Appr 117440590;
BA_ "FlexKomSigLaenge" SG_ 1 KeyLine8_Appr 64;
BA_ "FlexKomSigName" SG_ 1 KeyLine8_Appr "EIS_Stat";
BA_ "FlexKomSigStartPos" SG_ 1 KeyLine8_Appr 7;
BA_ "FlexKomSigStartValue" SG_ 1 KeyLine8_Appr "07C0FFFCFF0007FFh";
BA_ "GenSigCycleTime" SG_ 1 KeyLine8_Appr 100;
BA_ "GenSigSendType" SG_ 1 KeyLine8_Appr 5;
BA_ "FlexKomComment" SG_ 1 CLkS_Lk_Stat3 "EIS state";
BA_ "FlexKomIsMotorola" SG_ 1 CLkS_Lk_Stat3 1;
BA_ "FlexKomSID" SG_ 1 CLkS_Lk_Stat3 117440590;
BA_ "FlexKomSigLaenge" SG_ 1 CLkS_Lk_Stat3 64;
BA_ "FlexKomSigName" SG_ 1 CLkS_Lk_Stat3 "EIS_Stat";
BA_ "FlexKomSigStartPos" SG_ 1 CLkS_Lk_Stat3 7;
BA_ "FlexKomSigStartValue" SG_ 1 CLkS_Lk_Stat3 "07C0FFFCFF0007FFh";
BA_ "GenSigCycleTime" SG_ 1 CLkS_Lk_Stat3 100;
BA_ "GenSigSNA" SG_ 1 CLkS_Lk_Stat3 "7";
BA_ "GenSigSendType" SG_ 1 CLkS_Lk_Stat3 5;
BA_ "GenSigStartValue" SG_ 1 CLkS_Lk_Stat3 7;
BA_ "GenSigTimeout_ORC" SG_ 1 CLkS_Lk_Stat3 1050;
BA_ "GenSigTimeout_SPC" SG_ 1 CLkS_Lk_Stat3 1050;
BA_ "FlexKomComment" SG_ 1 SPCR_AcustWarn_Rq_EIS "EIS state";
BA_ "FlexKomIsMotorola" SG_ 1 SPCR_AcustWarn_Rq_EIS 1;
BA_ "FlexKomSID" SG_ 1 SPCR_AcustWarn_Rq_EIS 117440590;
BA_ "FlexKomSigLaenge" SG_ 1 SPCR_AcustWarn_Rq_EIS 64;
BA_ "FlexKomSigName" SG_ 1 SPCR_AcustWarn_Rq_EIS "EIS_Stat";
BA_ "FlexKomSigStartPos" SG_ 1 SPCR_AcustWarn_Rq_EIS 7;
BA_ "FlexKomSigStartValue" SG_ 1 SPCR_AcustWarn_Rq_EIS "07C0FFFCFF0007FFh";
BA_ "GenSigCycleTime" SG_ 1 SPCR_AcustWarn_Rq_EIS 100;
BA_ "GenSigSendType" SG_ 1 SPCR_AcustWarn_Rq_EIS 5;
BA_ "FlexKomComment" SG_ 1 MC_EIS_A1 "EIS state";
BA_ "FlexKomIsMotorola" SG_ 1 MC_EIS_A1 1;
BA_ "FlexKomSID" SG_ 1 MC_EIS_A1 117440590;
BA_ "FlexKomSigLaenge" SG_ 1 MC_EIS_A1 64;
BA_ "FlexKomSigName" SG_ 1 MC_EIS_A1 "EIS_Stat";
BA_ "FlexKomSigStartPos" SG_ 1 MC_EIS_A1 7;
BA_ "FlexKomSigStartValue" SG_ 1 MC_EIS_A1 "07C0FFFCFF0007FFh";
BA_ "GenSigSendType" SG_ 1 MC_EIS_A1 10;
BA_ "GenSigTimeout_ESP_ABR" SG_ 1 MC_EIS_A1 1550;
BA_ "GenSigTimeout_RBTM_FL" SG_ 1 MC_EIS_A1 1050;
BA_ "GenSigTimeout_RBTM_FR" SG_ 1 MC_EIS_A1 1050;
BA_ "FlexKomComment" SG_ 1 CRC_EIS_A1 "EIS state";
BA_ "FlexKomIsMotorola" SG_ 1 CRC_EIS_A1 1;
BA_ "FlexKomSID" SG_ 1 CRC_EIS_A1 117440590;
BA_ "FlexKomSigLaenge" SG_ 1 CRC_EIS_A1 64;
BA_ "FlexKomSigName" SG_ 1 CRC_EIS_A1 "EIS_Stat";
BA_ "FlexKomSigStartPos" SG_ 1 CRC_EIS_A1 7;
BA_ "FlexKomSigStartValue" SG_ 1 CRC_EIS_A1 "07C0FFFCFF0007FFh";
BA_ "GenSigSendType" SG_ 1 CRC_EIS_A1 10;
BA_ "GenSigStartValue" SG_ 1 CRC_EIS_A1 255;
BA_ "GenSigTimeout_ESP_ABR" SG_ 1 CRC_EIS_A1 1550;
BA_ "GenSigTimeout_RBTM_FL" SG_ 1 CRC_EIS_A1 1050;
BA_ "GenSigTimeout_RBTM_FR" SG_ 1 CRC_EIS_A1 1050;
BA_ "FlexKomComment" SG_ 261 EngRPM "Engine response";
BA_ "FlexKomIsMotorola" SG_ 261 EngRPM 1;
BA_ "FlexKomSID" SG_ 261 EngRPM 117441536;
BA_ "FlexKomSigLaenge" SG_ 261 EngRPM 64;
BA_ "FlexKomSigName" SG_ 261 EngRPM "Eng_Rs3";
BA_ "FlexKomSigStartPos" SG_ 261 EngRPM 7;
BA_ "FlexKomSigStartValue" SG_ 261 EngRPM "3FFFFFFFFF3F07FFh";
BA_ "GenSigCycleTime" SG_ 261 EngRPM 20;
BA_ "GenSigSNA" SG_ 261 EngRPM "16383";
BA_ "GenSigSendType" SG_ 261 EngRPM 7;
BA_ "GenSigStartValue" SG_ 261 EngRPM 16383;
BA_ "GenSigTimeout_CGW" SG_ 261 EngRPM 210;
BA_ "GenSigTimeout_DRVU" SG_ 261 EngRPM 210;
BA_ "GenSigTimeout_ESP_ABR" SG_ 261 EngRPM 310;
BA_ "GenSigTimeout_IC" SG_ 261 EngRPM 210;
BA_ "FlexKomComment" SG_ 261 PreHt_Stat "Engine response";
BA_ "FlexKomIsMotorola" SG_ 261 PreHt_Stat 1;
BA_ "FlexKomSID" SG_ 261 PreHt_Stat 117441536;
BA_ "FlexKomSigLaenge" SG_ 261 PreHt_Stat 64;
BA_ "FlexKomSigName" SG_ 261 PreHt_Stat "Eng_Rs3";
BA_ "FlexKomSigStartPos" SG_ 261 PreHt_Stat 7;
BA_ "FlexKomSigStartValue" SG_ 261 PreHt_Stat "3FFFFFFFFF3F07FFh";
BA_ "GenSigCycleTime" SG_ 261 PreHt_Stat 20;
BA_ "GenSigSendType" SG_ 261 PreHt_Stat 7;
BA_ "GenSigTimeout_CGW" SG_ 261 PreHt_Stat 210;
BA_ "FlexKomComment" SG_ 261 KickDnSw_Psd "Engine response";
BA_ "FlexKomIsMotorola" SG_ 261 KickDnSw_Psd 1;
BA_ "FlexKomSID" SG_ 261 KickDnSw_Psd 117441536;
BA_ "FlexKomSigLaenge" SG_ 261 KickDnSw_Psd 64;
BA_ "FlexKomSigName" SG_ 261 KickDnSw_Psd "Eng_Rs3";
BA_ "FlexKomSigStartPos" SG_ 261 KickDnSw_Psd 7;
BA_ "FlexKomSigStartValue" SG_ 261 KickDnSw_Psd "3FFFFFFFFF3F07FFh";
BA_ "GenSigCycleTime" SG_ 261 KickDnSw_Psd 20;
BA_ "GenSigSendType" SG_ 261 KickDnSw_Psd 7;
BA_ "GenSigTimeout_CGW" SG_ 261 KickDnSw_Psd 210;
BA_ "GenSigTimeout_ESP_ABR" SG_ 261 KickDnSw_Psd 310;
BA_ "GenSigTimeout_MPC" SG_ 261 KickDnSw_Psd 210;
BA_ "GenSigTimeout_SPC" SG_ 261 KickDnSw_Psd 210;
BA_ "FlexKomComment" SG_ 261 EngTrqMaxCorrFctr "Engine response";
BA_ "FlexKomIsMotorola" SG_ 261 EngTrqMaxCorrFctr 1;
BA_ "FlexKomSID" SG_ 261 EngTrqMaxCorrFctr 117441536;
BA_ "FlexKomSigLaenge" SG_ 261 EngTrqMaxCorrFctr 64;
BA_ "FlexKomSigName" SG_ 261 EngTrqMaxCorrFctr "Eng_Rs3";
BA_ "FlexKomSigStartPos" SG_ 261 EngTrqMaxCorrFctr 7;
BA_ "FlexKomSigStartValue" SG_ 261 EngTrqMaxCorrFctr "3FFFFFFFFF3F07FFh";
BA_ "GenSigCycleTime" SG_ 261 EngTrqMaxCorrFctr 20;
BA_ "GenSigSNA" SG_ 261 EngTrqMaxCorrFctr "255";
BA_ "GenSigSendType" SG_ 261 EngTrqMaxCorrFctr 7;
BA_ "GenSigStartValue" SG_ 261 EngTrqMaxCorrFctr 255;
BA_ "GenSigTimeout_CGW" SG_ 261 EngTrqMaxCorrFctr 210;
BA_ "FlexKomComment" SG_ 261 AccelPdlPosn "Engine response";
BA_ "FlexKomIsMotorola" SG_ 261 AccelPdlPosn 1;
BA_ "FlexKomSID" SG_ 261 AccelPdlPosn 117441536;
BA_ "FlexKomSigLaenge" SG_ 261 AccelPdlPosn 64;
BA_ "FlexKomSigName" SG_ 261 AccelPdlPosn "Eng_Rs3";
BA_ "FlexKomSigStartPos" SG_ 261 AccelPdlPosn 7;
BA_ "FlexKomSigStartValue" SG_ 261 AccelPdlPosn "3FFFFFFFFF3F07FFh";
BA_ "GenSigCycleTime" SG_ 261 AccelPdlPosn 20;
BA_ "GenSigSNA" SG_ 261 AccelPdlPosn "255";
BA_ "GenSigSendType" SG_ 261 AccelPdlPosn 7;
BA_ "GenSigStartValue" SG_ 261 AccelPdlPosn 255;
BA_ "GenSigTimeout_CGW" SG_ 261 AccelPdlPosn 210;
BA_ "GenSigTimeout_ESP_ABR" SG_ 261 AccelPdlPosn 310;
BA_ "GenSigTimeout_IC" SG_ 261 AccelPdlPosn 210;
BA_ "FlexKomComment" SG_ 261 AccelPdlPosn_Raw "Engine response";
BA_ "FlexKomIsMotorola" SG_ 261 AccelPdlPosn_Raw 1;
BA_ "FlexKomSID" SG_ 261 AccelPdlPosn_Raw 117441536;
BA_ "FlexKomSigLaenge" SG_ 261 AccelPdlPosn_Raw 64;
BA_ "FlexKomSigName" SG_ 261 AccelPdlPosn_Raw "Eng_Rs3";
BA_ "FlexKomSigStartPos" SG_ 261 AccelPdlPosn_Raw 7;
BA_ "FlexKomSigStartValue" SG_ 261 AccelPdlPosn_Raw "3FFFFFFFFF3F07FFh";
BA_ "GenSigCycleTime" SG_ 261 AccelPdlPosn_Raw 20;
BA_ "GenSigSNA" SG_ 261 AccelPdlPosn_Raw "255";
BA_ "GenSigSendType" SG_ 261 AccelPdlPosn_Raw 7;
BA_ "GenSigStartValue" SG_ 261 AccelPdlPosn_Raw 255;
BA_ "GenSigTimeout_CGW" SG_ 261 AccelPdlPosn_Raw 210;
BA_ "GenSigTimeout_ESP_ABR" SG_ 261 AccelPdlPosn_Raw 310;
BA_ "GenSigTimeout_MPC" SG_ 261 AccelPdlPosn_Raw 210;
BA_ "FlexKomComment" SG_ 261 GenLoad "Engine response";
BA_ "FlexKomIsMotorola" SG_ 261 GenLoad 1;
BA_ "FlexKomSID" SG_ 261 GenLoad 117441536;
BA_ "FlexKomSigLaenge" SG_ 261 GenLoad 64;
BA_ "FlexKomSigName" SG_ 261 GenLoad "Eng_Rs3";
BA_ "FlexKomSigStartPos" SG_ 261 GenLoad 7;
BA_ "FlexKomSigStartValue" SG_ 261 GenLoad "3FFFFFFFFF3F07FFh";
BA_ "GenSigCycleTime" SG_ 261 GenLoad 20;
BA_ "GenSigSNA" SG_ 261 GenLoad "63";
BA_ "GenSigSendType" SG_ 261 GenLoad 7;
BA_ "GenSigStartValue" SG_ 261 GenLoad 63;
BA_ "GenSigTimeout_CGW" SG_ 261 GenLoad 210;
BA_ "FlexKomComment" SG_ 261 AddPwrCnsmr_On_Rq "Engine response";
BA_ "FlexKomIsMotorola" SG_ 261 AddPwrCnsmr_On_Rq 1;
BA_ "FlexKomSID" SG_ 261 AddPwrCnsmr_On_Rq 117441536;
BA_ "FlexKomSigLaenge" SG_ 261 AddPwrCnsmr_On_Rq 64;
BA_ "FlexKomSigName" SG_ 261 AddPwrCnsmr_On_Rq "Eng_Rs3";
BA_ "FlexKomSigStartPos" SG_ 261 AddPwrCnsmr_On_Rq 7;
BA_ "FlexKomSigStartValue" SG_ 261 AddPwrCnsmr_On_Rq "3FFFFFFFFF3F07FFh";
BA_ "GenSigCycleTime" SG_ 261 AddPwrCnsmr_On_Rq 20;
BA_ "GenSigSendType" SG_ 261 AddPwrCnsmr_On_Rq 7;
BA_ "GenSigTimeout_CGW" SG_ 261 AddPwrCnsmr_On_Rq 210;
BA_ "FlexKomComment" SG_ 261 Term61_Actv "Engine response";
BA_ "FlexKomIsMotorola" SG_ 261 Term61_Actv 1;
BA_ "FlexKomSID" SG_ 261 Term61_Actv 117441536;
BA_ "FlexKomSigLaenge" SG_ 261 Term61_Actv 64;
BA_ "FlexKomSigName" SG_ 261 Term61_Actv "Eng_Rs3";
BA_ "FlexKomSigStartPos" SG_ 261 Term61_Actv 7;
BA_ "FlexKomSigStartValue" SG_ 261 Term61_Actv "3FFFFFFFFF3F07FFh";
BA_ "GenSigCycleTime" SG_ 261 Term61_Actv 20;
BA_ "GenSigSendType" SG_ 261 Term61_Actv 7;
BA_ "GenSigTimeout_CGW" SG_ 261 Term61_Actv 210;
BA_ "GenSigTimeout_EIS" SG_ 261 Term61_Actv 210;
BA_ "GenSigTimeout_IC" SG_ 261 Term61_Actv 210;
BA_ "GenSigTimeout_SPC" SG_ 261 Term61_Actv 210;
BA_ "FlexKomComment" SG_ 261 EngRun_Stat "Engine response";
BA_ "FlexKomIsMotorola" SG_ 261 EngRun_Stat 1;
BA_ "FlexKomSID" SG_ 261 EngRun_Stat 117441536;
BA_ "FlexKomSigLaenge" SG_ 261 EngRun_Stat 64;
BA_ "FlexKomSigName" SG_ 261 EngRun_Stat "Eng_Rs3";
BA_ "FlexKomSigStartPos" SG_ 261 EngRun_Stat 7;
BA_ "FlexKomSigStartValue" SG_ 261 EngRun_Stat "3FFFFFFFFF3F07FFh";
BA_ "GenSigCycleTime" SG_ 261 EngRun_Stat 20;
BA_ "GenSigSNA" SG_ 261 EngRun_Stat "7";
BA_ "GenSigSendType" SG_ 261 EngRun_Stat 7;
BA_ "GenSigStartValue" SG_ 261 EngRun_Stat 7;
BA_ "GenSigTimeout_CGW" SG_ 261 EngRun_Stat 210;
BA_ "GenSigTimeout_DRVU" SG_ 261 EngRun_Stat 210;
BA_ "GenSigTimeout_EIS" SG_ 261 EngRun_Stat 210;
BA_ "GenSigTimeout_ESP_ABR" SG_ 261 EngRun_Stat 310;
BA_ "GenSigTimeout_IC" SG_ 261 EngRun_Stat 210;
BA_ "GenSigTimeout_MPC" SG_ 261 EngRun_Stat 210;
BA_ "GenSigTimeout_ORC" SG_ 261 EngRun_Stat 210;
BA_ "GenSigTimeout_PTS" SG_ 261 EngRun_Stat 210;
BA_ "GenSigTimeout_RBTM_FL" SG_ 261 EngRun_Stat 210;
BA_ "GenSigTimeout_RBTM_FR" SG_ 261 EngRun_Stat 210;
BA_ "GenSigTimeout_SCCM" SG_ 261 EngRun_Stat 210;
BA_ "GenSigTimeout_SPC" SG_ 261 EngRun_Stat 210;
BA_ "GenSigTimeout_TPM" SG_ 261 EngRun_Stat 210;
BA_ "FlexKomComment" SG_ 261 AccelPdlPosnSens_Flt "Engine response";
BA_ "FlexKomIsMotorola" SG_ 261 AccelPdlPosnSens_Flt 1;
BA_ "FlexKomSID" SG_ 261 AccelPdlPosnSens_Flt 117441536;
BA_ "FlexKomSigLaenge" SG_ 261 AccelPdlPosnSens_Flt 64;
BA_ "FlexKomSigName" SG_ 261 AccelPdlPosnSens_Flt "Eng_Rs3";
BA_ "FlexKomSigStartPos" SG_ 261 AccelPdlPosnSens_Flt 7;
BA_ "FlexKomSigStartValue" SG_ 261 AccelPdlPosnSens_Flt "3FFFFFFFFF3F07FFh";
BA_ "GenSigCycleTime" SG_ 261 AccelPdlPosnSens_Flt 20;
BA_ "GenSigSendType" SG_ 261 AccelPdlPosnSens_Flt 7;
BA_ "GenSigTimeout_CGW" SG_ 261 AccelPdlPosnSens_Flt 210;
BA_ "GenSigTimeout_ESP_ABR" SG_ 261 AccelPdlPosnSens_Flt 310;
BA_ "GenSigTimeout_MPC" SG_ 261 AccelPdlPosnSens_Flt 210;
BA_ "FlexKomComment" SG_ 261 MC_ENG_RS3 "Engine response";
BA_ "FlexKomIsMotorola" SG_ 261 MC_ENG_RS3 1;
BA_ "FlexKomSID" SG_ 261 MC_ENG_RS3 117441536;
BA_ "FlexKomSigLaenge" SG_ 261 MC_ENG_RS3 64;
BA_ "FlexKomSigName" SG_ 261 MC_ENG_RS3 "Eng_Rs3";
BA_ "FlexKomSigStartPos" SG_ 261 MC_ENG_RS3 7;
BA_ "FlexKomSigStartValue" SG_ 261 MC_ENG_RS3 "3FFFFFFFFF3F07FFh";
BA_ "GenSigCycleTime" SG_ 261 MC_ENG_RS3 20;
BA_ "GenSigSendType" SG_ 261 MC_ENG_RS3 7;
BA_ "GenSigTimeout_CGW" SG_ 261 MC_ENG_RS3 210;
BA_ "GenSigTimeout_ESP_ABR" SG_ 261 MC_ENG_RS3 310;
BA_ "GenSigTimeout_MPC" SG_ 261 MC_ENG_RS3 210;
BA_ "FlexKomComment" SG_ 261 CRC_ENG_RS3 "Engine response";
BA_ "FlexKomIsMotorola" SG_ 261 CRC_ENG_RS3 1;
BA_ "FlexKomSID" SG_ 261 CRC_ENG_RS3 117441536;
BA_ "FlexKomSigLaenge" SG_ 261 CRC_ENG_RS3 64;
BA_ "FlexKomSigName" SG_ 261 CRC_ENG_RS3 "Eng_Rs3";
BA_ "FlexKomSigStartPos" SG_ 261 CRC_ENG_RS3 7;
BA_ "FlexKomSigStartValue" SG_ 261 CRC_ENG_RS3 "3FFFFFFFFF3F07FFh";
BA_ "GenSigCycleTime" SG_ 261 CRC_ENG_RS3 20;
BA_ "GenSigSendType" SG_ 261 CRC_ENG_RS3 7;
BA_ "GenSigStartValue" SG_ 261 CRC_ENG_RS3 255;
BA_ "GenSigTimeout_CGW" SG_ 261 CRC_ENG_RS3 210;
BA_ "GenSigTimeout_ESP_ABR" SG_ 261 CRC_ENG_RS3 310;
BA_ "GenSigTimeout_MPC" SG_ 261 CRC_ENG_RS3 210;
BA_ "GenSigSNA" SG_ 1472 EPAS2_d074_eacCancelCode "15";
BA_ "GenSigSNA" SG_ 1426 EPAS3P_d081_eacCancelCode "15";
BA_ "LogSignal" SG_ 978 EPAS3P_appliedAngleOffset "onChange";
BA_ "LogSignal" SG_ 978 EPAS3P_calculatedAngleOffset "onChange";
BA_ "LogSignal" SG_ 978 EPAS3P_resyncStatus "onChange";
BA_ "LogSignal" SG_ 49 EPAS3P_state "onChange";
BA_ "GenSigSNA" SG_ 49 EPAS3P_powerMode "7";
BA_ "LogSignal" SG_ 49 EPAS3P_powerMode "onChange";
BA_ "LogSignal" SG_ 49 EPAS3P_role "onChange";
BA_ "GenSigSNA" SG_ 305 EPAS3P_steeringRackForce "1023";
BA_ "LogSignal" SG_ 305 EPAS3P_steeringRackForce "periodic POINT_NINE_SECONDS driveModeModelS";
BA_ "LogSignal" SG_ 305 EPAS3P_steeringFault "onChange";
BA_ "LogSignal" SG_ 305 EPAS3P_steeringReduced "onChange";
BA_ "GenSigSNA" SG_ 305 EPAS3P_torsionBarTorque "4095";
BA_ "LogSignal" SG_ 305 EPAS3P_torsionBarTorque "periodic ONE_SECOND driveModeModelS";
BA_ "GenSigSNA" SG_ 305 EPAS3P_eacErrorCode "15";
BA_ "LogSignal" SG_ 305 EPAS3P_eacErrorCode "onChange";
BA_ "LogSignal" SG_ 305 EPAS3P_internalSAS "periodic ONE_SECOND driveModeModelS";
BA_ "LogSignal" SG_ 305 EPAS3P_handsOnLevel "onChange";
BA_ "LogSignal" SG_ 305 EPAS3P_eacStatus "onChange";
BA_ "GenSigSNA" SG_ 1425 EPAS3S_d081_eacCancelCode "15";
BA_ "LogSignal" SG_ 1361 EPAS3S_bootIdData00 "onChange";
BA_ "LogSignal" SG_ 1361 EPAS3S_bootIdData01 "onChange";
BA_ "LogSignal" SG_ 81 EPAS3S_state "onChange";
BA_ "GenSigSNA" SG_ 81 EPAS3S_powerMode "7";
BA_ "LogSignal" SG_ 81 EPAS3S_powerMode "onChange";
BA_ "LogSignal" SG_ 81 EPAS3S_role "onChange";
BA_ "GenSigSNA" SG_ 1456 EPAS_d049_ESRACancelCode "15";
BA_ "GenSigStartValue" SG_ 977 EPAS_appliedAngleOffset 128;
BA_ "LogSignal" SG_ 977 EPAS_appliedAngleOffset "onChange";
BA_ "GenSigStartValue" SG_ 977 EPAS_calculatedAngleOffset 128;
BA_ "LogSignal" SG_ 977 EPAS_calculatedAngleOffset "onChange";
BA_ "LogSignal" SG_ 977 EPAS_resyncStatus "onChange";
BA_ "FieldType" SG_ 1328 EPAS_infoIndex "infoIndex";
BA_ "GenSigCycleTime" SG_ 1328 EPAS_infoIndex 1000;
BA_ "GenSigStartValue" SG_ 1328 EPAS_infoApplicationCRC 4294967295;
BA_ "GenSigSNA" SG_ 880 EPAS_steeringRackForce "1023";
BA_ "LogSignal" SG_ 880 EPAS_steeringRackForce "periodic POINT_NINE_SECONDS driveModeModelS";
BA_ "LogSignal" SG_ 880 EPAS_steeringFault "onChange";
BA_ "LogSignal" SG_ 880 EPAS_steeringReduced "onChange";
BA_ "GenSigSNA" SG_ 880 EPAS_torsionBarTorque "4095";
BA_ "LogSignal" SG_ 880 EPAS_torsionBarTorque "periodic ONE_SECOND driveModeModelS";
BA_ "GenSigSNA" SG_ 880 EPAS_eacErrorCode "15";
BA_ "LogSignal" SG_ 880 EPAS_eacErrorCode "onChange";
BA_ "LogSignal" SG_ 880 EPAS_internalSAS "periodic ONE_SECOND driveModeModelS";
BA_ "LogSignal" SG_ 880 EPAS_handsOnLevel "onChange";
BA_ "LogSignal" SG_ 880 EPAS_eacStatus "onChange";

BA_REL_ "GenSigTimeoutTime" BU_SG_REL_ SEC SG_ 360 GTW_counter4 1000;
BA_REL_ "GenSigTimeoutTime" BU_SG_REL_ SEC SG_ 360 GTW_nEngine 1000;
BA_REL_ "GenSigTimeoutTime" BU_SG_REL_ SEC SG_ 360 GTW_checksum4 1000;
VAL_ 390 DIS_soptState 7 "SOPT_SNA" 6 "SOPT_TEST_FAILED" 5 "SOPT_TEST_SKIPPED" 4 "SOPT_TEST_PASSED" 3 "SOPT_CURRENT_TEST" 2 "SOPT_ASC_TEST" 1 "SOPT_PSTG_BRING_UP" 0 "SOPT_INIT" ;
VAL_ 390 DIS_motorRPM -32768 "SNA" ;
VAL_ 518 DI_btcRequestActive_FrR 1 "ACTIVE" 0 "INACTIVE" ;
VAL_ 518 DI_btcRequestActive_ReL 1 "ACTIVE" 0 "INACTIVE" ;
VAL_ 518 DI_btcRequestActive_FrL 1 "ACTIVE" 0 "INACTIVE" ;
VAL_ 518 DI_btcRequestActive_ReR 1 "ACTIVE" 0 "INACTIVE" ;
VAL_ 328 DI_cruiseControlEngaged 3 "SNA" 2 "UNUSED" 1 "ENGAGED" 0 "NOT_ENGAGED" ;
VAL_ 328 DI_btcState 1 "ON" 0 "OFF" ;
VAL_ 328 DI_vehicleStandstillRqst 3 "SNA" 2 "empty" 1 "Standstill_requested" 0 "No_Standstill_request" ;
VAL_ 328 DI_ptcState 3 "SNA" 2 "ON" 1 "BACKUP" 0 "FAULTED" ;
VAL_ 328 DI_ptcActive 1 "ACTIVE" 0 "INACTIVE" ;
VAL_ 328 DI_tcLampFlashRequest 1 "ACTIVE" 0 "INACTIVE" ;
VAL_ 328 DI_brakeCommandType 7 "SNA" 3 "PARK" 2 "AEB" 1 "ACC" 0 "NO_REQUEST" ;
VAL_ 328 DI_regenTcActive 1 "ACTIVE" 0 "INACTIVE" ;
VAL_ 1270 DI_crsState 7 "DI_CRS_FAULT" 3 "DI_CRS_SLOWDOWN" 2 "DI_CRS_ACTIVE" 1 "DI_CRS_STANDBY" 0 "DI_CRS_UNAVAILABLE" ;
VAL_ 1270 DI_locState 7 "DI_LOC_FAULT" 6 "DI_LOC_ABORTING" 5 "DI_LOC_PAUSED" 4 "DI_LOC_STANDSTILL" 3 "DI_LOC_OVERRIDE" 2 "DI_LOC_ACTIVE" 1 "DI_LOC_STANDBY" 0 "DI_LOC_UNAVAILABLE" ;
VAL_ 872 DI_systemState 4 "DI_SYS_ENABLE" 3 "DI_SYS_ABORT" 2 "DI_SYS_FAULT" 1 "DI_SYS_STANDBY" 0 "DI_SYS_UNAVAILABLE" ;
VAL_ 872 DI_vehicleHoldState 7 "DI_VHLD_STATE_INIT" 6 "DI_VHLD_STATE_FAULT" 5 "DI_VHLD_STATE_PARK" 4 "DI_VHLD_STATE_BLEND_OUT" 3 "DI_VHLD_STATE_STANDSTILL" 2 "DI_VHLD_STATE_BLEND_IN" 1 "DI_VHLD_STATE_STANDBY" 0 "DI_VHLD_STATE_UNAVAILABLE" ;
VAL_ 872 DI_state 4 "DI_STATE_ENABLE" 3 "DI_STATE_ABORT" 2 "DI_STATE_FAULT" 1 "DI_STATE_STANDBY" 0 "DI_STATE_UNAVAILABLE" ;
VAL_ 872 DI_cruiseState 7 "CRS_STATE_PRE_CANCEL" 6 "CRS_STATE_PRE_FAULT" 5 "CRS_STATE_FAULT" 4 "CRS_STATE_OVERRIDE" 3 "CRS_STATE_STANDSTILL" 2 "CRS_STATE_ENABLED" 1 "CRS_STATE_STANDBY" 0 "CRS_STATE_UNAVAILABLE" ;
VAL_ 872 DI_analogSpeed 4095 "SNA" ;
VAL_ 872 DI_immobilizerState 6 "DI_IMM_STATE_FAULT" 5 "DI_IMM_STATE_RESET" 4 "DI_IMM_STATE_IDLE" 3 "DI_IMM_STATE_DISARMED" 2 "DI_IMM_STATE_AUTHENTICATING" 1 "DI_IMM_STATE_REQUEST" 0 "DI_IMM_STATE_INIT_SNA" ;
VAL_ 872 DI_speedUnits 1 "DI_SPEED_KPH" 0 "DI_SPEED_MPH" ;
VAL_ 872 DI_digitalSpeed 511 "SNA" ;
VAL_ 872 DI_aebState 7 "AEB_CAN_STATE_SNA" 4 "AEB_CAN_STATE_FAULT" 3 "AEB_CAN_STATE_STANDSTILL" 2 "AEB_CAN_STATE_ENABLED" 1 "AEB_CAN_STATE_STANDBY" 0 "AEB_CAN_STATE_UNAVAILABLE" ;
VAL_ 1016 DI_autoparkState 15 "DI_APC_SNA" 9 "DI_APC_SELFPARK_STARTED" 8 "DI_APC_UNPARK_COMPLETE" 7 "DI_APC_RESUMED" 6 "DI_APC_ABORTED" 5 "DI_APC_PAUSED" 4 "DI_APC_COMPLETE" 3 "DI_APC_ACTIVE" 2 "DI_APC_STARTED" 1 "DI_APC_STANDBY" 0 "DI_APC_UNAVAILABLE" ;
VAL_ 1016 DI_tractionControlMode 5 "TC_DYNO_MODE" 4 "TC_ROLLS_MODE" 3 "TC_DEV_MODE_2" 2 "TC_DEV_MODE_1" 1 "TC_SLIP_START" 0 "TC_NORMAL" ;
VAL_ 1016 DI_parkBrakeState 15 "DI_PBRK_SNA" 7 "DI_PBRK_RELEASING" 6 "DI_PBRK_PANIC_SKID" 5 "DI_PBRK_PANIC_EPB" 4 "DI_PBRK_FAULTED" 3 "DI_PBRK_APPLIED" 2 "DI_PBRK_REQUESTED" 1 "DI_PBRK_RELEASED" 0 "DI_PBRK_UNAVAILABLE" ;
VAL_ 1016 DI_pmmStatus 3 "DI_PMM_SNA" 1 "DI_PMM_ACTIVE" 0 "DI_PMM_INACTIVE" ;
VAL_ 1016 DI_vehicleHoldTelltaleOn 1 "TELLTALE_ON" 0 "TELLTALE_OFF" ;
VAL_ 1016 DI_onePedalDrivingState 8 "DI_OPD_NUM_STATES" 7 "DI_OPD_MOTOR_BLEND_IN" 6 "DI_OPD_NO_MOTOR" 5 "DI_OPD_MOTOR_BLEND_OUT_ACTIVE" 4 "DI_OPD_MOTOR_BLEND_OUT_PENDING" 3 "DI_OPD_NOMINAL" 2 "DI_OPD_STANDBY" 1 "DI_OPD_QUICK_BRAKE_RAMP" 0 "DI_OPD_UNAVAILABLE" ;
VAL_ 264 DI_torqueDriver -4096 "SNA" ;
VAL_ 264 DI_torqueMotor -4096 "SNA" ;
VAL_ 264 DI_soptState 7 "SOPT_SNA" 6 "SOPT_TEST_FAILED" 5 "SOPT_TEST_SKIPPED" 4 "SOPT_TEST_PASSED" 3 "SOPT_CURRENT_TEST" 2 "SOPT_ASC_TEST" 1 "SOPT_PSTG_BRING_UP" 0 "SOPT_INIT" ;
VAL_ 264 DI_motorRPM -32768 "SNA" ;
VAL_ 264 DI_pedalPos 255 "SNA" ;
VAL_ 280 DI_torqueEstimate -2048 "SNA" ;
VAL_ 280 DI_gear 7 "DI_GEAR_SNA" 4 "DI_GEAR_D" 3 "DI_GEAR_N" 2 "DI_GEAR_R" 1 "DI_GEAR_P" 0 "DI_GEAR_INVALID" ;
VAL_ 280 DI_brakePedal 1 "Applied" 0 "Not_applied" ;
VAL_ 280 DI_vehicleSpeed 4095 "SNA" ;
VAL_ 280 DI_gearRequest 7 "DI_GEAR_SNA" 4 "DI_GEAR_D" 3 "DI_GEAR_N" 2 "DI_GEAR_R" 1 "DI_GEAR_P" 0 "DI_GEAR_INVALID" ;
VAL_ 280 DI_torqueInterfaceFailure 1 "TORQUE_INTERFACE_FAILED" 0 "TORQUE_INTERFACE_NORMAL" ;
VAL_ 280 DI_brakePedalState 3 "SNA" 2 "INVALID" 1 "ON" 0 "OFF" ;
VAL_ 280 DI_epbParkRequest 1 "Park_requested" 0 "No_request" ;
VAL_ 280 DI_epbInterfaceReady 1 "EPB_INTERFACE_READY" 0 "EPB_INTERFACE_NOT_READY" ;
VAL_ 281 DI_vdcCommandTypeFrL 3 "VDC_SLIP_COMMAND" 2 "VDC_TORQUE_COMMAND" 1 "BTC_TORQUE_COMMAND" 0 "NO_TORQUE_COMMAND" ;
VAL_ 281 DI_vdcCommandTypeReL 3 "VDC_SLIP_COMMAND" 2 "VDC_TORQUE_COMMAND" 1 "BTC_TORQUE_COMMAND" 0 "NO_TORQUE_COMMAND" ;
VAL_ 281 DI_vdcCommandABSFrL 4 "MODIFY_BY_ABS_NO_GMA_NO_EBD" 3 "MODIFY_BY_ABS_NO_GMA" 2 "MODIFY_BY_ABS_ALL" 1 "FEED_THROUGH" 0 "NO_COMMAND" ;
VAL_ 281 DI_vdcCommandABSReL 4 "MODIFY_BY_ABS_NO_GMA_NO_EBD" 3 "MODIFY_BY_ABS_NO_GMA" 2 "MODIFY_BY_ABS_ALL" 1 "FEED_THROUGH" 0 "NO_COMMAND" ;
VAL_ 281 DI_brakeTorqueTarFrL 4095 "SNA" ;
VAL_ 281 DI_brakeTorqueTarReL 4095 "SNA" ;
VAL_ 281 DI_wheelSlipLimitFrL 255 "SNA" ;
VAL_ 281 DI_wheelSlipLimitReL 63 "SNA" ;
VAL_ 282 DI_vdcCommandTypeFrR 3 "VDC_SLIP_COMMAND" 2 "VDC_TORQUE_COMMAND" 1 "BTC_TORQUE_COMMAND" 0 "NO_TORQUE_COMMAND" ;
VAL_ 282 DI_vdcCommandTypeReR 3 "VDC_SLIP_COMMAND" 2 "VDC_TORQUE_COMMAND" 1 "BTC_TORQUE_COMMAND" 0 "NO_TORQUE_COMMAND" ;
VAL_ 282 DI_vdcCommandABSFrR 4 "MODIFY_BY_ABS_NO_GMA_NO_EBD" 3 "MODIFY_BY_ABS_NO_GMA" 2 "MODIFY_BY_ABS_ALL" 1 "FEED_THROUGH" 0 "NO_COMMAND" ;
VAL_ 282 DI_vdcCommandABSReR 4 "MODIFY_BY_ABS_NO_GMA_NO_EBD" 3 "MODIFY_BY_ABS_NO_GMA" 2 "MODIFY_BY_ABS_ALL" 1 "FEED_THROUGH" 0 "NO_COMMAND" ;
VAL_ 282 DI_brakeTorqueTarFrR 4095 "SNA" ;
VAL_ 282 DI_brakeTorqueTarReR 4095 "SNA" ;
VAL_ 282 DI_wheelSlipLimitFrR 255 "SNA" ;
VAL_ 282 DI_wheelSlipLimitReR 63 "SNA" ;
VAL_ 512 DPM_MdLmt_Rq 3 "SNA" 2 "EXT" 1 "LOCAL" 0 "SLEEP" ;
VAL_ 512 DPM_ExtMd_Enbl_Rq 3 "SNA" 2 "EXT" 1 "NO_EXT" 0 "NDEF0" ;
VAL_ 360 GTW_cruiseControlStatus 7 "default" 6 "CC_resume" 5 "CC_cancel" 4 "CC_overridden" 3 "CC_fault" 2 "CC_unavailable" 1 "CC_active" 0 "CC_inactive" ;
VAL_ 360 GTW_speedLimiterStatus 7 "default" 6 "Limiter_resume" 5 "Limiter_cancel" 4 "Limiter_overridden" 3 "Limiter_fault" 2 "Limiter_unavailable" 1 "Limiter_active" 0 "Limiter_inactive" ;
VAL_ 360 GTW_immobiliserLockOn 1 "immobiliser_locked_set" 0 "immobiliser_not_locked" ;
VAL_ 360 GTW_immobiliserOn 1 "immobiliser_set_on" 0 "immobiliser_not_locked" ;
VAL_ 360 GTW_engineStatus 7 "Engine_fault" 6 "Undefined" 5 "After_run_ign_off_ rpm_0" 4 "After_run_ign_off_rpm_gt_0" 3 "Running" 2 "Cranking" 1 "Not_running_ign_on" 0 "Not_running_ign_off" ;
VAL_ 360 GTW_ignitionResult 2 "Description for the value '0x2'" 1 "Not OK" 0 "OK" ;
VAL_ 527 EFUSE_airCompressorStatus 7 "EFUSE_AIR_COMPRESSOR_STATUS_SNA" 5 "EFUSE_AIR_COMPRESSOR_STATUS_RETRY_AVAILABLE" 4 "EFUSE_AIR_COMPRESSOR_STATUS_FAULT" 3 "EFUSE_AIR_COMPRESSOR_STATUS_TURNING_ON" 2 "EFUSE_AIR_COMPRESSOR_STATUS_TURNING_OFF" 1 "EFUSE_AIR_COMPRESSOR_STATUS_ON" 0 "EFUSE_AIR_COMPRESSOR_STATUS_OFF" ;
VAL_ 527 EFUSE_loadshedStatus 3 "EFUSE_LOADSHED_LEVEL_3" 2 "EFUSE_LOADSHED_LEVEL_2" 1 "EFUSE_LOADSHED_LEVEL_1" 0 "EFUSE_LOADSHED_LEVEL_NONE_SNA" ;
VAL_ 1 ISw_Stat 7 "SNA" 5 "IGN_START" 4 "IGN_ON" 2 "IGN_ACC" 1 "IGN_OFF" 0 "IGN_LOCK" ;
VAL_ 1 AutoDrLk_Rq_Src 3 "SNA" 2 "MENU" 1 "CLKS_INSD_SW" 0 "NDEF0" ;
VAL_ 1 AutoDrLk_Stat 3 "SNA" 2 "NDEF2" 1 "ON" 0 "OFF" ;
VAL_ 1 SPCR_Conf_EIS 3 "SNA" 2 "HOLD_AND_SBW" 1 "HOLD_NO_SBW" 0 "NOT_CONF" ;
VAL_ 1 CLkS_DL_Stat 3 "SNA" 2 "UNLOCK" 1 "LOCK" 0 "NDEF0" ;
VAL_ 1 CLkS_Gas_Dr_Stat 3 "SNA" 2 "UNLOCK" 1 "LOCK" 0 "NDEF0" ;
VAL_ 1 CLkS_Dr_FL_Stat 3 "SNA" 2 "UNLOCK" 1 "LOCK" 0 "NDEF0" ;
VAL_ 1 CLkS_Dr_FR_Stat 3 "SNA" 2 "UNLOCK" 1 "LOCK" 0 "NDEF0" ;
VAL_ 1 CLkS_Dr_RL_Stat 3 "SNA" 2 "UNLOCK" 1 "LOCK" 0 "NDEF0" ;
VAL_ 1 CLkS_Dr_RR_Stat 3 "SNA" 2 "UNLOCK" 1 "LOCK" 0 "NDEF0" ;
VAL_ 1 CLkS_Lk_Stat3 7 "SNA" 3 "SEL_UNLK" 2 "EXT_LK" 1 "INT_LK" 0 "UNLK" ;
VAL_ 261 EngRPM 16383 "SNA" ;
VAL_ 261 EngTrqMaxCorrFctr 255 "SNA" ;
VAL_ 261 AccelPdlPosn 255 "SNA" ;
VAL_ 261 AccelPdlPosn_Raw 255 "SNA" ;
VAL_ 261 GenLoad 63 "SNA" ;
VAL_ 261 EngRun_Stat 7 "SNA" 6 "NDEF6" 5 "LIMITED" 4 "UNLIMITED" 3 "IDLE_STBL" 2 "IDLE_UNSTBL" 1 "START" 0 "STOP" ;
VAL_ 1472 EPAS2_alertID 16464 "EPAS2_d080_abnormalShutdown" 16463 "EPAS2_d079_espPrivate1Mia" 16462 "EPAS2_d078_can2BusOff" 16461 "EPAS2_d077_pinionVelDiff" 16460 "EPAS2_d076_gtwOdoMia" 16459 "EPAS2_d075_espWsQf" 16458 "EPAS2_d074_eacCancelled" 16457 "EPAS2_d073_sasStat" 16456 "EPAS2_d072_sasCsError" 16455 "EPAS2_d071_sasCntError" 16454 "EPAS2_d070_sasMia" 16453 "EPAS2_d069_diCsError" 16452 "EPAS2_d068_diCntError" 16451 "EPAS2_d067_diMia" 16450 "EPAS2_d066_epbCsError" 16449 "EPAS2_d065_epbCntError" 16448 "EPAS2_d064_epbMia" 16447 "EPAS2_d063_gtwCsError" 16446 "EPAS2_d062_gtwCntError" 16445 "EPAS2_d061_gtwMia" 16444 "EPAS2_d060_espcQf" 16443 "EPAS2_d059_espcCsError" 16442 "EPAS2_d058_espcCntError" 16441 "EPAS2_d057_espcMia" 16440 "EPAS2_d056_espbQf" 16439 "EPAS2_d055_espbCsError" 16438 "EPAS2_d054_espbCntError" 16437 "EPAS2_d053_espbMia" 16436 "EPAS2_d052_espWsCsError" 16435 "EPAS2_d051_espWsCntError" 16434 "EPAS2_d050_espWsMia" 16433 "EPAS2_d049_dasCsError" 16432 "EPAS2_d048_dasCntError" 16431 "EPAS2_d047_dasMia" 16430 "EPAS2_d046_canBusOff" 16429 "EPAS2_d045_currentSensCal" 16428 "EPAS2_d044_trqSensCal" 16427 "EPAS2_d043_eepromError" 16426 "EPAS2_d042_overHeatProtect" 16425 "EPAS2_d041_tempSensError" 16424 "EPAS2_d040_offsetDiff" 16423 "EPAS2_d039_prechargeWl" 16422 "EPAS2_d038_ceOpen" 16421 "EPAS2_d037_precharge" 16420 "EPAS2_d036_posInc" 16419 "EPAS2_d035_batOv" 16418 "EPAS2_d034_batUv" 16417 "EPAS2_d033_subWatchdog" 16416 "EPAS2_d032_subSpiTime" 16415 "EPAS2_d031_offsetOver" 16414 "EPAS2_d030_batSigOpen" 16413 "EPAS2_d029_variantCheck" 16412 "EPAS2_d028_svcc52" 16411 "EPAS2_d027_svcc5" 16410 "EPAS2_d026_motOpen" 16409 "EPAS2_d025_motShort" 16408 "EPAS2_d024_gndFault" 16407 "EPAS2_d023_motOvc" 16406 "EPAS2_d022_motIdiff" 16405 "EPAS2_d021_strokeOv" 16404 "EPAS2_d020_posAbs" 16403 "EPAS2_d019_mainInterlock" 16402 "EPAS2_d018_compatibleId" 16401 "EPAS2_d017_sentSyncTime1" 16400 "EPAS2_d016_sentSyncTime2" 16399 "EPAS2_d015_sent1" 16398 "EPAS2_d014_sent2" 16397 "EPAS2_d013_sentDiff" 16396 "EPAS2_d012_sentTimeOut1" 16395 "EPAS2_d011_sentTimeOut2" 16394 "EPAS2_d010_sentCrcError1" 16393 "EPAS2_d009_sentCrcError2" 16392 "EPAS2_d008_programFlow" 16391 "EPAS2_d007_rlyShort" 16390 "EPAS2_d006_rlyOpen" 16389 "EPAS2_d005_subTx" 16388 "EPAS2_d004_gateDriverEn" 16387 "EPAS2_d003_runningReset" 16386 "EPAS2_d002_csvFail" 16385 "EPAS2_d001_csuFail" ;
VAL_ 1472 EPAS2_d074_eacCancelCode 15 "SNA" 14 "EAC_ERROR_EPB_INHIBIT" 13 "EAC_ERROR_PINION_VEL_DIFF" 12 "EAC_ERROR_LOW_ASSIST" 11 "EAC_ERROR_HIGH_TORSION_SAFETY" 10 "EAC_ERROR_HIGH_MMOT_SAFETY" 9 "EAC_ERROR_HIGH_ANGLE_RATE_SAFETY" 8 "EAC_ERROR_HIGH_ANGLE_SAFETY" 7 "EAC_ERROR_HIGH_ANGLE_RATE_REQ" 6 "EAC_ERROR_HIGH_ANGLE_REQ" 5 "EAR_ERROR_MAX_STEER_DELTA" 4 "EAC_ERROR_TMP_FAULT" 3 "EAC_ERROR_HANDS_ON" 2 "EAC_ERROR_MAX_SPEED" 1 "EAC_ERROR_MIN_SPEED" 0 "EAC_ERROR_IDLE" ;
VAL_ 912 EPAS2_d001_csuFail 3 "UNABLE_TO_TEST_DTC" 2 "FAILED_DTC" 1 "PASSED_DTC" 0 "NOT_TESTED_DTC" ;
VAL_ 912 EPAS2_d002_csvFail 3 "UNABLE_TO_TEST_DTC" 2 "FAILED_DTC" 1 "PASSED_DTC" 0 "NOT_TESTED_DTC" ;
VAL_ 912 EPAS2_d003_runningReset 3 "UNABLE_TO_TEST_DTC" 2 "FAILED_DTC" 1 "PASSED_DTC" 0 "NOT_TESTED_DTC" ;
VAL_ 912 EPAS2_d004_gateDriverEn 3 "UNABLE_TO_TEST_DTC" 2 "FAILED_DTC" 1 "PASSED_DTC" 0 "NOT_TESTED_DTC" ;
VAL_ 912 EPAS2_d005_subTx 3 "UNABLE_TO_TEST_DTC" 2 "FAILED_DTC" 1 "PASSED_DTC" 0 "NOT_TESTED_DTC" ;
VAL_ 912 EPAS2_d006_rlyOpen 3 "UNABLE_TO_TEST_DTC" 2 "FAILED_DTC" 1 "PASSED_DTC" 0 "NOT_TESTED_DTC" ;
VAL_ 912 EPAS2_d007_rlyShort 3 "UNABLE_TO_TEST_DTC" 2 "FAILED_DTC" 1 "PASSED_DTC" 0 "NOT_TESTED_DTC" ;
VAL_ 912 EPAS2_d008_programFlow 3 "UNABLE_TO_TEST_DTC" 2 "FAILED_DTC" 1 "PASSED_DTC" 0 "NOT_TESTED_DTC" ;
VAL_ 912 EPAS2_d009_sentCrcError2 3 "UNABLE_TO_TEST_DTC" 2 "FAILED_DTC" 1 "PASSED_DTC" 0 "NOT_TESTED_DTC" ;
VAL_ 912 EPAS2_d010_sentCrcError1 3 "UNABLE_TO_TEST_DTC" 2 "FAILED_DTC" 1 "PASSED_DTC" 0 "NOT_TESTED_DTC" ;
VAL_ 912 EPAS2_d011_sentTimeOut2 3 "UNABLE_TO_TEST_DTC" 2 "FAILED_DTC" 1 "PASSED_DTC" 0 "NOT_TESTED_DTC" ;
VAL_ 912 EPAS2_d012_sentTimeOut1 3 "UNABLE_TO_TEST_DTC" 2 "FAILED_DTC" 1 "PASSED_DTC" 0 "NOT_TESTED_DTC" ;
VAL_ 912 EPAS2_d013_sentDiff 3 "UNABLE_TO_TEST_DTC" 2 "FAILED_DTC" 1 "PASSED_DTC" 0 "NOT_TESTED_DTC" ;
VAL_ 912 EPAS2_d014_sent2 3 "UNABLE_TO_TEST_DTC" 2 "FAILED_DTC" 1 "PASSED_DTC" 0 "NOT_TESTED_DTC" ;
VAL_ 912 EPAS2_d015_sent1 3 "UNABLE_TO_TEST_DTC" 2 "FAILED_DTC" 1 "PASSED_DTC" 0 "NOT_TESTED_DTC" ;
VAL_ 912 EPAS2_d016_sentSyncTime2 3 "UNABLE_TO_TEST_DTC" 2 "FAILED_DTC" 1 "PASSED_DTC" 0 "NOT_TESTED_DTC" ;
VAL_ 912 EPAS2_d017_sentSyncTime1 3 "UNABLE_TO_TEST_DTC" 2 "FAILED_DTC" 1 "PASSED_DTC" 0 "NOT_TESTED_DTC" ;
VAL_ 912 EPAS2_d018_compatibleId 3 "UNABLE_TO_TEST_DTC" 2 "FAILED_DTC" 1 "PASSED_DTC" 0 "NOT_TESTED_DTC" ;
VAL_ 912 EPAS2_d019_mainInterlock 3 "UNABLE_TO_TEST_DTC" 2 "FAILED_DTC" 1 "PASSED_DTC" 0 "NOT_TESTED_DTC" ;
VAL_ 912 EPAS2_d020_posAbs 3 "UNABLE_TO_TEST_DTC" 2 "FAILED_DTC" 1 "PASSED_DTC" 0 "NOT_TESTED_DTC" ;
VAL_ 912 EPAS2_d021_strokeOv 3 "UNABLE_TO_TEST_DTC" 2 "FAILED_DTC" 1 "PASSED_DTC" 0 "NOT_TESTED_DTC" ;
VAL_ 912 EPAS2_d022_motIdiff 3 "UNABLE_TO_TEST_DTC" 2 "FAILED_DTC" 1 "PASSED_DTC" 0 "NOT_TESTED_DTC" ;
VAL_ 912 EPAS2_d023_motOvc 3 "UNABLE_TO_TEST_DTC" 2 "FAILED_DTC" 1 "PASSED_DTC" 0 "NOT_TESTED_DTC" ;
VAL_ 912 EPAS2_d024_gndFault 3 "UNABLE_TO_TEST_DTC" 2 "FAILED_DTC" 1 "PASSED_DTC" 0 "NOT_TESTED_DTC" ;
VAL_ 912 EPAS2_d025_motShort 3 "UNABLE_TO_TEST_DTC" 2 "FAILED_DTC" 1 "PASSED_DTC" 0 "NOT_TESTED_DTC" ;
VAL_ 912 EPAS2_d026_motOpen 3 "UNABLE_TO_TEST_DTC" 2 "FAILED_DTC" 1 "PASSED_DTC" 0 "NOT_TESTED_DTC" ;
VAL_ 912 EPAS2_d027_svcc5 3 "UNABLE_TO_TEST_DTC" 2 "FAILED_DTC" 1 "PASSED_DTC" 0 "NOT_TESTED_DTC" ;
VAL_ 912 EPAS2_d028_svcc52 3 "UNABLE_TO_TEST_DTC" 2 "FAILED_DTC" 1 "PASSED_DTC" 0 "NOT_TESTED_DTC" ;
VAL_ 912 EPAS2_d029_variantCheck 3 "UNABLE_TO_TEST_DTC" 2 "FAILED_DTC" 1 "PASSED_DTC" 0 "NOT_TESTED_DTC" ;
VAL_ 912 EPAS2_d030_batSigOpen 3 "UNABLE_TO_TEST_DTC" 2 "FAILED_DTC" 1 "PASSED_DTC" 0 "NOT_TESTED_DTC" ;
VAL_ 912 EPAS2_d031_offsetOver 3 "UNABLE_TO_TEST_DTC" 2 "FAILED_DTC" 1 "PASSED_DTC" 0 "NOT_TESTED_DTC" ;
VAL_ 912 EPAS2_d032_subSpiTime 3 "UNABLE_TO_TEST_DTC" 2 "FAILED_DTC" 1 "PASSED_DTC" 0 "NOT_TESTED_DTC" ;
VAL_ 912 EPAS2_d033_subWatchdog 3 "UNABLE_TO_TEST_DTC" 2 "FAILED_DTC" 1 "PASSED_DTC" 0 "NOT_TESTED_DTC" ;
VAL_ 912 EPAS2_d034_batUv 3 "UNABLE_TO_TEST_DTC" 2 "FAILED_DTC" 1 "PASSED_DTC" 0 "NOT_TESTED_DTC" ;
VAL_ 912 EPAS2_d035_batOv 3 "UNABLE_TO_TEST_DTC" 2 "FAILED_DTC" 1 "PASSED_DTC" 0 "NOT_TESTED_DTC" ;
VAL_ 912 EPAS2_d036_posInc 3 "UNABLE_TO_TEST_DTC" 2 "FAILED_DTC" 1 "PASSED_DTC" 0 "NOT_TESTED_DTC" ;
VAL_ 912 EPAS2_d037_precharge 3 "UNABLE_TO_TEST_DTC" 2 "FAILED_DTC" 1 "PASSED_DTC" 0 "NOT_TESTED_DTC" ;
VAL_ 912 EPAS2_d038_ceOpen 3 "UNABLE_TO_TEST_DTC" 2 "FAILED_DTC" 1 "PASSED_DTC" 0 "NOT_TESTED_DTC" ;
VAL_ 912 EPAS2_d039_prechargeWl 3 "UNABLE_TO_TEST_DTC" 2 "FAILED_DTC" 1 "PASSED_DTC" 0 "NOT_TESTED_DTC" ;
VAL_ 912 EPAS2_d040_offsetDiff 3 "UNABLE_TO_TEST_DTC" 2 "FAILED_DTC" 1 "PASSED_DTC" 0 "NOT_TESTED_DTC" ;
VAL_ 912 EPAS2_d041_tempSensError 3 "UNABLE_TO_TEST_DTC" 2 "FAILED_DTC" 1 "PASSED_DTC" 0 "NOT_TESTED_DTC" ;
VAL_ 912 EPAS2_d042_overHeatProtect 3 "UNABLE_TO_TEST_DTC" 2 "FAILED_DTC" 1 "PASSED_DTC" 0 "NOT_TESTED_DTC" ;
VAL_ 912 EPAS2_d043_eepromError 3 "UNABLE_TO_TEST_DTC" 2 "FAILED_DTC" 1 "PASSED_DTC" 0 "NOT_TESTED_DTC" ;
VAL_ 912 EPAS2_d044_trqSensCal 3 "UNABLE_TO_TEST_DTC" 2 "FAILED_DTC" 1 "PASSED_DTC" 0 "NOT_TESTED_DTC" ;
VAL_ 912 EPAS2_d045_currentSensCal 3 "UNABLE_TO_TEST_DTC" 2 "FAILED_DTC" 1 "PASSED_DTC" 0 "NOT_TESTED_DTC" ;
VAL_ 912 EPAS2_d046_canBusOff 3 "UNABLE_TO_TEST_DTC" 2 "FAILED_DTC" 1 "PASSED_DTC" 0 "NOT_TESTED_DTC" ;
VAL_ 912 EPAS2_d047_dasMia 3 "UNABLE_TO_TEST_DTC" 2 "FAILED_DTC" 1 "PASSED_DTC" 0 "NOT_TESTED_DTC" ;
VAL_ 912 EPAS2_d048_dasCntError 3 "UNABLE_TO_TEST_DTC" 2 "FAILED_DTC" 1 "PASSED_DTC" 0 "NOT_TESTED_DTC" ;
VAL_ 912 EPAS2_d049_dasCsError 3 "UNABLE_TO_TEST_DTC" 2 "FAILED_DTC" 1 "PASSED_DTC" 0 "NOT_TESTED_DTC" ;
VAL_ 912 EPAS2_d050_espWsMia 3 "UNABLE_TO_TEST_DTC" 2 "FAILED_DTC" 1 "PASSED_DTC" 0 "NOT_TESTED_DTC" ;
VAL_ 912 EPAS2_d051_espWsCntError 3 "UNABLE_TO_TEST_DTC" 2 "FAILED_DTC" 1 "PASSED_DTC" 0 "NOT_TESTED_DTC" ;
VAL_ 912 EPAS2_d052_espWsCsError 3 "UNABLE_TO_TEST_DTC" 2 "FAILED_DTC" 1 "PASSED_DTC" 0 "NOT_TESTED_DTC" ;
VAL_ 912 EPAS2_d053_espbMia 3 "UNABLE_TO_TEST_DTC" 2 "FAILED_DTC" 1 "PASSED_DTC" 0 "NOT_TESTED_DTC" ;
VAL_ 912 EPAS2_d054_espbCntError 3 "UNABLE_TO_TEST_DTC" 2 "FAILED_DTC" 1 "PASSED_DTC" 0 "NOT_TESTED_DTC" ;
VAL_ 912 EPAS2_d055_espbCsError 3 "UNABLE_TO_TEST_DTC" 2 "FAILED_DTC" 1 "PASSED_DTC" 0 "NOT_TESTED_DTC" ;
VAL_ 912 EPAS2_d056_espbQf 3 "UNABLE_TO_TEST_DTC" 2 "FAILED_DTC" 1 "PASSED_DTC" 0 "NOT_TESTED_DTC" ;
VAL_ 912 EPAS2_d057_espcMia 3 "UNABLE_TO_TEST_DTC" 2 "FAILED_DTC" 1 "PASSED_DTC" 0 "NOT_TESTED_DTC" ;
VAL_ 912 EPAS2_d058_espcCntError 3 "UNABLE_TO_TEST_DTC" 2 "FAILED_DTC" 1 "PASSED_DTC" 0 "NOT_TESTED_DTC" ;
VAL_ 912 EPAS2_d059_espcCsError 3 "UNABLE_TO_TEST_DTC" 2 "FAILED_DTC" 1 "PASSED_DTC" 0 "NOT_TESTED_DTC" ;
VAL_ 912 EPAS2_d060_espcQf 3 "UNABLE_TO_TEST_DTC" 2 "FAILED_DTC" 1 "PASSED_DTC" 0 "NOT_TESTED_DTC" ;
VAL_ 912 EPAS2_d061_gtwMia 3 "UNABLE_TO_TEST_DTC" 2 "FAILED_DTC" 1 "PASSED_DTC" 0 "NOT_TESTED_DTC" ;
VAL_ 912 EPAS2_d062_gtwCntError 3 "UNABLE_TO_TEST_DTC" 2 "FAILED_DTC" 1 "PASSED_DTC" 0 "NOT_TESTED_DTC" ;
VAL_ 912 EPAS2_d063_gtwCsError 3 "UNABLE_TO_TEST_DTC" 2 "FAILED_DTC" 1 "PASSED_DTC" 0 "NOT_TESTED_DTC" ;
VAL_ 912 EPAS2_d064_epbMia 3 "UNABLE_TO_TEST_DTC" 2 "FAILED_DTC" 1 "PASSED_DTC" 0 "NOT_TESTED_DTC" ;
VAL_ 912 EPAS2_d065_epbCntError 3 "UNABLE_TO_TEST_DTC" 2 "FAILED_DTC" 1 "PASSED_DTC" 0 "NOT_TESTED_DTC" ;
VAL_ 912 EPAS2_d066_epbCsError 3 "UNABLE_TO_TEST_DTC" 2 "FAILED_DTC" 1 "PASSED_DTC" 0 "NOT_TESTED_DTC" ;
VAL_ 912 EPAS2_d067_diMia 3 "UNABLE_TO_TEST_DTC" 2 "FAILED_DTC" 1 "PASSED_DTC" 0 "NOT_TESTED_DTC" ;
VAL_ 912 EPAS2_d068_diCntError 3 "UNABLE_TO_TEST_DTC" 2 "FAILED_DTC" 1 "PASSED_DTC" 0 "NOT_TESTED_DTC" ;
VAL_ 912 EPAS2_d069_diCsError 3 "UNABLE_TO_TEST_DTC" 2 "FAILED_DTC" 1 "PASSED_DTC" 0 "NOT_TESTED_DTC" ;
VAL_ 912 EPAS2_d070_sasMia 3 "UNABLE_TO_TEST_DTC" 2 "FAILED_DTC" 1 "PASSED_DTC" 0 "NOT_TESTED_DTC" ;
VAL_ 912 EPAS2_d071_sasCntError 3 "UNABLE_TO_TEST_DTC" 2 "FAILED_DTC" 1 "PASSED_DTC" 0 "NOT_TESTED_DTC" ;
VAL_ 912 EPAS2_d072_sasCsError 3 "UNABLE_TO_TEST_DTC" 2 "FAILED_DTC" 1 "PASSED_DTC" 0 "NOT_TESTED_DTC" ;
VAL_ 912 EPAS2_d073_sasStat 3 "UNABLE_TO_TEST_DTC" 2 "FAILED_DTC" 1 "PASSED_DTC" 0 "NOT_TESTED_DTC" ;
VAL_ 912 EPAS2_d074_eacCancelled 3 "UNABLE_TO_TEST_DTC" 2 "FAILED_DTC" 1 "PASSED_DTC" 0 "NOT_TESTED_DTC" ;
VAL_ 912 EPAS2_d075_espWsQf 3 "UNABLE_TO_TEST_DTC" 2 "FAILED_DTC" 1 "PASSED_DTC" 0 "NOT_TESTED_DTC" ;
VAL_ 912 EPAS2_d076_gtwOdoMia 3 "UNABLE_TO_TEST_DTC" 2 "FAILED_DTC" 1 "PASSED_DTC" 0 "NOT_TESTED_DTC" ;
VAL_ 912 EPAS2_d077_pinionVelDiff 3 "UNABLE_TO_TEST_DTC" 2 "FAILED_DTC" 1 "PASSED_DTC" 0 "NOT_TESTED_DTC" ;
VAL_ 912 EPAS2_d078_can2BusOff 3 "UNABLE_TO_TEST_DTC" 2 "FAILED_DTC" 1 "PASSED_DTC" 0 "NOT_TESTED_DTC" ;
VAL_ 912 EPAS2_d079_espPrivate1Mia 3 "UNABLE_TO_TEST_DTC" 2 "FAILED_DTC" 1 "PASSED_DTC" 0 "NOT_TESTED_DTC" ;
VAL_ 912 EPAS2_d080_abnormalShutdown 3 "UNABLE_TO_TEST_DTC" 2 "FAILED_DTC" 1 "PASSED_DTC" 0 "NOT_TESTED_DTC" ;
VAL_ 1426 EPAS3P_alertID 16516 "EPAS3P_d132_phaseFeedbackError" 16515 "EPAS3P_d131_sasOffsetNotCal" 16514 "EPAS3P_d130_combEcu1StatFail" 16513 "EPAS3P_d129_trqSensTrimOutRange" 16512 "EPAS3P_d128_tempSensStuckInRange" 16511 "EPAS3P_d127_combEcu2StatFail" 16510 "EPAS3P_d126_olpActive" 16509 "EPAS3P_d125_pvtEcuStatCrcError" 16508 "EPAS3P_d124_pvtEcuStatCntError" 16507 "EPAS3P_d123_pvtEcuStatMia" 16506 "EPAS3P_d122_privateBusOff" 16505 "EPAS3P_d121_espPriv1Qf" 16504 "EPAS3P_d120_espPriv1CsError" 16503 "EPAS3P_d119_espPriv1CntError" 16502 "EPAS3P_d118_espPriv1Mia" 16501 "EPAS3P_d117_ecuStatCrcError" 16500 "EPAS3P_d116_ecuStatCntError" 16499 "EPAS3P_d115_ecuStatMia" 16498 "EPAS3P_d114_gtwOdoMia" 16497 "EPAS3P_d113_espWsQf" 16496 "EPAS3P_d112_sasStat" 16495 "EPAS3P_d111_sasCsError" 16494 "EPAS3P_d110_sasCntError" 16493 "EPAS3P_d109_sasMia" 16492 "EPAS3P_d108_diCsError" 16491 "EPAS3P_d107_diCntError" 16490 "EPAS3P_d106_diMia" 16489 "EPAS3P_d105_apsCsError" 16488 "EPAS3P_d104_apsCntError" 16487 "EPAS3P_d103_apsMia" 16486 "EPAS3P_d102_gtwCsError" 16485 "EPAS3P_d101_gtwCntError" 16484 "EPAS3P_d100_gtwMia" 16483 "EPAS3P_d099_espcQf" 16482 "EPAS3P_d098_espcCsError" 16481 "EPAS3P_d097_espcCntError" 16480 "EPAS3P_d096_espcMia" 16479 "EPAS3P_d095_espbQf" 16478 "EPAS3P_d094_espbCsError" 16477 "EPAS3P_d093_espbCntError" 16476 "EPAS3P_d092_espbMia" 16475 "EPAS3P_d091_espWsCsError" 16474 "EPAS3P_d090_espWsCntError" 16473 "EPAS3P_d089_espWsMia" 16472 "EPAS3P_d088_dasCsError" 16471 "EPAS3P_d087_dasCntError" 16470 "EPAS3P_d086_dasMia" 16469 "EPAS3P_d085_chassisBusOff" 16468 "EPAS3P_d084_eacCancelled" 16467 "EPAS3P_d083_crcMismatch" 16466 "EPAS3P_d082_polarityCalError" 16465 "EPAS3P_d081_coggCompError" 16464 "EPAS3P_d080_ecuInitArbError" 16463 "EPAS3P_d079_backupCurrentPlaus" 16462 "EPAS3P_d078_phaseDisconnectError" 16461 "EPAS3P_d077_highSideFetError" 16460 "EPAS3P_d076_tempSensOutofRange" 16459 "EPAS3P_d075_fspPwrCut" 16458 "EPAS3P_d074_overHeatProtect" 16457 "EPAS3P_d073_motParEstError" 16456 "EPAS3P_d072_motFeedFwdError" 16455 "EPAS3P_d071_vehSpdCorrError" 16454 "EPAS3P_d070_hodCorrError" 16453 "EPAS3P_d069_eacCorrError" 16452 "EPAS3P_d068_hystCorrError" 16451 "EPAS3P_d067_yawDampCorrError" 16450 "EPAS3P_d066_returnCorrError" 16449 "EPAS3P_d065_trqTarCorrError" 16448 "EPAS3P_d064_phaseCompCorrError" 16447 "EPAS3P_d063_dampCorrError" 16446 "EPAS3P_d062_assistCorrError" 16445 "EPAS3P_d061_bridgeUv" 16444 "EPAS3P_d060_battBridgeDiff" 16443 "EPAS3P_d059_battOvReduced" 16442 "EPAS3P_d058_battOv" 16441 "EPAS3P_d057_battUvReduced" 16440 "EPAS3P_d056_battUv" 16439 "EPAS3P_d055_floatPointError" 16438 "EPAS3P_d054_memoryProtectError" 16437 "EPAS3P_d053_extWatchdogError" 16436 "EPAS3P_d052_intWatchdogError" 16435 "EPAS3P_d051_mcuSupError" 16434 "EPAS3P_d050_mcuSmuError" 16433 "EPAS3P_d049_piCtrlError" 16432 "EPAS3P_d048_motPosCalError" 16431 "EPAS3P_d047_motPosCorrError" 16430 "EPAS3P_d046_motPos2tempError" 16429 "EPAS3P_d045_motPos2LogicError" 16428 "EPAS3P_d044_motPos2MagnetMia" 16427 "EPAS3P_d043_motPos2Uv" 16426 "EPAS3P_d042_motPos2ParityError" 16425 "EPAS3P_d041_motPos1tempError" 16424 "EPAS3P_d040_motPos1LogicError" 16423 "EPAS3P_d039_motPos1MagnetMia" 16422 "EPAS3P_d038_motPos1Uv" 16421 "EPAS3P_d037_motPos1ParityError" 16420 "EPAS3P_d036_vbbSupplyOv" 16419 "EPAS3P_d035_vbbSupplyUv" 16418 "EPAS3P_d034_vRegError" 16417 "EPAS3P_d033_vRegOutputOv" 16416 "EPAS3P_d032_vRegOutputUv" 16415 "EPAS3P_d031_abnormalShutdown" 16414 "EPAS3P_d030_phaseWbootUv" 16413 "EPAS3P_d029_phaseVbootUv" 16412 "EPAS3P_d028_phaseUbootUv" 16411 "EPAS3P_d027_phaseWlowOv" 16410 "EPAS3P_d026_phaseWhighOv" 16409 "EPAS3P_d025_phaseVlowOv" 16408 "EPAS3P_d024_phaseVhighOv" 16407 "EPAS3P_d023_phaseUlowOv" 16406 "EPAS3P_d022_phaseUhighOv" 16405 "EPAS3P_d021_phaseWlowUv" 16404 "EPAS3P_d020_phaseWhighUv" 16403 "EPAS3P_d019_phaseVlowUv" 16402 "EPAS3P_d018_phaseVhighUv" 16401 "EPAS3P_d017_phaseUlowUv" 16400 "EPAS3P_d016_phaseUhighUv" 16399 "EPAS3P_d015_gateDriveEeprom" 16398 "EPAS3P_d014_gateDriveTxError" 16397 "EPAS3P_d013_gateDriveError" 16396 "EPAS3P_d012_currentSensCalError" 16395 "EPAS3P_d011_currentSensError" 16394 "EPAS3P_d010_trqSensCalError" 16393 "EPAS3P_d009_sentDiff" 16392 "EPAS3P_d008_trqSens2Eeprom" 16391 "EPAS3P_d007_trqSens2Supply" 16390 "EPAS3P_d006_sent2Error" 16389 "EPAS3P_d005_sent2Mia" 16388 "EPAS3P_d004_trqSens1Eeprom" 16387 "EPAS3P_d003_trqSens1Supply" 16386 "EPAS3P_d002_sent1Error" 16385 "EPAS3P_d001_sent1Mia" ;
VAL_ 1426 EPAS3P_d081_eacCancelCode 15 "SNA" 13 "EAC_ERROR_EPB_INHIBIT" 12 "EAC_ERROR_LOW_ASSIST" 11 "EAC_ERROR_HIGH_TORSION_SAFETY" 10 "EAC_ERROR_HIGH_MMOT_SAFETY" 9 "EAC_ERROR_HIGH_ANGLE_RATE_SAFETY" 8 "EAC_ERROR_HIGH_ANGLE_SAFETY" 7 "EAC_ERROR_HIGH_ANGLE_RATE_REQ" 6 "EAC_ERROR_HIGH_ANGLE_REQ" 5 "EAR_ERROR_MAX_STEER_DELTA" 4 "EAC_ERROR_TMP_FAULT" 3 "EAC_ERROR_HANDS_ON" 2 "EAC_ERROR_MAX_SPEED" 1 "EAC_ERROR_MIN_SPEED" 0 "EAC_ERROR_IDLE" ;
VAL_ 978 EPAS3P_resyncStatus 1 "RESYNC_COMPLETE" 0 "RESYNC_PENDING" ;
VAL_ 914 EPAS3P_d001_sent1Mia 3 "UNABLE_TO_TEST_DTC" 2 "FAILED_DTC" 1 "PASSED_DTC" 0 "NOT_TESTED_DTC" ;
VAL_ 914 EPAS3P_d002_sent1Error 3 "UNABLE_TO_TEST_DTC" 2 "FAILED_DTC" 1 "PASSED_DTC" 0 "NOT_TESTED_DTC" ;
VAL_ 914 EPAS3P_d003_trqSens1Supply 3 "UNABLE_TO_TEST_DTC" 2 "FAILED_DTC" 1 "PASSED_DTC" 0 "NOT_TESTED_DTC" ;
VAL_ 914 EPAS3P_d004_trqSens1Eeprom 3 "UNABLE_TO_TEST_DTC" 2 "FAILED_DTC" 1 "PASSED_DTC" 0 "NOT_TESTED_DTC" ;
VAL_ 914 EPAS3P_d005_sent2Mia 3 "UNABLE_TO_TEST_DTC" 2 "FAILED_DTC" 1 "PASSED_DTC" 0 "NOT_TESTED_DTC" ;
VAL_ 914 EPAS3P_d006_sent2Error 3 "UNABLE_TO_TEST_DTC" 2 "FAILED_DTC" 1 "PASSED_DTC" 0 "NOT_TESTED_DTC" ;
VAL_ 914 EPAS3P_d007_trqSens2Supply 3 "UNABLE_TO_TEST_DTC" 2 "FAILED_DTC" 1 "PASSED_DTC" 0 "NOT_TESTED_DTC" ;
VAL_ 914 EPAS3P_d008_trqSens2Eeprom 3 "UNABLE_TO_TEST_DTC" 2 "FAILED_DTC" 1 "PASSED_DTC" 0 "NOT_TESTED_DTC" ;
VAL_ 914 EPAS3P_d009_sentDiff 3 "UNABLE_TO_TEST_DTC" 2 "FAILED_DTC" 1 "PASSED_DTC" 0 "NOT_TESTED_DTC" ;
VAL_ 914 EPAS3P_d010_trqSensCalError 3 "UNABLE_TO_TEST_DTC" 2 "FAILED_DTC" 1 "PASSED_DTC" 0 "NOT_TESTED_DTC" ;
VAL_ 914 EPAS3P_d011_currentSensError 3 "UNABLE_TO_TEST_DTC" 2 "FAILED_DTC" 1 "PASSED_DTC" 0 "NOT_TESTED_DTC" ;
VAL_ 914 EPAS3P_d012_currentSensCalError 3 "UNABLE_TO_TEST_DTC" 2 "FAILED_DTC" 1 "PASSED_DTC" 0 "NOT_TESTED_DTC" ;
VAL_ 914 EPAS3P_d013_gateDriveError 3 "UNABLE_TO_TEST_DTC" 2 "FAILED_DTC" 1 "PASSED_DTC" 0 "NOT_TESTED_DTC" ;
VAL_ 914 EPAS3P_d014_gateDriveTxError 3 "UNABLE_TO_TEST_DTC" 2 "FAILED_DTC" 1 "PASSED_DTC" 0 "NOT_TESTED_DTC" ;
VAL_ 914 EPAS3P_d015_gateDriveEeprom 3 "UNABLE_TO_TEST_DTC" 2 "FAILED_DTC" 1 "PASSED_DTC" 0 "NOT_TESTED_DTC" ;
VAL_ 914 EPAS3P_d016_phaseUhighUv 3 "UNABLE_TO_TEST_DTC" 2 "FAILED_DTC" 1 "PASSED_DTC" 0 "NOT_TESTED_DTC" ;
VAL_ 914 EPAS3P_d017_phaseUlowUv 3 "UNABLE_TO_TEST_DTC" 2 "FAILED_DTC" 1 "PASSED_DTC" 0 "NOT_TESTED_DTC" ;
VAL_ 914 EPAS3P_d018_phaseVhighUv 3 "UNABLE_TO_TEST_DTC" 2 "FAILED_DTC" 1 "PASSED_DTC" 0 "NOT_TESTED_DTC" ;
VAL_ 914 EPAS3P_d019_phaseVlowUv 3 "UNABLE_TO_TEST_DTC" 2 "FAILED_DTC" 1 "PASSED_DTC" 0 "NOT_TESTED_DTC" ;
VAL_ 914 EPAS3P_d020_phaseWhighUv 3 "UNABLE_TO_TEST_DTC" 2 "FAILED_DTC" 1 "PASSED_DTC" 0 "NOT_TESTED_DTC" ;
VAL_ 914 EPAS3P_d021_phaseWlowUv 3 "UNABLE_TO_TEST_DTC" 2 "FAILED_DTC" 1 "PASSED_DTC" 0 "NOT_TESTED_DTC" ;
VAL_ 914 EPAS3P_d022_phaseUhighOv 3 "UNABLE_TO_TEST_DTC" 2 "FAILED_DTC" 1 "PASSED_DTC" 0 "NOT_TESTED_DTC" ;
VAL_ 914 EPAS3P_d023_phaseUlowOv 3 "UNABLE_TO_TEST_DTC" 2 "FAILED_DTC" 1 "PASSED_DTC" 0 "NOT_TESTED_DTC" ;
VAL_ 914 EPAS3P_d024_phaseVhighOv 3 "UNABLE_TO_TEST_DTC" 2 "FAILED_DTC" 1 "PASSED_DTC" 0 "NOT_TESTED_DTC" ;
VAL_ 914 EPAS3P_d025_phaseVlowOv 3 "UNABLE_TO_TEST_DTC" 2 "FAILED_DTC" 1 "PASSED_DTC" 0 "NOT_TESTED_DTC" ;
VAL_ 914 EPAS3P_d026_phaseWhighOv 3 "UNABLE_TO_TEST_DTC" 2 "FAILED_DTC" 1 "PASSED_DTC" 0 "NOT_TESTED_DTC" ;
VAL_ 914 EPAS3P_d027_phaseWlowOv 3 "UNABLE_TO_TEST_DTC" 2 "FAILED_DTC" 1 "PASSED_DTC" 0 "NOT_TESTED_DTC" ;
VAL_ 914 EPAS3P_d028_phaseUbootUv 3 "UNABLE_TO_TEST_DTC" 2 "FAILED_DTC" 1 "PASSED_DTC" 0 "NOT_TESTED_DTC" ;
VAL_ 914 EPAS3P_d029_phaseVbootUv 3 "UNABLE_TO_TEST_DTC" 2 "FAILED_DTC" 1 "PASSED_DTC" 0 "NOT_TESTED_DTC" ;
VAL_ 914 EPAS3P_d030_phaseWbootUv 3 "UNABLE_TO_TEST_DTC" 2 "FAILED_DTC" 1 "PASSED_DTC" 0 "NOT_TESTED_DTC" ;
VAL_ 914 EPAS3P_d031_abnormalShutdown 3 "UNABLE_TO_TEST_DTC" 2 "FAILED_DTC" 1 "PASSED_DTC" 0 "NOT_TESTED_DTC" ;
VAL_ 914 EPAS3P_d032_vRegOutputUv 3 "UNABLE_TO_TEST_DTC" 2 "FAILED_DTC" 1 "PASSED_DTC" 0 "NOT_TESTED_DTC" ;
VAL_ 914 EPAS3P_d033_vRegOutputOv 3 "UNABLE_TO_TEST_DTC" 2 "FAILED_DTC" 1 "PASSED_DTC" 0 "NOT_TESTED_DTC" ;
VAL_ 914 EPAS3P_d034_vRegError 3 "UNABLE_TO_TEST_DTC" 2 "FAILED_DTC" 1 "PASSED_DTC" 0 "NOT_TESTED_DTC" ;
VAL_ 914 EPAS3P_d035_vbbSupplyUv 3 "UNABLE_TO_TEST_DTC" 2 "FAILED_DTC" 1 "PASSED_DTC" 0 "NOT_TESTED_DTC" ;
VAL_ 914 EPAS3P_d036_vbbSupplyOv 3 "UNABLE_TO_TEST_DTC" 2 "FAILED_DTC" 1 "PASSED_DTC" 0 "NOT_TESTED_DTC" ;
VAL_ 914 EPAS3P_d037_motPos1ParityError 3 "UNABLE_TO_TEST_DTC" 2 "FAILED_DTC" 1 "PASSED_DTC" 0 "NOT_TESTED_DTC" ;
VAL_ 914 EPAS3P_d038_motPos1Uv 3 "UNABLE_TO_TEST_DTC" 2 "FAILED_DTC" 1 "PASSED_DTC" 0 "NOT_TESTED_DTC" ;
VAL_ 914 EPAS3P_d039_motPos1MagnetMia 3 "UNABLE_TO_TEST_DTC" 2 "FAILED_DTC" 1 "PASSED_DTC" 0 "NOT_TESTED_DTC" ;
VAL_ 914 EPAS3P_d040_motPos1LogicError 3 "UNABLE_TO_TEST_DTC" 2 "FAILED_DTC" 1 "PASSED_DTC" 0 "NOT_TESTED_DTC" ;
VAL_ 914 EPAS3P_d041_motPos1tempError 3 "UNABLE_TO_TEST_DTC" 2 "FAILED_DTC" 1 "PASSED_DTC" 0 "NOT_TESTED_DTC" ;
VAL_ 914 EPAS3P_d042_motPos2ParityError 3 "UNABLE_TO_TEST_DTC" 2 "FAILED_DTC" 1 "PASSED_DTC" 0 "NOT_TESTED_DTC" ;
VAL_ 914 EPAS3P_d043_motPos2Uv 3 "UNABLE_TO_TEST_DTC" 2 "FAILED_DTC" 1 "PASSED_DTC" 0 "NOT_TESTED_DTC" ;
VAL_ 914 EPAS3P_d044_motPos2MagnetMia 3 "UNABLE_TO_TEST_DTC" 2 "FAILED_DTC" 1 "PASSED_DTC" 0 "NOT_TESTED_DTC" ;
VAL_ 914 EPAS3P_d045_motPos2LogicError 3 "UNABLE_TO_TEST_DTC" 2 "FAILED_DTC" 1 "PASSED_DTC" 0 "NOT_TESTED_DTC" ;
VAL_ 914 EPAS3P_d046_motPos2tempError 3 "UNABLE_TO_TEST_DTC" 2 "FAILED_DTC" 1 "PASSED_DTC" 0 "NOT_TESTED_DTC" ;
VAL_ 914 EPAS3P_d047_motPosCorrError 3 "UNABLE_TO_TEST_DTC" 2 "FAILED_DTC" 1 "PASSED_DTC" 0 "NOT_TESTED_DTC" ;
VAL_ 914 EPAS3P_d048_motPosCalError 3 "UNABLE_TO_TEST_DTC" 2 "FAILED_DTC" 1 "PASSED_DTC" 0 "NOT_TESTED_DTC" ;
VAL_ 914 EPAS3P_d049_piCtrlError 3 "UNABLE_TO_TEST_DTC" 2 "FAILED_DTC" 1 "PASSED_DTC" 0 "NOT_TESTED_DTC" ;
VAL_ 914 EPAS3P_d050_mcuSmuError 3 "UNABLE_TO_TEST_DTC" 2 "FAILED_DTC" 1 "PASSED_DTC" 0 "NOT_TESTED_DTC" ;
VAL_ 914 EPAS3P_d051_mcuSupError 3 "UNABLE_TO_TEST_DTC" 2 "FAILED_DTC" 1 "PASSED_DTC" 0 "NOT_TESTED_DTC" ;
VAL_ 914 EPAS3P_d052_intWatchdogError 3 "UNABLE_TO_TEST_DTC" 2 "FAILED_DTC" 1 "PASSED_DTC" 0 "NOT_TESTED_DTC" ;
VAL_ 914 EPAS3P_d053_extWatchdogError 3 "UNABLE_TO_TEST_DTC" 2 "FAILED_DTC" 1 "PASSED_DTC" 0 "NOT_TESTED_DTC" ;
VAL_ 914 EPAS3P_d054_memoryProtectError 3 "UNABLE_TO_TEST_DTC" 2 "FAILED_DTC" 1 "PASSED_DTC" 0 "NOT_TESTED_DTC" ;
VAL_ 914 EPAS3P_d055_floatPointError 3 "UNABLE_TO_TEST_DTC" 2 "FAILED_DTC" 1 "PASSED_DTC" 0 "NOT_TESTED_DTC" ;
VAL_ 914 EPAS3P_d056_battUv 3 "UNABLE_TO_TEST_DTC" 2 "FAILED_DTC" 1 "PASSED_DTC" 0 "NOT_TESTED_DTC" ;
VAL_ 914 EPAS3P_d057_battUvReduced 3 "UNABLE_TO_TEST_DTC" 2 "FAILED_DTC" 1 "PASSED_DTC" 0 "NOT_TESTED_DTC" ;
VAL_ 914 EPAS3P_d058_battOv 3 "UNABLE_TO_TEST_DTC" 2 "FAILED_DTC" 1 "PASSED_DTC" 0 "NOT_TESTED_DTC" ;
VAL_ 914 EPAS3P_d059_battOvReduced 3 "UNABLE_TO_TEST_DTC" 2 "FAILED_DTC" 1 "PASSED_DTC" 0 "NOT_TESTED_DTC" ;
VAL_ 914 EPAS3P_d060_battBridgeDiff 3 "UNABLE_TO_TEST_DTC" 2 "FAILED_DTC" 1 "PASSED_DTC" 0 "NOT_TESTED_DTC" ;
VAL_ 914 EPAS3P_d061_bridgeUv 3 "UNABLE_TO_TEST_DTC" 2 "FAILED_DTC" 1 "PASSED_DTC" 0 "NOT_TESTED_DTC" ;
VAL_ 914 EPAS3P_d062_assistCorrError 3 "UNABLE_TO_TEST_DTC" 2 "FAILED_DTC" 1 "PASSED_DTC" 0 "NOT_TESTED_DTC" ;
VAL_ 914 EPAS3P_d063_dampCorrError 3 "UNABLE_TO_TEST_DTC" 2 "FAILED_DTC" 1 "PASSED_DTC" 0 "NOT_TESTED_DTC" ;
VAL_ 914 EPAS3P_d064_phaseCompCorrError 3 "UNABLE_TO_TEST_DTC" 2 "FAILED_DTC" 1 "PASSED_DTC" 0 "NOT_TESTED_DTC" ;
VAL_ 914 EPAS3P_d065_trqTarCorrError 3 "UNABLE_TO_TEST_DTC" 2 "FAILED_DTC" 1 "PASSED_DTC" 0 "NOT_TESTED_DTC" ;
VAL_ 914 EPAS3P_d066_returnCorrError 3 "UNABLE_TO_TEST_DTC" 2 "FAILED_DTC" 1 "PASSED_DTC" 0 "NOT_TESTED_DTC" ;
VAL_ 914 EPAS3P_d067_yawDampCorrError 3 "UNABLE_TO_TEST_DTC" 2 "FAILED_DTC" 1 "PASSED_DTC" 0 "NOT_TESTED_DTC" ;
VAL_ 914 EPAS3P_d068_hystCorrError 3 "UNABLE_TO_TEST_DTC" 2 "FAILED_DTC" 1 "PASSED_DTC" 0 "NOT_TESTED_DTC" ;
VAL_ 914 EPAS3P_d069_eacCorrError 3 "UNABLE_TO_TEST_DTC" 2 "FAILED_DTC" 1 "PASSED_DTC" 0 "NOT_TESTED_DTC" ;
VAL_ 914 EPAS3P_d070_hodCorrError 3 "UNABLE_TO_TEST_DTC" 2 "FAILED_DTC" 1 "PASSED_DTC" 0 "NOT_TESTED_DTC" ;
VAL_ 914 EPAS3P_d071_vehSpdCorrError 3 "UNABLE_TO_TEST_DTC" 2 "FAILED_DTC" 1 "PASSED_DTC" 0 "NOT_TESTED_DTC" ;
VAL_ 914 EPAS3P_d072_motFeedFwdError 3 "UNABLE_TO_TEST_DTC" 2 "FAILED_DTC" 1 "PASSED_DTC" 0 "NOT_TESTED_DTC" ;
VAL_ 914 EPAS3P_d073_motParEstError 3 "UNABLE_TO_TEST_DTC" 2 "FAILED_DTC" 1 "PASSED_DTC" 0 "NOT_TESTED_DTC" ;
VAL_ 914 EPAS3P_d074_overHeatProtect 3 "UNABLE_TO_TEST_DTC" 2 "FAILED_DTC" 1 "PASSED_DTC" 0 "NOT_TESTED_DTC" ;
VAL_ 914 EPAS3P_d075_fspPwrCut 3 "UNABLE_TO_TEST_DTC" 2 "FAILED_DTC" 1 "PASSED_DTC" 0 "NOT_TESTED_DTC" ;
VAL_ 914 EPAS3P_d076_tempSensOutofRange 3 "UNABLE_TO_TEST_DTC" 2 "FAILED_DTC" 1 "PASSED_DTC" 0 "NOT_TESTED_DTC" ;
VAL_ 914 EPAS3P_d077_highSideFetError 3 "UNABLE_TO_TEST_DTC" 2 "FAILED_DTC" 1 "PASSED_DTC" 0 "NOT_TESTED_DTC" ;
VAL_ 914 EPAS3P_d078_phaseDisconnectError 3 "UNABLE_TO_TEST_DTC" 2 "FAILED_DTC" 1 "PASSED_DTC" 0 "NOT_TESTED_DTC" ;
VAL_ 914 EPAS3P_d079_backupCurrentPlaus 3 "UNABLE_TO_TEST_DTC" 2 "FAILED_DTC" 1 "PASSED_DTC" 0 "NOT_TESTED_DTC" ;
VAL_ 914 EPAS3P_d080_ecuInitArbError 3 "UNABLE_TO_TEST_DTC" 2 "FAILED_DTC" 1 "PASSED_DTC" 0 "NOT_TESTED_DTC" ;
VAL_ 914 EPAS3P_d081_coggCompError 3 "UNABLE_TO_TEST_DTC" 2 "FAILED_DTC" 1 "PASSED_DTC" 0 "NOT_TESTED_DTC" ;
VAL_ 914 EPAS3P_d082_polarityCalError 3 "UNABLE_TO_TEST_DTC" 2 "FAILED_DTC" 1 "PASSED_DTC" 0 "NOT_TESTED_DTC" ;
VAL_ 914 EPAS3P_d083_crcMismatch 3 "UNABLE_TO_TEST_DTC" 2 "FAILED_DTC" 1 "PASSED_DTC" 0 "NOT_TESTED_DTC" ;
VAL_ 914 EPAS3P_d084_eacCancelled 3 "UNABLE_TO_TEST_DTC" 2 "FAILED_DTC" 1 "PASSED_DTC" 0 "NOT_TESTED_DTC" ;
VAL_ 914 EPAS3P_d085_canBusOff 3 "UNABLE_TO_TEST_DTC" 2 "FAILED_DTC" 1 "PASSED_DTC" 0 "NOT_TESTED_DTC" ;
VAL_ 914 EPAS3P_d086_dasMia 3 "UNABLE_TO_TEST_DTC" 2 "FAILED_DTC" 1 "PASSED_DTC" 0 "NOT_TESTED_DTC" ;
VAL_ 914 EPAS3P_d087_dasCntError 3 "UNABLE_TO_TEST_DTC" 2 "FAILED_DTC" 1 "PASSED_DTC" 0 "NOT_TESTED_DTC" ;
VAL_ 914 EPAS3P_d088_dasCsError 3 "UNABLE_TO_TEST_DTC" 2 "FAILED_DTC" 1 "PASSED_DTC" 0 "NOT_TESTED_DTC" ;
VAL_ 914 EPAS3P_d089_espWsMia 3 "UNABLE_TO_TEST_DTC" 2 "FAILED_DTC" 1 "PASSED_DTC" 0 "NOT_TESTED_DTC" ;
VAL_ 914 EPAS3P_d090_espWsCntError 3 "UNABLE_TO_TEST_DTC" 2 "FAILED_DTC" 1 "PASSED_DTC" 0 "NOT_TESTED_DTC" ;
VAL_ 914 EPAS3P_d091_espWsCsError 3 "UNABLE_TO_TEST_DTC" 2 "FAILED_DTC" 1 "PASSED_DTC" 0 "NOT_TESTED_DTC" ;
VAL_ 914 EPAS3P_d092_espbMia 3 "UNABLE_TO_TEST_DTC" 2 "FAILED_DTC" 1 "PASSED_DTC" 0 "NOT_TESTED_DTC" ;
VAL_ 914 EPAS3P_d093_espbCntError 3 "UNABLE_TO_TEST_DTC" 2 "FAILED_DTC" 1 "PASSED_DTC" 0 "NOT_TESTED_DTC" ;
VAL_ 914 EPAS3P_d094_espbCsError 3 "UNABLE_TO_TEST_DTC" 2 "FAILED_DTC" 1 "PASSED_DTC" 0 "NOT_TESTED_DTC" ;
VAL_ 914 EPAS3P_d095_espbQf 3 "UNABLE_TO_TEST_DTC" 2 "FAILED_DTC" 1 "PASSED_DTC" 0 "NOT_TESTED_DTC" ;
VAL_ 914 EPAS3P_d096_espcMia 3 "UNABLE_TO_TEST_DTC" 2 "FAILED_DTC" 1 "PASSED_DTC" 0 "NOT_TESTED_DTC" ;
VAL_ 914 EPAS3P_d097_espcCntError 3 "UNABLE_TO_TEST_DTC" 2 "FAILED_DTC" 1 "PASSED_DTC" 0 "NOT_TESTED_DTC" ;
VAL_ 914 EPAS3P_d098_espcCsError 3 "UNABLE_TO_TEST_DTC" 2 "FAILED_DTC" 1 "PASSED_DTC" 0 "NOT_TESTED_DTC" ;
VAL_ 914 EPAS3P_d099_espcQf 3 "UNABLE_TO_TEST_DTC" 2 "FAILED_DTC" 1 "PASSED_DTC" 0 "NOT_TESTED_DTC" ;
VAL_ 914 EPAS3P_d100_gtwMia 3 "UNABLE_TO_TEST_DTC" 2 "FAILED_DTC" 1 "PASSED_DTC" 0 "NOT_TESTED_DTC" ;
VAL_ 914 EPAS3P_d101_gtwCntError 3 "UNABLE_TO_TEST_DTC" 2 "FAILED_DTC" 1 "PASSED_DTC" 0 "NOT_TESTED_DTC" ;
VAL_ 914 EPAS3P_d102_gtwCsError 3 "UNABLE_TO_TEST_DTC" 2 "FAILED_DTC" 1 "PASSED_DTC" 0 "NOT_TESTED_DTC" ;
VAL_ 914 EPAS3P_d103_apsMia 3 "UNABLE_TO_TEST_DTC" 2 "FAILED_DTC" 1 "PASSED_DTC" 0 "NOT_TESTED_DTC" ;
VAL_ 914 EPAS3P_d104_apsCntError 3 "UNABLE_TO_TEST_DTC" 2 "FAILED_DTC" 1 "PASSED_DTC" 0 "NOT_TESTED_DTC" ;
VAL_ 914 EPAS3P_d105_apsCsError 3 "UNABLE_TO_TEST_DTC" 2 "FAILED_DTC" 1 "PASSED_DTC" 0 "NOT_TESTED_DTC" ;
VAL_ 914 EPAS3P_d106_diMia 3 "UNABLE_TO_TEST_DTC" 2 "FAILED_DTC" 1 "PASSED_DTC" 0 "NOT_TESTED_DTC" ;
VAL_ 914 EPAS3P_d107_diCntError 3 "UNABLE_TO_TEST_DTC" 2 "FAILED_DTC" 1 "PASSED_DTC" 0 "NOT_TESTED_DTC" ;
VAL_ 914 EPAS3P_d108_diCsError 3 "UNABLE_TO_TEST_DTC" 2 "FAILED_DTC" 1 "PASSED_DTC" 0 "NOT_TESTED_DTC" ;
VAL_ 914 EPAS3P_d109_sasMia 3 "UNABLE_TO_TEST_DTC" 2 "FAILED_DTC" 1 "PASSED_DTC" 0 "NOT_TESTED_DTC" ;
VAL_ 914 EPAS3P_d110_sasCntError 3 "UNABLE_TO_TEST_DTC" 2 "FAILED_DTC" 1 "PASSED_DTC" 0 "NOT_TESTED_DTC" ;
VAL_ 914 EPAS3P_d111_sasCsError 3 "UNABLE_TO_TEST_DTC" 2 "FAILED_DTC" 1 "PASSED_DTC" 0 "NOT_TESTED_DTC" ;
VAL_ 914 EPAS3P_d112_sasStatError 3 "UNABLE_TO_TEST_DTC" 2 "FAILED_DTC" 1 "PASSED_DTC" 0 "NOT_TESTED_DTC" ;
VAL_ 914 EPAS3P_d113_espWsQf 3 "UNABLE_TO_TEST_DTC" 2 "FAILED_DTC" 1 "PASSED_DTC" 0 "NOT_TESTED_DTC" ;
VAL_ 914 EPAS3P_d114_gtwOdoMia 3 "UNABLE_TO_TEST_DTC" 2 "FAILED_DTC" 1 "PASSED_DTC" 0 "NOT_TESTED_DTC" ;
VAL_ 914 EPAS3P_d115_ecuStatMia 3 "UNABLE_TO_TEST_DTC" 2 "FAILED_DTC" 1 "PASSED_DTC" 0 "NOT_TESTED_DTC" ;
VAL_ 914 EPAS3P_d116_ecuStatCntError 3 "UNABLE_TO_TEST_DTC" 2 "FAILED_DTC" 1 "PASSED_DTC" 0 "NOT_TESTED_DTC" ;
VAL_ 914 EPAS3P_d117_ecuStatCrcError 3 "UNABLE_TO_TEST_DTC" 2 "FAILED_DTC" 1 "PASSED_DTC" 0 "NOT_TESTED_DTC" ;
VAL_ 914 EPAS3P_d118_espPriv1Mia 3 "UNABLE_TO_TEST_DTC" 2 "FAILED_DTC" 1 "PASSED_DTC" 0 "NOT_TESTED_DTC" ;
VAL_ 914 EPAS3P_d119_espPriv1CntError 3 "UNABLE_TO_TEST_DTC" 2 "FAILED_DTC" 1 "PASSED_DTC" 0 "NOT_TESTED_DTC" ;
VAL_ 914 EPAS3P_d120_espPriv1CsError 3 "UNABLE_TO_TEST_DTC" 2 "FAILED_DTC" 1 "PASSED_DTC" 0 "NOT_TESTED_DTC" ;
VAL_ 914 EPAS3P_d121_espPriv1Qf 3 "UNABLE_TO_TEST_DTC" 2 "FAILED_DTC" 1 "PASSED_DTC" 0 "NOT_TESTED_DTC" ;
VAL_ 914 EPAS3P_d122_privateBusOff 3 "UNABLE_TO_TEST_DTC" 2 "FAILED_DTC" 1 "PASSED_DTC" 0 "NOT_TESTED_DTC" ;
VAL_ 914 EPAS3P_d123_pvtEcuStatMia 3 "UNABLE_TO_TEST_DTC" 2 "FAILED_DTC" 1 "PASSED_DTC" 0 "NOT_TESTED_DTC" ;
VAL_ 914 EPAS3P_d124_pvtEcuStatCntError 3 "UNABLE_TO_TEST_DTC" 2 "FAILED_DTC" 1 "PASSED_DTC" 0 "NOT_TESTED_DTC" ;
VAL_ 914 EPAS3P_d125_pvtEcuStatCrcError 3 "UNABLE_TO_TEST_DTC" 2 "FAILED_DTC" 1 "PASSED_DTC" 0 "NOT_TESTED_DTC" ;
VAL_ 914 EPAS3P_d126_olpActive 3 "UNABLE_TO_TEST_DTC" 2 "FAILED_DTC" 1 "PASSED_DTC" 0 "NOT_TESTED_DTC" ;
VAL_ 914 EPAS3P_d127_combEcu2StatFail 3 "UNABLE_TO_TEST_DTC" 2 "FAILED_DTC" 1 "PASSED_DTC" 0 "NOT_TESTED_DTC" ;
VAL_ 914 EPAS3P_d128_tempSensStuckInRange 3 "UNABLE_TO_TEST_DTC" 2 "FAILED_DTC" 1 "PASSED_DTC" 0 "NOT_TESTED_DTC" ;
VAL_ 914 EPAS3P_d129_trqSensTrimOutRange 3 "UNABLE_TO_TEST_DTC" 2 "FAILED_DTC" 1 "PASSED_DTC" 0 "NOT_TESTED_DTC" ;
VAL_ 914 EPAS3P_d130_combEcu1StatFail 3 "UNABLE_TO_TEST_DTC" 2 "FAILED_DTC" 1 "PASSED_DTC" 0 "NOT_TESTED_DTC" ;
VAL_ 914 EPAS3P_d131_sasOffsetNotCal 3 "UNABLE_TO_TEST_DTC" 2 "FAILED_DTC" 1 "PASSED_DTC" 0 "NOT_TESTED_DTC" ;
VAL_ 914 EPAS3P_d132_phaseFeedbackError 3 "UNABLE_TO_TEST_DTC" 2 "FAILED_DTC" 1 "PASSED_DTC" 0 "NOT_TESTED_DTC" ;
VAL_ 49 EPAS3P_state 15 "INVALID" 8 "EAC_STANDBY" 7 "EAC_ACTIVE" 6 "ASSIST_STANDBY" 5 "ASSIST_ACTIVE" 4 "PASSIVE_FAULTED" 3 "PASSIVE" 2 "INIT_COMPLETE" 1 "INIT_PHASECUT_TEST" 0 "INIT_ARBITRATION" ;
VAL_ 49 EPAS3P_powerMode 7 "SNA" 6 "POWERING_DOWN" 5 "LIMP_3" 4 "LIMP_2" 3 "LIMP_1" 2 "DRIVE_ON" 1 "EMERGENCY_ON" 0 "DRIVE_OFF" ;
VAL_ 49 EPAS3P_role 2 "RESERVED" 1 "SLAVE" 0 "MASTER" ;
VAL_ 305 EPAS3P_steeringRackForce 1023 "SNA" 1022 "NOT_IN_SPEC" ;
VAL_ 305 EPAS3P_steeringFault 1 "FAULT" 0 "NO_FAULT" ;
VAL_ 305 EPAS3P_steeringReduced 1 "REDUCED_ASSIST" 0 "NORMAL_ASSIST" ;
VAL_ 305 EPAS3P_currentTuneMode 7 "UNAVAILABLE" 6 "RWD_SPORT" 5 "RWD_STANDARD" 4 "RWD_COMFORT" 3 "DM_SPORT" 2 "DM_STANDARD" 1 "DM_COMFORT" 0 "FAIL_SAFE_DEFAULT" ;
VAL_ 305 EPAS3P_torsionBarTorque 4095 "SNA" 4094 "UNDEFINABLE_DATA" ;
VAL_ 305 EPAS3P_eacErrorCode 15 "SNA" 14 "EAC_EXTERNAL_MONITOR_INHIBIT" 13 "EAC_ERROR_PINION_VEL_DIFF" 12 "EAC_ERROR_LOW_ASSIST" 11 "EAC_ERROR_HIGH_TORSION_SAFETY" 10 "EAC_ERROR_HIGH_MMOT_SAFETY" 9 "EAC_ERROR_HIGH_ANGLE_RATE_SAFETY" 8 "EAC_ERROR_HIGH_ANGLE_SAFETY" 7 "EAC_ERROR_HIGH_ANGLE_RATE_REQ" 6 "EAC_ERROR_HIGH_ANGLE_REQ" 5 "EAR_ERROR_MAX_STEER_DELTA" 4 "EAC_ERROR_TMP_FAULT" 3 "EAC_ERROR_HANDS_ON" 2 "EAC_ERROR_MAX_SPEED" 1 "EAC_ERROR_MIN_SPEED" 0 "EAC_ERROR_IDLE" ;
VAL_ 305 EPAS3P_handsOnLevel 3 "LEVEL_3" 2 "LEVEL_2" 1 "LEVEL_1" 0 "LEVEL_0" ;
VAL_ 305 EPAS3P_eacStatus 7 "EAC_ELK_ACTIVE" 6 "EAC_ELK_AVAILABLE" 5 "EAC_LKA_ACTIVE" 4 "EAC_LKA_ELK_AVAILABLE" 3 "EAC_FAULT" 2 "EAC_ACTIVE" 1 "EAC_AVAILABLE" 0 "EAC_INHIBITED" ;
VAL_ 1425 EPAS3S_alertID 16515 "EPAS3S_d132_phaseFeedbackError" 16514 "EPAS3S_d130_combEcu1StatFail" 16513 "EPAS3S_d129_trqSensTrimOutRange" 16512 "EPAS3S_d128_tempSensStuckInRange" 16511 "EPAS3S_d127_combEcu2StatFail" 16510 "EPAS3S_d126_olpActive" 16509 "EPAS3S_d125_pvtEcuStatCrcError" 16508 "EPAS3S_d124_pvtEcuStatCntError" 16507 "EPAS3S_d123_pvtEcuStatMia" 16506 "EPAS3S_d122_privateBusOff" 16505 "EPAS3S_d121_espPriv1Qf" 16504 "EPAS3S_d120_espPriv1CsError" 16503 "EPAS3S_d119_espPriv1CntError" 16502 "EPAS3S_d118_espPriv1Mia" 16501 "EPAS3S_d117_ecuStatCrcError" 16500 "EPAS3S_d116_ecuStatCntError" 16499 "EPAS3S_d115_ecuStatMia" 16498 "EPAS3S_d114_gtwOdoMia" 16497 "EPAS3S_d113_espWsQf" 16496 "EPAS3S_d112_sasStat" 16495 "EPAS3S_d111_sasCsError" 16494 "EPAS3S_d110_sasCntError" 16493 "EPAS3S_d109_sasMia" 16492 "EPAS3S_d108_diCsError" 16491 "EPAS3S_d107_diCntError" 16490 "EPAS3S_d106_diMia" 16489 "EPAS3S_d105_apsCsError" 16488 "EPAS3S_d104_apsCntError" 16487 "EPAS3S_d103_apsMia" 16486 "EPAS3S_d102_gtwCsError" 16485 "EPAS3S_d101_gtwCntError" 16484 "EPAS3S_d100_gtwMia" 16483 "EPAS3S_d099_espcQf" 16482 "EPAS3S_d098_espcCsError" 16481 "EPAS3S_d097_espcCntError" 16480 "EPAS3S_d096_espcMia" 16479 "EPAS3S_d095_espbQf" 16478 "EPAS3S_d094_espbCsError" 16477 "EPAS3S_d093_espbCntError" 16476 "EPAS3S_d092_espbMia" 16475 "EPAS3S_d091_espWsCsError" 16474 "EPAS3S_d090_espWsCntError" 16473 "EPAS3S_d089_espWsMia" 16472 "EPAS3S_d088_dasCsError" 16471 "EPAS3S_d087_dasCntError" 16470 "EPAS3S_d086_dasMia" 16469 "EPAS3S_d085_canBusOff" 16468 "EPAS3S_d084_eacCancelled" 16467 "EPAS3S_d083_crcMismatch" 16466 "EPAS3S_d082_polarityCalError" 16465 "EPAS3S_d081_coggCompError" 16464 "EPAS3S_d080_ecuInitArbError" 16463 "EPAS3S_d079_backupCurrentPlaus" 16462 "EPAS3S_d078_phaseDisconnectError" 16461 "EPAS3S_d077_highSideFetError" 16460 "EPAS3S_d076_tempSensOutofRange" 16459 "EPAS3S_d075_fspPwrCut" 16458 "EPAS3S_d074_overHeatProtect" 16457 "EPAS3S_d073_motParEstError" 16456 "EPAS3S_d072_motFeedFwdError" 16455 "EPAS3S_d071_vehSpdCorrError" 16454 "EPAS3S_d070_hodCorrError" 16453 "EPAS3S_d069_eacCorrError" 16452 "EPAS3S_d068_hystCorrError" 16451 "EPAS3S_d067_yawDampCorrError" 16450 "EPAS3S_d066_returnCorrError" 16449 "EPAS3S_d065_trqTarCorrError" 16448 "EPAS3S_d064_phaseCompCorrError" 16447 "EPAS3S_d063_dampCorrError" 16446 "EPAS3S_d062_assistCorrError" 16445 "EPAS3S_d061_bridgeUv" 16444 "EPAS3S_d060_battBridgeDiff" 16443 "EPAS3S_d059_battOvReduced" 16442 "EPAS3S_d058_battOv" 16441 "EPAS3S_d057_battUvReduced" 16440 "EPAS3S_d056_battUv" 16439 "EPAS3S_d055_floatPointError" 16438 "EPAS3S_d054_memoryProtectError" 16437 "EPAS3S_d053_extWatchdogError" 16436 "EPAS3S_d052_intWatchdogError" 16435 "EPAS3S_d051_mcuSupError" 16434 "EPAS3S_d050_mcuSmuError" 16433 "EPAS3S_d049_piCtrlError" 16432 "EPAS3S_d048_motPosCalError" 16431 "EPAS3S_d047_motPosCorrError" 16430 "EPAS3S_d046_motPos2tempError" 16429 "EPAS3S_d045_motPos2LogicError" 16428 "EPAS3S_d044_motPos2MagnetMia" 16427 "EPAS3S_d043_motPos2Uv" 16426 "EPAS3S_d042_motPos2ParityError" 16425 "EPAS3S_d041_motPos1tempError" 16424 "EPAS3S_d040_motPos1LogicError" 16423 "EPAS3S_d039_motPos1MagnetMia" 16422 "EPAS3S_d038_motPos1Uv" 16421 "EPAS3S_d037_motPos1ParityError" 16420 "EPAS3S_d036_vbbSupplyOv" 16419 "EPAS3S_d035_vbbSupplyUv" 16418 "EPAS3S_d034_vRegError" 16417 "EPAS3S_d033_vRegOutputOv" 16416 "EPAS3S_d032_vRegOutputUv" 16415 "EPAS3S_d031_abnormalShutdown" 16414 "EPAS3S_d030_phaseWbootUv" 16413 "EPAS3S_d029_phaseVbootUv" 16412 "EPAS3S_d028_phaseUbootUv" 16411 "EPAS3S_d027_phaseWlowOv" 16410 "EPAS3S_d026_phaseWhighOv" 16409 "EPAS3S_d025_phaseVlowOv" 16408 "EPAS3S_d024_phaseVhighOv" 16407 "EPAS3S_d023_phaseUlowOv" 16406 "EPAS3S_d022_phaseUhighOv" 16405 "EPAS3S_d021_phaseWlowUv" 16404 "EPAS3S_d020_phaseWhighUv" 16403 "EPAS3S_d019_phaseVlowUv" 16402 "EPAS3S_d018_phaseVhighUv" 16401 "EPAS3S_d017_phaseUlowUv" 16400 "EPAS3S_d016_phaseUhighUv" 16399 "EPAS3S_d015_gateDriveEeprom" 16398 "EPAS3S_d014_gateDriveTxError" 16397 "EPAS3S_d013_gateDriveError" 16396 "EPAS3S_d012_currentSensCalError" 16395 "EPAS3S_d011_currentSensError" 16394 "EPAS3S_d010_trqSensCalError" 16393 "EPAS3S_d009_sentDiff" 16392 "EPAS3S_d008_trqSens2Eeprom" 16391 "EPAS3S_d007_trqSens2Supply" 16390 "EPAS3S_d006_sent2Error" 16389 "EPAS3S_d005_sent2Mia" 16388 "EPAS3S_d004_trqSens1Eeprom" 16387 "EPAS3S_d003_trqSens1Supply" 16386 "EPAS3S_d002_sent1Error" 16385 "EPAS3S_d001_sent1Mia" ;
VAL_ 1425 EPAS3S_d081_eacCancelCode 15 "SNA" 13 "EAC_ERROR_EPB_INHIBIT" 12 "EAC_ERROR_LOW_ASSIST" 11 "EAC_ERROR_HIGH_TORSION_SAFETY" 10 "EAC_ERROR_HIGH_MMOT_SAFETY" 9 "EAC_ERROR_HIGH_ANGLE_RATE_SAFETY" 8 "EAC_ERROR_HIGH_ANGLE_SAFETY" 7 "EAC_ERROR_HIGH_ANGLE_RATE_REQ" 6 "EAC_ERROR_HIGH_ANGLE_REQ" 5 "EAR_ERROR_MAX_STEER_DELTA" 4 "EAC_ERROR_TMP_FAULT" 3 "EAC_ERROR_HANDS_ON" 2 "EAC_ERROR_MAX_SPEED" 1 "EAC_ERROR_MIN_SPEED" 0 "EAC_ERROR_IDLE" ;
VAL_ 913 EPAS3S_d001_sent1Mia 3 "UNABLE_TO_TEST_DTC" 2 "FAILED_DTC" 1 "PASSED_DTC" 0 "NOT_TESTED_DTC" ;
VAL_ 913 EPAS3S_d002_sent1Error 3 "UNABLE_TO_TEST_DTC" 2 "FAILED_DTC" 1 "PASSED_DTC" 0 "NOT_TESTED_DTC" ;
VAL_ 913 EPAS3S_d003_trqSens1Supply 3 "UNABLE_TO_TEST_DTC" 2 "FAILED_DTC" 1 "PASSED_DTC" 0 "NOT_TESTED_DTC" ;
VAL_ 913 EPAS3S_d004_trqSens1Eeprom 3 "UNABLE_TO_TEST_DTC" 2 "FAILED_DTC" 1 "PASSED_DTC" 0 "NOT_TESTED_DTC" ;
VAL_ 913 EPAS3S_d005_sent2Mia 3 "UNABLE_TO_TEST_DTC" 2 "FAILED_DTC" 1 "PASSED_DTC" 0 "NOT_TESTED_DTC" ;
VAL_ 913 EPAS3S_d006_sent2Error 3 "UNABLE_TO_TEST_DTC" 2 "FAILED_DTC" 1 "PASSED_DTC" 0 "NOT_TESTED_DTC" ;
VAL_ 913 EPAS3S_d007_trqSens2Supply 3 "UNABLE_TO_TEST_DTC" 2 "FAILED_DTC" 1 "PASSED_DTC" 0 "NOT_TESTED_DTC" ;
VAL_ 913 EPAS3S_d008_trqSens2Eeprom 3 "UNABLE_TO_TEST_DTC" 2 "FAILED_DTC" 1 "PASSED_DTC" 0 "NOT_TESTED_DTC" ;
VAL_ 913 EPAS3S_d009_sentDiff 3 "UNABLE_TO_TEST_DTC" 2 "FAILED_DTC" 1 "PASSED_DTC" 0 "NOT_TESTED_DTC" ;
VAL_ 913 EPAS3S_d010_trqSensCalError 3 "UNABLE_TO_TEST_DTC" 2 "FAILED_DTC" 1 "PASSED_DTC" 0 "NOT_TESTED_DTC" ;
VAL_ 913 EPAS3S_d011_currentSensError 3 "UNABLE_TO_TEST_DTC" 2 "FAILED_DTC" 1 "PASSED_DTC" 0 "NOT_TESTED_DTC" ;
VAL_ 913 EPAS3S_d012_currentSensCalError 3 "UNABLE_TO_TEST_DTC" 2 "FAILED_DTC" 1 "PASSED_DTC" 0 "NOT_TESTED_DTC" ;
VAL_ 913 EPAS3S_d013_gateDriveError 3 "UNABLE_TO_TEST_DTC" 2 "FAILED_DTC" 1 "PASSED_DTC" 0 "NOT_TESTED_DTC" ;
VAL_ 913 EPAS3S_d014_gateDriveTxError 3 "UNABLE_TO_TEST_DTC" 2 "FAILED_DTC" 1 "PASSED_DTC" 0 "NOT_TESTED_DTC" ;
VAL_ 913 EPAS3S_d015_gateDriveEeprom 3 "UNABLE_TO_TEST_DTC" 2 "FAILED_DTC" 1 "PASSED_DTC" 0 "NOT_TESTED_DTC" ;
VAL_ 913 EPAS3S_d016_phaseUhighUv 3 "UNABLE_TO_TEST_DTC" 2 "FAILED_DTC" 1 "PASSED_DTC" 0 "NOT_TESTED_DTC" ;
VAL_ 913 EPAS3S_d017_phaseUlowUv 3 "UNABLE_TO_TEST_DTC" 2 "FAILED_DTC" 1 "PASSED_DTC" 0 "NOT_TESTED_DTC" ;
VAL_ 913 EPAS3S_d018_phaseVhighUv 3 "UNABLE_TO_TEST_DTC" 2 "FAILED_DTC" 1 "PASSED_DTC" 0 "NOT_TESTED_DTC" ;
VAL_ 913 EPAS3S_d019_phaseVlowUv 3 "UNABLE_TO_TEST_DTC" 2 "FAILED_DTC" 1 "PASSED_DTC" 0 "NOT_TESTED_DTC" ;
VAL_ 913 EPAS3S_d020_phaseWhighUv 3 "UNABLE_TO_TEST_DTC" 2 "FAILED_DTC" 1 "PASSED_DTC" 0 "NOT_TESTED_DTC" ;
VAL_ 913 EPAS3S_d021_phaseWlowUv 3 "UNABLE_TO_TEST_DTC" 2 "FAILED_DTC" 1 "PASSED_DTC" 0 "NOT_TESTED_DTC" ;
VAL_ 913 EPAS3S_d022_phaseUhighOv 3 "UNABLE_TO_TEST_DTC" 2 "FAILED_DTC" 1 "PASSED_DTC" 0 "NOT_TESTED_DTC" ;
VAL_ 913 EPAS3S_d023_phaseUlowOv 3 "UNABLE_TO_TEST_DTC" 2 "FAILED_DTC" 1 "PASSED_DTC" 0 "NOT_TESTED_DTC" ;
VAL_ 913 EPAS3S_d024_phaseVhighOv 3 "UNABLE_TO_TEST_DTC" 2 "FAILED_DTC" 1 "PASSED_DTC" 0 "NOT_TESTED_DTC" ;
VAL_ 913 EPAS3S_d025_phaseVlowOv 3 "UNABLE_TO_TEST_DTC" 2 "FAILED_DTC" 1 "PASSED_DTC" 0 "NOT_TESTED_DTC" ;
VAL_ 913 EPAS3S_d026_phaseWhighOv 3 "UNABLE_TO_TEST_DTC" 2 "FAILED_DTC" 1 "PASSED_DTC" 0 "NOT_TESTED_DTC" ;
VAL_ 913 EPAS3S_d027_phaseWlowOv 3 "UNABLE_TO_TEST_DTC" 2 "FAILED_DTC" 1 "PASSED_DTC" 0 "NOT_TESTED_DTC" ;
VAL_ 913 EPAS3S_d028_phaseUbootUv 3 "UNABLE_TO_TEST_DTC" 2 "FAILED_DTC" 1 "PASSED_DTC" 0 "NOT_TESTED_DTC" ;
VAL_ 913 EPAS3S_d029_phaseVbootUv 3 "UNABLE_TO_TEST_DTC" 2 "FAILED_DTC" 1 "PASSED_DTC" 0 "NOT_TESTED_DTC" ;
VAL_ 913 EPAS3S_d030_phaseWbootUv 3 "UNABLE_TO_TEST_DTC" 2 "FAILED_DTC" 1 "PASSED_DTC" 0 "NOT_TESTED_DTC" ;
VAL_ 913 EPAS3S_d031_abnormalShutdown 3 "UNABLE_TO_TEST_DTC" 2 "FAILED_DTC" 1 "PASSED_DTC" 0 "NOT_TESTED_DTC" ;
VAL_ 913 EPAS3S_d032_vRegOutputUv 3 "UNABLE_TO_TEST_DTC" 2 "FAILED_DTC" 1 "PASSED_DTC" 0 "NOT_TESTED_DTC" ;
VAL_ 913 EPAS3S_d033_vRegOutputOv 3 "UNABLE_TO_TEST_DTC" 2 "FAILED_DTC" 1 "PASSED_DTC" 0 "NOT_TESTED_DTC" ;
VAL_ 913 EPAS3S_d034_vRegError 3 "UNABLE_TO_TEST_DTC" 2 "FAILED_DTC" 1 "PASSED_DTC" 0 "NOT_TESTED_DTC" ;
VAL_ 913 EPAS3S_d035_vbbSupplyUv 3 "UNABLE_TO_TEST_DTC" 2 "FAILED_DTC" 1 "PASSED_DTC" 0 "NOT_TESTED_DTC" ;
VAL_ 913 EPAS3S_d036_vbbSupplyOv 3 "UNABLE_TO_TEST_DTC" 2 "FAILED_DTC" 1 "PASSED_DTC" 0 "NOT_TESTED_DTC" ;
VAL_ 913 EPAS3S_d037_motPos1ParityError 3 "UNABLE_TO_TEST_DTC" 2 "FAILED_DTC" 1 "PASSED_DTC" 0 "NOT_TESTED_DTC" ;
VAL_ 913 EPAS3S_d038_motPos1Uv 3 "UNABLE_TO_TEST_DTC" 2 "FAILED_DTC" 1 "PASSED_DTC" 0 "NOT_TESTED_DTC" ;
VAL_ 913 EPAS3S_d039_motPos1MagnetMia 3 "UNABLE_TO_TEST_DTC" 2 "FAILED_DTC" 1 "PASSED_DTC" 0 "NOT_TESTED_DTC" ;
VAL_ 913 EPAS3S_d040_motPos1LogicError 3 "UNABLE_TO_TEST_DTC" 2 "FAILED_DTC" 1 "PASSED_DTC" 0 "NOT_TESTED_DTC" ;
VAL_ 913 EPAS3S_d041_motPos1tempError 3 "UNABLE_TO_TEST_DTC" 2 "FAILED_DTC" 1 "PASSED_DTC" 0 "NOT_TESTED_DTC" ;
VAL_ 913 EPAS3S_d042_motPos2ParityError 3 "UNABLE_TO_TEST_DTC" 2 "FAILED_DTC" 1 "PASSED_DTC" 0 "NOT_TESTED_DTC" ;
VAL_ 913 EPAS3S_d043_motPos2Uv 3 "UNABLE_TO_TEST_DTC" 2 "FAILED_DTC" 1 "PASSED_DTC" 0 "NOT_TESTED_DTC" ;
VAL_ 913 EPAS3S_d044_motPos2MagnetMia 3 "UNABLE_TO_TEST_DTC" 2 "FAILED_DTC" 1 "PASSED_DTC" 0 "NOT_TESTED_DTC" ;
VAL_ 913 EPAS3S_d045_motPos2LogicError 3 "UNABLE_TO_TEST_DTC" 2 "FAILED_DTC" 1 "PASSED_DTC" 0 "NOT_TESTED_DTC" ;
VAL_ 913 EPAS3S_d046_motPos2tempError 3 "UNABLE_TO_TEST_DTC" 2 "FAILED_DTC" 1 "PASSED_DTC" 0 "NOT_TESTED_DTC" ;
VAL_ 913 EPAS3S_d047_motPosCorrError 3 "UNABLE_TO_TEST_DTC" 2 "FAILED_DTC" 1 "PASSED_DTC" 0 "NOT_TESTED_DTC" ;
VAL_ 913 EPAS3S_d048_motPosCalError 3 "UNABLE_TO_TEST_DTC" 2 "FAILED_DTC" 1 "PASSED_DTC" 0 "NOT_TESTED_DTC" ;
VAL_ 913 EPAS3S_d049_piCtrlError 3 "UNABLE_TO_TEST_DTC" 2 "FAILED_DTC" 1 "PASSED_DTC" 0 "NOT_TESTED_DTC" ;
VAL_ 913 EPAS3S_d050_mcuSmuError 3 "UNABLE_TO_TEST_DTC" 2 "FAILED_DTC" 1 "PASSED_DTC" 0 "NOT_TESTED_DTC" ;
VAL_ 913 EPAS3S_d051_mcuSupError 3 "UNABLE_TO_TEST_DTC" 2 "FAILED_DTC" 1 "PASSED_DTC" 0 "NOT_TESTED_DTC" ;
VAL_ 913 EPAS3S_d052_intWatchdogError 3 "UNABLE_TO_TEST_DTC" 2 "FAILED_DTC" 1 "PASSED_DTC" 0 "NOT_TESTED_DTC" ;
VAL_ 913 EPAS3S_d053_extWatchdogError 3 "UNABLE_TO_TEST_DTC" 2 "FAILED_DTC" 1 "PASSED_DTC" 0 "NOT_TESTED_DTC" ;
VAL_ 913 EPAS3S_d054_memoryProtectError 3 "UNABLE_TO_TEST_DTC" 2 "FAILED_DTC" 1 "PASSED_DTC" 0 "NOT_TESTED_DTC" ;
VAL_ 913 EPAS3S_d055_floatPointError 3 "UNABLE_TO_TEST_DTC" 2 "FAILED_DTC" 1 "PASSED_DTC" 0 "NOT_TESTED_DTC" ;
VAL_ 913 EPAS3S_d056_battUv 3 "UNABLE_TO_TEST_DTC" 2 "FAILED_DTC" 1 "PASSED_DTC" 0 "NOT_TESTED_DTC" ;
VAL_ 913 EPAS3S_d057_battUvReduced 3 "UNABLE_TO_TEST_DTC" 2 "FAILED_DTC" 1 "PASSED_DTC" 0 "NOT_TESTED_DTC" ;
VAL_ 913 EPAS3S_d058_battOv 3 "UNABLE_TO_TEST_DTC" 2 "FAILED_DTC" 1 "PASSED_DTC" 0 "NOT_TESTED_DTC" ;
VAL_ 913 EPAS3S_d059_battOvReduced 3 "UNABLE_TO_TEST_DTC" 2 "FAILED_DTC" 1 "PASSED_DTC" 0 "NOT_TESTED_DTC" ;
VAL_ 913 EPAS3S_d060_battBridgeDiff 3 "UNABLE_TO_TEST_DTC" 2 "FAILED_DTC" 1 "PASSED_DTC" 0 "NOT_TESTED_DTC" ;
VAL_ 913 EPAS3S_d061_bridgeUv 3 "UNABLE_TO_TEST_DTC" 2 "FAILED_DTC" 1 "PASSED_DTC" 0 "NOT_TESTED_DTC" ;
VAL_ 913 EPAS3S_d062_assistCorrError 3 "UNABLE_TO_TEST_DTC" 2 "FAILED_DTC" 1 "PASSED_DTC" 0 "NOT_TESTED_DTC" ;
VAL_ 913 EPAS3S_d063_dampCorrError 3 "UNABLE_TO_TEST_DTC" 2 "FAILED_DTC" 1 "PASSED_DTC" 0 "NOT_TESTED_DTC" ;
VAL_ 913 EPAS3S_d064_phaseCompCorrError 3 "UNABLE_TO_TEST_DTC" 2 "FAILED_DTC" 1 "PASSED_DTC" 0 "NOT_TESTED_DTC" ;
VAL_ 913 EPAS3S_d065_trqTarCorrError 3 "UNABLE_TO_TEST_DTC" 2 "FAILED_DTC" 1 "PASSED_DTC" 0 "NOT_TESTED_DTC" ;
VAL_ 913 EPAS3S_d066_returnCorrError 3 "UNABLE_TO_TEST_DTC" 2 "FAILED_DTC" 1 "PASSED_DTC" 0 "NOT_TESTED_DTC" ;
VAL_ 913 EPAS3S_d067_yawDampCorrError 3 "UNABLE_TO_TEST_DTC" 2 "FAILED_DTC" 1 "PASSED_DTC" 0 "NOT_TESTED_DTC" ;
VAL_ 913 EPAS3S_d068_hystCorrError 3 "UNABLE_TO_TEST_DTC" 2 "FAILED_DTC" 1 "PASSED_DTC" 0 "NOT_TESTED_DTC" ;
VAL_ 913 EPAS3S_d069_eacCorrError 3 "UNABLE_TO_TEST_DTC" 2 "FAILED_DTC" 1 "PASSED_DTC" 0 "NOT_TESTED_DTC" ;
VAL_ 913 EPAS3S_d070_hodCorrError 3 "UNABLE_TO_TEST_DTC" 2 "FAILED_DTC" 1 "PASSED_DTC" 0 "NOT_TESTED_DTC" ;
VAL_ 913 EPAS3S_d071_vehSpdCorrError 3 "UNABLE_TO_TEST_DTC" 2 "FAILED_DTC" 1 "PASSED_DTC" 0 "NOT_TESTED_DTC" ;
VAL_ 913 EPAS3S_d072_motFeedFwdError 3 "UNABLE_TO_TEST_DTC" 2 "FAILED_DTC" 1 "PASSED_DTC" 0 "NOT_TESTED_DTC" ;
VAL_ 913 EPAS3S_d073_motParEstError 3 "UNABLE_TO_TEST_DTC" 2 "FAILED_DTC" 1 "PASSED_DTC" 0 "NOT_TESTED_DTC" ;
VAL_ 913 EPAS3S_d074_overHeatProtect 3 "UNABLE_TO_TEST_DTC" 2 "FAILED_DTC" 1 "PASSED_DTC" 0 "NOT_TESTED_DTC" ;
VAL_ 913 EPAS3S_d075_fspPwrCut 3 "UNABLE_TO_TEST_DTC" 2 "FAILED_DTC" 1 "PASSED_DTC" 0 "NOT_TESTED_DTC" ;
VAL_ 913 EPAS3S_d076_tempSensOutofRange 3 "UNABLE_TO_TEST_DTC" 2 "FAILED_DTC" 1 "PASSED_DTC" 0 "NOT_TESTED_DTC" ;
VAL_ 913 EPAS3S_d077_highSideFetError 3 "UNABLE_TO_TEST_DTC" 2 "FAILED_DTC" 1 "PASSED_DTC" 0 "NOT_TESTED_DTC" ;
VAL_ 913 EPAS3S_d078_phaseDisconnectError 3 "UNABLE_TO_TEST_DTC" 2 "FAILED_DTC" 1 "PASSED_DTC" 0 "NOT_TESTED_DTC" ;
VAL_ 913 EPAS3S_d079_backupCurrentPlaus 3 "UNABLE_TO_TEST_DTC" 2 "FAILED_DTC" 1 "PASSED_DTC" 0 "NOT_TESTED_DTC" ;
VAL_ 913 EPAS3S_d080_ecuInitArbError 3 "UNABLE_TO_TEST_DTC" 2 "FAILED_DTC" 1 "PASSED_DTC" 0 "NOT_TESTED_DTC" ;
VAL_ 913 EPAS3S_d081_coggCompError 3 "UNABLE_TO_TEST_DTC" 2 "FAILED_DTC" 1 "PASSED_DTC" 0 "NOT_TESTED_DTC" ;
VAL_ 913 EPAS3S_d082_polarityCalError 3 "UNABLE_TO_TEST_DTC" 2 "FAILED_DTC" 1 "PASSED_DTC" 0 "NOT_TESTED_DTC" ;
VAL_ 913 EPAS3S_d083_crcMismatch 3 "UNABLE_TO_TEST_DTC" 2 "FAILED_DTC" 1 "PASSED_DTC" 0 "NOT_TESTED_DTC" ;
VAL_ 913 EPAS3S_d084_eacCancelled 3 "UNABLE_TO_TEST_DTC" 2 "FAILED_DTC" 1 "PASSED_DTC" 0 "NOT_TESTED_DTC" ;
VAL_ 913 EPAS3S_d085_canBusOff 3 "UNABLE_TO_TEST_DTC" 2 "FAILED_DTC" 1 "PASSED_DTC" 0 "NOT_TESTED_DTC" ;
VAL_ 913 EPAS3S_d086_dasMia 3 "UNABLE_TO_TEST_DTC" 2 "FAILED_DTC" 1 "PASSED_DTC" 0 "NOT_TESTED_DTC" ;
VAL_ 913 EPAS3S_d087_dasCntError 3 "UNABLE_TO_TEST_DTC" 2 "FAILED_DTC" 1 "PASSED_DTC" 0 "NOT_TESTED_DTC" ;
VAL_ 913 EPAS3S_d088_dasCsError 3 "UNABLE_TO_TEST_DTC" 2 "FAILED_DTC" 1 "PASSED_DTC" 0 "NOT_TESTED_DTC" ;
VAL_ 913 EPAS3S_d089_espWsMia 3 "UNABLE_TO_TEST_DTC" 2 "FAILED_DTC" 1 "PASSED_DTC" 0 "NOT_TESTED_DTC" ;
VAL_ 913 EPAS3S_d090_espWsCntError 3 "UNABLE_TO_TEST_DTC" 2 "FAILED_DTC" 1 "PASSED_DTC" 0 "NOT_TESTED_DTC" ;
VAL_ 913 EPAS3S_d091_espWsCsError 3 "UNABLE_TO_TEST_DTC" 2 "FAILED_DTC" 1 "PASSED_DTC" 0 "NOT_TESTED_DTC" ;
VAL_ 913 EPAS3S_d092_espbMia 3 "UNABLE_TO_TEST_DTC" 2 "FAILED_DTC" 1 "PASSED_DTC" 0 "NOT_TESTED_DTC" ;
VAL_ 913 EPAS3S_d093_espbCntError 3 "UNABLE_TO_TEST_DTC" 2 "FAILED_DTC" 1 "PASSED_DTC" 0 "NOT_TESTED_DTC" ;
VAL_ 913 EPAS3S_d094_espbCsError 3 "UNABLE_TO_TEST_DTC" 2 "FAILED_DTC" 1 "PASSED_DTC" 0 "NOT_TESTED_DTC" ;
VAL_ 913 EPAS3S_d095_espbQf 3 "UNABLE_TO_TEST_DTC" 2 "FAILED_DTC" 1 "PASSED_DTC" 0 "NOT_TESTED_DTC" ;
VAL_ 913 EPAS3S_d096_espcMia 3 "UNABLE_TO_TEST_DTC" 2 "FAILED_DTC" 1 "PASSED_DTC" 0 "NOT_TESTED_DTC" ;
VAL_ 913 EPAS3S_d097_espcCntError 3 "UNABLE_TO_TEST_DTC" 2 "FAILED_DTC" 1 "PASSED_DTC" 0 "NOT_TESTED_DTC" ;
VAL_ 913 EPAS3S_d098_espcCsError 3 "UNABLE_TO_TEST_DTC" 2 "FAILED_DTC" 1 "PASSED_DTC" 0 "NOT_TESTED_DTC" ;
VAL_ 913 EPAS3S_d099_espcQf 3 "UNABLE_TO_TEST_DTC" 2 "FAILED_DTC" 1 "PASSED_DTC" 0 "NOT_TESTED_DTC" ;
VAL_ 913 EPAS3S_d100_gtwMia 3 "UNABLE_TO_TEST_DTC" 2 "FAILED_DTC" 1 "PASSED_DTC" 0 "NOT_TESTED_DTC" ;
VAL_ 913 EPAS3S_d101_gtwCntError 3 "UNABLE_TO_TEST_DTC" 2 "FAILED_DTC" 1 "PASSED_DTC" 0 "NOT_TESTED_DTC" ;
VAL_ 913 EPAS3S_d102_gtwCsError 3 "UNABLE_TO_TEST_DTC" 2 "FAILED_DTC" 1 "PASSED_DTC" 0 "NOT_TESTED_DTC" ;
VAL_ 913 EPAS3S_d103_apsMia 3 "UNABLE_TO_TEST_DTC" 2 "FAILED_DTC" 1 "PASSED_DTC" 0 "NOT_TESTED_DTC" ;
VAL_ 913 EPAS3S_d104_apsCntError 3 "UNABLE_TO_TEST_DTC" 2 "FAILED_DTC" 1 "PASSED_DTC" 0 "NOT_TESTED_DTC" ;
VAL_ 913 EPAS3S_d105_apsCsError 3 "UNABLE_TO_TEST_DTC" 2 "FAILED_DTC" 1 "PASSED_DTC" 0 "NOT_TESTED_DTC" ;
VAL_ 913 EPAS3S_d106_diMia 3 "UNABLE_TO_TEST_DTC" 2 "FAILED_DTC" 1 "PASSED_DTC" 0 "NOT_TESTED_DTC" ;
VAL_ 913 EPAS3S_d107_diCntError 3 "UNABLE_TO_TEST_DTC" 2 "FAILED_DTC" 1 "PASSED_DTC" 0 "NOT_TESTED_DTC" ;
VAL_ 913 EPAS3S_d108_diCsError 3 "UNABLE_TO_TEST_DTC" 2 "FAILED_DTC" 1 "PASSED_DTC" 0 "NOT_TESTED_DTC" ;
VAL_ 913 EPAS3S_d109_sasMia 3 "UNABLE_TO_TEST_DTC" 2 "FAILED_DTC" 1 "PASSED_DTC" 0 "NOT_TESTED_DTC" ;
VAL_ 913 EPAS3S_d110_sasCntError 3 "UNABLE_TO_TEST_DTC" 2 "FAILED_DTC" 1 "PASSED_DTC" 0 "NOT_TESTED_DTC" ;
VAL_ 913 EPAS3S_d111_sasCsError 3 "UNABLE_TO_TEST_DTC" 2 "FAILED_DTC" 1 "PASSED_DTC" 0 "NOT_TESTED_DTC" ;
VAL_ 913 EPAS3S_d112_sasStatError 3 "UNABLE_TO_TEST_DTC" 2 "FAILED_DTC" 1 "PASSED_DTC" 0 "NOT_TESTED_DTC" ;
VAL_ 913 EPAS3S_d113_espWsQf 3 "UNABLE_TO_TEST_DTC" 2 "FAILED_DTC" 1 "PASSED_DTC" 0 "NOT_TESTED_DTC" ;
VAL_ 913 EPAS3S_d114_gtwOdoMia 3 "UNABLE_TO_TEST_DTC" 2 "FAILED_DTC" 1 "PASSED_DTC" 0 "NOT_TESTED_DTC" ;
VAL_ 913 EPAS3S_d115_ecuStatMia 3 "UNABLE_TO_TEST_DTC" 2 "FAILED_DTC" 1 "PASSED_DTC" 0 "NOT_TESTED_DTC" ;
VAL_ 913 EPAS3S_d116_ecuStatCntError 3 "UNABLE_TO_TEST_DTC" 2 "FAILED_DTC" 1 "PASSED_DTC" 0 "NOT_TESTED_DTC" ;
VAL_ 913 EPAS3S_d117_ecuStatCrcError 3 "UNABLE_TO_TEST_DTC" 2 "FAILED_DTC" 1 "PASSED_DTC" 0 "NOT_TESTED_DTC" ;
VAL_ 913 EPAS3S_d118_espPriv1Mia 3 "UNABLE_TO_TEST_DTC" 2 "FAILED_DTC" 1 "PASSED_DTC" 0 "NOT_TESTED_DTC" ;
VAL_ 913 EPAS3S_d119_espPriv1CntError 3 "UNABLE_TO_TEST_DTC" 2 "FAILED_DTC" 1 "PASSED_DTC" 0 "NOT_TESTED_DTC" ;
VAL_ 913 EPAS3S_d120_espPriv1CsError 3 "UNABLE_TO_TEST_DTC" 2 "FAILED_DTC" 1 "PASSED_DTC" 0 "NOT_TESTED_DTC" ;
VAL_ 913 EPAS3S_d121_espPriv1Qf 3 "UNABLE_TO_TEST_DTC" 2 "FAILED_DTC" 1 "PASSED_DTC" 0 "NOT_TESTED_DTC" ;
VAL_ 913 EPAS3S_d122_privateBusOff 3 "UNABLE_TO_TEST_DTC" 2 "FAILED_DTC" 1 "PASSED_DTC" 0 "NOT_TESTED_DTC" ;
VAL_ 913 EPAS3S_d123_pvtEcuStatMia 3 "UNABLE_TO_TEST_DTC" 2 "FAILED_DTC" 1 "PASSED_DTC" 0 "NOT_TESTED_DTC" ;
VAL_ 913 EPAS3S_d124_pvtEcuStatCntError 3 "UNABLE_TO_TEST_DTC" 2 "FAILED_DTC" 1 "PASSED_DTC" 0 "NOT_TESTED_DTC" ;
VAL_ 913 EPAS3S_d125_pvtEcuStatCrcError 3 "UNABLE_TO_TEST_DTC" 2 "FAILED_DTC" 1 "PASSED_DTC" 0 "NOT_TESTED_DTC" ;
VAL_ 913 EPAS3S_d126_olpActive 3 "UNABLE_TO_TEST_DTC" 2 "FAILED_DTC" 1 "PASSED_DTC" 0 "NOT_TESTED_DTC" ;
VAL_ 913 EPAS3S_d127_combEcu2StatFail 3 "UNABLE_TO_TEST_DTC" 2 "FAILED_DTC" 1 "PASSED_DTC" 0 "NOT_TESTED_DTC" ;
VAL_ 913 EPAS3S_d128_tempSensStuckInRange 3 "UNABLE_TO_TEST_DTC" 2 "FAILED_DTC" 1 "PASSED_DTC" 0 "NOT_TESTED_DTC" ;
VAL_ 913 EPAS3S_d129_trqSensTrimOutRange 3 "UNABLE_TO_TEST_DTC" 2 "FAILED_DTC" 1 "PASSED_DTC" 0 "NOT_TESTED_DTC" ;
VAL_ 913 EPAS3S_d130_combEcu1StatFail 3 "UNABLE_TO_TEST_DTC" 2 "FAILED_DTC" 1 "PASSED_DTC" 0 "NOT_TESTED_DTC" ;
VAL_ 913 EPAS3S_d131_sasOffsetNotCal 3 "UNABLE_TO_TEST_DTC" 2 "FAILED_DTC" 1 "PASSED_DTC" 0 "NOT_TESTED_DTC" ;
VAL_ 913 EPAS3S_d132_phaseFeedbackError 3 "UNABLE_TO_TEST_DTC" 2 "FAILED_DTC" 1 "PASSED_DTC" 0 "NOT_TESTED_DTC" ;
VAL_ 81 EPAS3S_state 15 "INVALID" 8 "EAC_STANDBY" 7 "EAC_ACTIVE" 6 "ASSIST_STANDBY" 5 "ASSIST_ACTIVE" 4 "PASSIVE_FAULTED" 3 "PASSIVE" 2 "INIT_COMPLETE" 1 "INIT_PHASECUT_TEST" 0 "INIT_ARBITRATION" ;
VAL_ 81 EPAS3S_powerMode 7 "SNA" 6 "POWERING_DOWN" 5 "LIMP_3" 4 "LIMP_2" 3 "LIMP_1" 2 "DRIVE_ON" 1 "EMERGENCY_ON" 0 "DRIVE_OFF" ;
VAL_ 81 EPAS3S_role 2 "RESERVED" 1 "SLAVE" 0 "MASTER" ;
VAL_ 1456 EPAS_alertID 16461 "EPAS_d077_KFC_STEERING_CONTROL" 16460 "EPAS_d076_KFC_DAS_TIMO" 16459 "EPAS_d075_KFC_BLOCKED_STEERING" 16458 "EPAS_d074_KFC_SSW" 16457 "EPAS_d073_KFC_UCO_RED" 16456 "EPAS_d072_KFC_OS_MON" 16455 "EPAS_d071_KFC_PD_RED" 16454 "EPAS_d070_KFC_ROTANG" 16453 "EPAS_d069_KFC_CR_RED_INFO" 16452 "EPAS_d068_KFC_UCO_RED_INFO" 16451 "EPAS_d067_KFC_CCU_RED_INFO" 16450 "EPAS_d066_KFC_UCU_RED_INFO" 16449 "EPAS_d065_KFC_YAW_RATE" 16448 "EPAS_d064_KFC_DI_MOTORRPM" 16447 "EPAS_d063_KFC_UNUSED_63" 16446 "EPAS_d062_KFC_WHEEL_SPEEDS" 16445 "EPAS_d061_KFC_UNUSED_61" 16444 "EPAS_d060_KFC_POWER_MODE" 16443 "EPAS_d059_KFC_TEMP_DIAG_DEV" 16442 "EPAS_d058_KFC_EXPULSION_MODE" 16441 "EPAS_d057_KFC_FRICTION" 16440 "EPAS_d056_KFC_UNUSED_56" 16439 "EPAS_d055_KFC_CCF_INVALID" 16438 "EPAS_d054_KFC_CCF_NOT_CONFIGURED" 16437 "EPAS_d053_KFC_UNUSED_53" 16436 "EPAS_d052_KFC_UNUSED_52" 16435 "EPAS_d051_KFC_VEHICLE_SPEED" 16434 "EPAS_d050_KFC_STEERING_ANGLE" 16433 "EPAS_d049_KFC_ESRA_CANCELLED" 16432 "EPAS_d048_KFC_EPB_TIMO" 16431 "EPAS_d047_KFC_EACALLOW" 16430 "EPAS_d046_KFC_SAS_TIMO" 16429 "EPAS_d045_KFC_DI_Torque1_TIMO" 16428 "EPAS_d044_KFC_GTW_TIMO" 16427 "EPAS_d043_KFC_ESP_TIMO" 16426 "EPAS_d042_KFC_RSDIFF" 16425 "EPAS_d041_KFC_U_REDUNDANT" 16424 "EPAS_d040_KFC_RSRADIUS" 16423 "EPAS_d039_KFC_RESET" 16422 "EPAS_d038_KFC_BUS_OFF" 16421 "EPAS_d037_KFC_FOR_LENGTH" 16420 "EPAS_d036_KFC_FOR_ANGLE" 16419 "EPAS_d035_KFC_FOR_WREL" 16418 "EPAS_d034_KFC_FOR_OC" 16417 "EPAS_d033_KFC_SWGEN" 16416 "EPAS_d032_KFC_ROM" 16415 "EPAS_d031_KFC_CR_RED" 16414 "EPAS_d030_KFC_REG_CHECK" 16413 "EPAS_d029_KFC_CST" 16412 "EPAS_d028_KFC_PROG_WD" 16411 "EPAS_d027_KFC_FOR_TIMO" 16410 "EPAS_d026_KFC_STORQUE_RAD" 16409 "EPAS_d025_KFC_STORQUE_OC" 16408 "EPAS_d024_KFC_PROGFLOW" 16407 "EPAS_d023_KFC_PWD" 16406 "EPAS_d022_KFC_SPI_SYNC_REG" 16405 "EPAS_d021_KFC_SPI_COM_TIMO" 16404 "EPAS_d020_KFC_RAM" 16403 "EPAS_d019_KFC_UKL30_2L_OFF" 16402 "EPAS_d018_KFC_UKL30_2H_OFF" 16401 "EPAS_d017_KFC_UUT_RED" 16400 "EPAS_d016_KFC_CCU_RED" 16399 "EPAS_d015_KFC_UCU_RED" 16398 "EPAS_d014_KFC_UKL30_2L" 16397 "EPAS_d013_KFC_UKL30_2H" 16396 "EPAS_d012_KFC_ADC" 16395 "EPAS_d011_KFC_COMP_L2" 16394 "EPAS_d010_KFC_COMP_L1" 16393 "EPAS_d009_KFC_WD_CHECK" 16392 "EPAS_d008_KFC_SHUT_DOWN" 16391 "EPAS_d007_KFC_OUTPUT_STAGE_DRV" 16390 "EPAS_d006_KFC_CLOCKMON" 16389 "EPAS_d005_KFC_ASIC" 16388 "EPAS_d004_KFC_NVRAM_MNG_VERIFY" 16387 "EPAS_d003_KFC_NVRAM_MNG_WRITE" 16386 "EPAS_d002_KFC_NVRAM_MNG_READ" 16385 "EPAS_d001_KFC_STORQUE_0" ;
VAL_ 1456 EPAS_d049_ESRACancelCode 15 "SNA" 12 "EAC_ERROR_LOW_ASSIST" 11 "EAC_ERROR_HIGH_TORSION_SAFETY" 10 "EAC_ERROR_HIGH_MMOT_SAFETY" 9 "EAC_ERROR_HIGH_ANGLE_RATE_SAFETY" 8 "EAC_ERROR_HIGH_ANGLE_SAFETY" 7 "EAC_ERROR_HIGH_ANGLE_RATE_REQ" 6 "EAC_ERROR_HIGH_ANGLE_REQ" 5 "EAR_ERROR_MAX_STEER_DELTA" 4 "EAC_ERROR_TMP_FAULT" 3 "EAC_ERROR_HANDS_ON" 2 "EAC_ERROR_MAX_SPEED" 1 "EAC_ERROR_MIN_SPEED" 0 "EAC_ERROR_IDLE" ;
VAL_ 977 EPAS_resyncStatus 1 "RESYNC_COMPLETE" 0 "RESYNC_PENDING" ;
VAL_ 896 EPAS_d001_KFC_STORQUE_0 3 "UNABLE_TO_TEST_DTC" 2 "FAILED_DTC" 1 "PASSED_DTC" 0 "NOT_TESTED_DTC" ;
VAL_ 896 EPAS_d002_KFC_NVRAM_MNG_READ 3 "UNABLE_TO_TEST_DTC" 2 "FAILED_DTC" 1 "PASSED_DTC" 0 "NOT_TESTED_DTC" ;
VAL_ 896 EPAS_d003_KFC_NVRAM_MNG_WRITE 3 "UNABLE_TO_TEST_DTC" 2 "FAILED_DTC" 1 "PASSED_DTC" 0 "NOT_TESTED_DTC" ;
VAL_ 896 EPAS_d004_KFC_NVRAM_MNG_VERIFY 3 "UNABLE_TO_TEST_DTC" 2 "FAILED_DTC" 1 "PASSED_DTC" 0 "NOT_TESTED_DTC" ;
VAL_ 896 EPAS_d005_KFC_ASIC 3 "UNABLE_TO_TEST_DTC" 2 "FAILED_DTC" 1 "PASSED_DTC" 0 "NOT_TESTED_DTC" ;
VAL_ 896 EPAS_d006_KFC_CLOCKMON 3 "UNABLE_TO_TEST_DTC" 2 "FAILED_DTC" 1 "PASSED_DTC" 0 "NOT_TESTED_DTC" ;
VAL_ 896 EPAS_d007_KFC_OUTPUT_STAGE_DRV 3 "UNABLE_TO_TEST_DTC" 2 "FAILED_DTC" 1 "PASSED_DTC" 0 "NOT_TESTED_DTC" ;
VAL_ 896 EPAS_d008_KFC_SHUT_DOWN 3 "UNABLE_TO_TEST_DTC" 2 "FAILED_DTC" 1 "PASSED_DTC" 0 "NOT_TESTED_DTC" ;
VAL_ 896 EPAS_d009_KFC_WD_CHECK 3 "UNABLE_TO_TEST_DTC" 2 "FAILED_DTC" 1 "PASSED_DTC" 0 "NOT_TESTED_DTC" ;
VAL_ 896 EPAS_d010_KFC_COMP_L1 3 "UNABLE_TO_TEST_DTC" 2 "FAILED_DTC" 1 "PASSED_DTC" 0 "NOT_TESTED_DTC" ;
VAL_ 896 EPAS_d011_KFC_COMP_L2 3 "UNABLE_TO_TEST_DTC" 2 "FAILED_DTC" 1 "PASSED_DTC" 0 "NOT_TESTED_DTC" ;
VAL_ 896 EPAS_d012_KFC_ADC 3 "UNABLE_TO_TEST_DTC" 2 "FAILED_DTC" 1 "PASSED_DTC" 0 "NOT_TESTED_DTC" ;
VAL_ 896 EPAS_d013_KFC_UKL30_2H 3 "UNABLE_TO_TEST_DTC" 2 "FAILED_DTC" 1 "PASSED_DTC" 0 "NOT_TESTED_DTC" ;
VAL_ 896 EPAS_d014_KFC_UKL30_2L 3 "UNABLE_TO_TEST_DTC" 2 "FAILED_DTC" 1 "PASSED_DTC" 0 "NOT_TESTED_DTC" ;
VAL_ 896 EPAS_d015_KFC_UCU_RED 3 "UNABLE_TO_TEST_DTC" 2 "FAILED_DTC" 1 "PASSED_DTC" 0 "NOT_TESTED_DTC" ;
VAL_ 896 EPAS_d016_KFC_CCU_RED 3 "UNABLE_TO_TEST_DTC" 2 "FAILED_DTC" 1 "PASSED_DTC" 0 "NOT_TESTED_DTC" ;
VAL_ 896 EPAS_d017_KFC_UUT_RED 3 "UNABLE_TO_TEST_DTC" 2 "FAILED_DTC" 1 "PASSED_DTC" 0 "NOT_TESTED_DTC" ;
VAL_ 896 EPAS_d018_KFC_UKL30_2H_OFF 3 "UNABLE_TO_TEST_DTC" 2 "FAILED_DTC" 1 "PASSED_DTC" 0 "NOT_TESTED_DTC" ;
VAL_ 896 EPAS_d019_KFC_UKL30_2L_OFF 3 "UNABLE_TO_TEST_DTC" 2 "FAILED_DTC" 1 "PASSED_DTC" 0 "NOT_TESTED_DTC" ;
VAL_ 896 EPAS_d020_KFC_RAM 3 "UNABLE_TO_TEST_DTC" 2 "FAILED_DTC" 1 "PASSED_DTC" 0 "NOT_TESTED_DTC" ;
VAL_ 896 EPAS_d021_KFC_SPI_COM_TIMO 3 "UNABLE_TO_TEST_DTC" 2 "FAILED_DTC" 1 "PASSED_DTC" 0 "NOT_TESTED_DTC" ;
VAL_ 896 EPAS_d022_KFC_SPI_SYNC_REG 3 "UNABLE_TO_TEST_DTC" 2 "FAILED_DTC" 1 "PASSED_DTC" 0 "NOT_TESTED_DTC" ;
VAL_ 896 EPAS_d023_KFC_PWD 3 "UNABLE_TO_TEST_DTC" 2 "FAILED_DTC" 1 "PASSED_DTC" 0 "NOT_TESTED_DTC" ;
VAL_ 896 EPAS_d024_KFC_PROGFLOW 3 "UNABLE_TO_TEST_DTC" 2 "FAILED_DTC" 1 "PASSED_DTC" 0 "NOT_TESTED_DTC" ;
VAL_ 896 EPAS_d025_KFC_STORQUE_OC 3 "UNABLE_TO_TEST_DTC" 2 "FAILED_DTC" 1 "PASSED_DTC" 0 "NOT_TESTED_DTC" ;
VAL_ 896 EPAS_d026_KFC_STORQUE_RAD 3 "UNABLE_TO_TEST_DTC" 2 "FAILED_DTC" 1 "PASSED_DTC" 0 "NOT_TESTED_DTC" ;
VAL_ 896 EPAS_d027_KFC_FOR_TIMO 3 "UNABLE_TO_TEST_DTC" 2 "FAILED_DTC" 1 "PASSED_DTC" 0 "NOT_TESTED_DTC" ;
VAL_ 896 EPAS_d028_KFC_PROG_WD 3 "UNABLE_TO_TEST_DTC" 2 "FAILED_DTC" 1 "PASSED_DTC" 0 "NOT_TESTED_DTC" ;
VAL_ 896 EPAS_d029_KFC_CST 3 "UNABLE_TO_TEST_DTC" 2 "FAILED_DTC" 1 "PASSED_DTC" 0 "NOT_TESTED_DTC" ;
VAL_ 896 EPAS_d030_KFC_REG_CHECK 3 "UNABLE_TO_TEST_DTC" 2 "FAILED_DTC" 1 "PASSED_DTC" 0 "NOT_TESTED_DTC" ;
VAL_ 896 EPAS_d031_KFC_CR_RED 3 "UNABLE_TO_TEST_DTC" 2 "FAILED_DTC" 1 "PASSED_DTC" 0 "NOT_TESTED_DTC" ;
VAL_ 896 EPAS_d032_KFC_ROM 3 "UNABLE_TO_TEST_DTC" 2 "FAILED_DTC" 1 "PASSED_DTC" 0 "NOT_TESTED_DTC" ;
VAL_ 896 EPAS_d033_KFC_SWGEN 3 "UNABLE_TO_TEST_DTC" 2 "FAILED_DTC" 1 "PASSED_DTC" 0 "NOT_TESTED_DTC" ;
VAL_ 896 EPAS_d034_KFC_FOR_OC 3 "UNABLE_TO_TEST_DTC" 2 "FAILED_DTC" 1 "PASSED_DTC" 0 "NOT_TESTED_DTC" ;
VAL_ 896 EPAS_d035_KFC_FOR_WREL 3 "UNABLE_TO_TEST_DTC" 2 "FAILED_DTC" 1 "PASSED_DTC" 0 "NOT_TESTED_DTC" ;
VAL_ 896 EPAS_d036_KFC_FOR_ANGLE 3 "UNABLE_TO_TEST_DTC" 2 "FAILED_DTC" 1 "PASSED_DTC" 0 "NOT_TESTED_DTC" ;
VAL_ 896 EPAS_d037_KFC_FOR_LENGTH 3 "UNABLE_TO_TEST_DTC" 2 "FAILED_DTC" 1 "PASSED_DTC" 0 "NOT_TESTED_DTC" ;
VAL_ 896 EPAS_d038_KFC_BUS_OFF 3 "UNABLE_TO_TEST_DTC" 2 "FAILED_DTC" 1 "PASSED_DTC" 0 "NOT_TESTED_DTC" ;
VAL_ 896 EPAS_d039_KFC_RESET 3 "UNABLE_TO_TEST_DTC" 2 "FAILED_DTC" 1 "PASSED_DTC" 0 "NOT_TESTED_DTC" ;
VAL_ 896 EPAS_d040_KFC_RSRADIUS 3 "UNABLE_TO_TEST_DTC" 2 "FAILED_DTC" 1 "PASSED_DTC" 0 "NOT_TESTED_DTC" ;
VAL_ 896 EPAS_d041_KFC_U_REDUNDANT 3 "UNABLE_TO_TEST_DTC" 2 "FAILED_DTC" 1 "PASSED_DTC" 0 "NOT_TESTED_DTC" ;
VAL_ 896 EPAS_d042_KFC_RSDIFF 3 "UNABLE_TO_TEST_DTC" 2 "FAILED_DTC" 1 "PASSED_DTC" 0 "NOT_TESTED_DTC" ;
VAL_ 896 EPAS_d043_KFC_ESP_TIMO 3 "UNABLE_TO_TEST_DTC" 2 "FAILED_DTC" 1 "PASSED_DTC" 0 "NOT_TESTED_DTC" ;
VAL_ 896 EPAS_d044_KFC_GTW_TIMO 3 "UNABLE_TO_TEST_DTC" 2 "FAILED_DTC" 1 "PASSED_DTC" 0 "NOT_TESTED_DTC" ;
VAL_ 896 EPAS_d045_KFC_DI_Torque1_TIMO 3 "UNABLE_TO_TEST_DTC" 2 "FAILED_DTC" 1 "PASSED_DTC" 0 "NOT_TESTED_DTC" ;
VAL_ 896 EPAS_d046_KFC_SAS_TIMO 3 "UNABLE_TO_TEST_DTC" 2 "FAILED_DTC" 1 "PASSED_DTC" 0 "NOT_TESTED_DTC" ;
VAL_ 896 EPAS_d047_KFC_EACALLOW 3 "UNABLE_TO_TEST_DTC" 2 "FAILED_DTC" 1 "PASSED_DTC" 0 "NOT_TESTED_DTC" ;
VAL_ 896 EPAS_d048_KFC_EPB_TIMO 3 "UNABLE_TO_TEST_DTC" 2 "FAILED_DTC" 1 "PASSED_DTC" 0 "NOT_TESTED_DTC" ;
VAL_ 896 EPAS_d049_KFC_ESRA_CANCELLED 3 "UNABLE_TO_TEST_DTC" 2 "FAILED_DTC" 1 "PASSED_DTC" 0 "NOT_TESTED_DTC" ;
VAL_ 896 EPAS_d050_KFC_STEERING_ANGLE 3 "UNABLE_TO_TEST_DTC" 2 "FAILED_DTC" 1 "PASSED_DTC" 0 "NOT_TESTED_DTC" ;
VAL_ 896 EPAS_d051_KFC_VEHICLE_SPEED 3 "UNABLE_TO_TEST_DTC" 2 "FAILED_DTC" 1 "PASSED_DTC" 0 "NOT_TESTED_DTC" ;
VAL_ 896 EPAS_d052_KFC_UNUSED_52 3 "UNABLE_TO_TEST_DTC" 2 "FAILED_DTC" 1 "PASSED_DTC" 0 "NOT_TESTED_DTC" ;
VAL_ 896 EPAS_d053_KFC_UNUSED_53 3 "UNABLE_TO_TEST_DTC" 2 "FAILED_DTC" 1 "PASSED_DTC" 0 "NOT_TESTED_DTC" ;
VAL_ 896 EPAS_d054_KFC_CCF_NOT_CONFIGURED 3 "UNABLE_TO_TEST_DTC" 2 "FAILED_DTC" 1 "PASSED_DTC" 0 "NOT_TESTED_DTC" ;
VAL_ 896 EPAS_d055_KFC_CCF_INVALID 3 "UNABLE_TO_TEST_DTC" 2 "FAILED_DTC" 1 "PASSED_DTC" 0 "NOT_TESTED_DTC" ;
VAL_ 896 EPAS_d056_KFC_UNUSED_56 3 "UNABLE_TO_TEST_DTC" 2 "FAILED_DTC" 1 "PASSED_DTC" 0 "NOT_TESTED_DTC" ;
VAL_ 896 EPAS_d057_KFC_FRICTION 3 "UNABLE_TO_TEST_DTC" 2 "FAILED_DTC" 1 "PASSED_DTC" 0 "NOT_TESTED_DTC" ;
VAL_ 896 EPAS_d058_KFC_EXPULSION_MODE 3 "UNABLE_TO_TEST_DTC" 2 "FAILED_DTC" 1 "PASSED_DTC" 0 "NOT_TESTED_DTC" ;
VAL_ 896 EPAS_d059_KFC_TEMP_DIAG_DEV 3 "UNABLE_TO_TEST_DTC" 2 "FAILED_DTC" 1 "PASSED_DTC" 0 "NOT_TESTED_DTC" ;
VAL_ 896 EPAS_d060_KFC_POWER_MODE 3 "UNABLE_TO_TEST_DTC" 2 "FAILED_DTC" 1 "PASSED_DTC" 0 "NOT_TESTED_DTC" ;
VAL_ 896 EPAS_d061_KFC_UNUSED_61 3 "UNABLE_TO_TEST_DTC" 2 "FAILED_DTC" 1 "PASSED_DTC" 0 "NOT_TESTED_DTC" ;
VAL_ 896 EPAS_d062_KFC_WHEEL_SPEEDS 3 "UNABLE_TO_TEST_DTC" 2 "FAILED_DTC" 1 "PASSED_DTC" 0 "NOT_TESTED_DTC" ;
VAL_ 896 EPAS_d063_KFC_UNUSED_63 3 "UNABLE_TO_TEST_DTC" 2 "FAILED_DTC" 1 "PASSED_DTC" 0 "NOT_TESTED_DTC" ;
VAL_ 896 EPAS_d064_KFC_DI_MOTORRPM 3 "UNABLE_TO_TEST_DTC" 2 "FAILED_DTC" 1 "PASSED_DTC" 0 "NOT_TESTED_DTC" ;
VAL_ 896 EPAS_d065_KFC_YAW_RATE 3 "UNABLE_TO_TEST_DTC" 2 "FAILED_DTC" 1 "PASSED_DTC" 0 "NOT_TESTED_DTC" ;
VAL_ 896 EPAS_d066_KFC_UCU_RED_INFO 3 "UNABLE_TO_TEST_DTC" 2 "FAILED_DTC" 1 "PASSED_DTC" 0 "NOT_TESTED_DTC" ;
VAL_ 896 EPAS_d067_KFC_CCU_RED_INFO 3 "UNABLE_TO_TEST_DTC" 2 "FAILED_DTC" 1 "PASSED_DTC" 0 "NOT_TESTED_DTC" ;
VAL_ 896 EPAS_d068_KFC_UCO_RED_INFO 3 "UNABLE_TO_TEST_DTC" 2 "FAILED_DTC" 1 "PASSED_DTC" 0 "NOT_TESTED_DTC" ;
VAL_ 896 EPAS_d069_KFC_CR_RED_INFO 3 "UNABLE_TO_TEST_DTC" 2 "FAILED_DTC" 1 "PASSED_DTC" 0 "NOT_TESTED_DTC" ;
VAL_ 896 EPAS_d070_KFC_ROTANG 3 "UNABLE_TO_TEST_DTC" 2 "FAILED_DTC" 1 "PASSED_DTC" 0 "NOT_TESTED_DTC" ;
VAL_ 896 EPAS_d071_KFC_PD_RED 3 "UNABLE_TO_TEST_DTC" 2 "FAILED_DTC" 1 "PASSED_DTC" 0 "NOT_TESTED_DTC" ;
VAL_ 896 EPAS_d072_KFC_OS_MON 3 "UNABLE_TO_TEST_DTC" 2 "FAILED_DTC" 1 "PASSED_DTC" 0 "NOT_TESTED_DTC" ;
VAL_ 896 EPAS_d073_KFC_UCO_RED 3 "UNABLE_TO_TEST_DTC" 2 "FAILED_DTC" 1 "PASSED_DTC" 0 "NOT_TESTED_DTC" ;
VAL_ 896 EPAS_d074_KFC_SSW 3 "UNABLE_TO_TEST_DTC" 2 "FAILED_DTC" 1 "PASSED_DTC" 0 "NOT_TESTED_DTC" ;
VAL_ 896 EPAS_d075_KFC_BLOCKED_STEERING 3 "UNABLE_TO_TEST_DTC" 2 "FAILED_DTC" 1 "PASSED_DTC" 0 "NOT_TESTED_DTC" ;
VAL_ 896 EPAS_d076_KFC_DAS_TIMO 3 "UNABLE_TO_TEST_DTC" 2 "FAILED_DTC" 1 "PASSED_DTC" 0 "NOT_TESTED_DTC" ;
VAL_ 896 EPAS_d077_KFC_STEERING_CONTROL 3 "UNABLE_TO_TEST_DTC" 2 "FAILED_DTC" 1 "PASSED_DTC" 0 "NOT_TESTED_DTC" ;
VAL_ 1328 EPAS_infoIndex 255 "INFO_END" 20 "INFO_UDS_PROTOCOL_BOOTCRC" 19 "INFO_VERSION_DEPRECATED" 18 "INFO_BOOTLOADER_GITHASH" 17 "INFO_APP_GITHASH" 16 "INFO_SUBCOMPONENT" 15 "INFO_BOOTLOADER_CRC" 14 "INFO_BOOTLOADER_SVN" 13 "INFO_APP_CRC" 11 "INFO_PCBAID_ASSYID_USAGEID" 10 "INFO_BUILD_HWID_COMPONENTID" 9 "INFO_DEPRECATED_9" 8 "INFO_DEPRECATED_8" 7 "INFO_DEPRECATED_7" 6 "INFO_DEPRECATED_6" 5 "INFO_DEPRECATED_5" 4 "INFO_DEPRECATED_4" 3 "INFO_DEPRECATED_3" 2 "INFO_DEPRECATED_2" 1 "INFO_DEPRECATED_1" 0 "INFO_DEPRECATED_0" ;
VAL_ 880 EPAS_steeringRackForce 1023 "SNA" 1022 "NOT_IN_SPEC" ;
VAL_ 880 EPAS_steeringFault 1 "FAULT" 0 "NO_FAULT" ;
VAL_ 880 EPAS_steeringReduced 1 "REDUCED_ASSIST" 0 "NORMAL_ASSIST" ;
VAL_ 880 EPAS_currentTuneMode 7 "UNAVAILABLE" 6 "RWD_SPORT" 5 "RWD_STANDARD" 4 "RWD_COMFORT" 3 "DM_SPORT" 2 "DM_STANDARD" 1 "DM_COMFORT" 0 "FAIL_SAFE_DEFAULT" ;
VAL_ 880 EPAS_torsionBarTorque 4095 "SNA" 4094 "UNDEFINABLE_DATA" ;
VAL_ 880 EPAS_eacErrorCode 15 "SNA" 14 "EAC_EXTERNAL_MONITOR_INHIBIT" 13 "EAC_ERROR_PINION_VEL_DIFF" 12 "EAC_ERROR_LOW_ASSIST" 11 "EAC_ERROR_HIGH_TORSION_SAFETY" 10 "EAC_ERROR_HIGH_MMOT_SAFETY" 9 "EAC_ERROR_HIGH_ANGLE_RATE_SAFETY" 8 "EAC_ERROR_HIGH_ANGLE_SAFETY" 7 "EAC_ERROR_HIGH_ANGLE_RATE_REQ" 6 "EAC_ERROR_HIGH_ANGLE_REQ" 5 "EAR_ERROR_MAX_STEER_DELTA" 4 "EAC_ERROR_TMP_FAULT" 3 "EAC_ERROR_HANDS_ON" 2 "EAC_ERROR_MAX_SPEED" 1 "EAC_ERROR_MIN_SPEED" 0 "EAC_ERROR_IDLE" ;
VAL_ 880 EPAS_handsOnLevel 3 "LEVEL_3" 2 "LEVEL_2" 1 "LEVEL_1" 0 "LEVEL_0" ;
VAL_ 880 EPAS_eacStatus 7 "EAC_ELK_ACTIVE" 6 "EAC_ELK_AVAILABLE" 5 "EAC_LKA_ACTIVE" 4 "EAC_LKA_ELK_AVAILABLE" 3 "EAC_FAULT" 2 "EAC_ACTIVE" 1 "EAC_AVAILABLE" 0 "EAC_INHIBITED" ;
SIG_GROUP_ 1 EIS_Stat 1 : AutoDrLk_Rq_Src AutoDrLk_Stat CLkS_DL_Stat CLkS_Dr_FL_Stat CLkS_Dr_FR_Stat CLkS_Dr_RL_Stat CLkS_Dr_RR_Stat CLkS_Gas_Dr_Stat CLkS_Lk_Stat3 CRC_EIS_A1 EngSt_Enbl_Rq_KG ISw_Stat Ign_On_StProc_Inact KG_IgnCtrl_Actv KG_StSw_Psd KeyLine1_Appr KeyLine2_Appr KeyLine3_Appr KeyLine4_Appr KeyLine5_Appr KeyLine6_Appr KeyLine7_Appr KeyLine8_Appr MC_EIS_A1 SPCR_AcustWarn_Rq_EIS SPCR_Conf_EIS TxPkPosnAuto_Enbl TxPkPosn_Emg_Rq TxPkPosn_Rq TxPkPosn_Rq_SBC_Enbl;
